VERSION "HNNBNNNYNNNNNNNNNNNNNNNNNNNNNNNNNNNNNNNNNN/4/%%%/4/'%**4NNN///"

NS_ :

BS_:

BU_: AWC BAP_Tester BMC_MLBevo BMS_MV BMS_NV DCDC_800V_PAG DCDC_HV DCDC_HV_02 DCDC_IHEV FCU_MLBevo_FCEV Gateway Gateway_PAG Ladegeraet_2 Ladegeraet_Konzern LE1 LE2 LE2_3_MLBevo_LB LE_MLBevo LE_MLBevo_LB Sub_Gateway TME

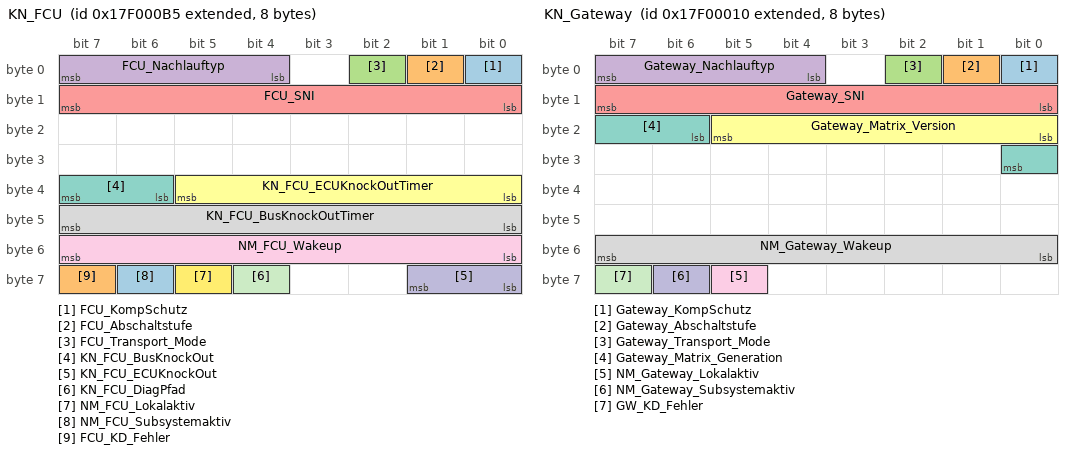
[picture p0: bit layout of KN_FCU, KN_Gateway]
BO_ 2549088437 KN_FCU: 8 FCU_MLBevo_FCEV
 SG_ FCU_KompSchutz : 0|1@1+ (1,0) [0|1] "" Vector__XXX
 SG_ FCU_Abschaltstufe : 1|1@1+ (1,0) [0|1] "" Vector__XXX
 SG_ FCU_Transport_Mode : 2|1@1+ (1,0) [0|1] "" Vector__XXX
 SG_ FCU_Nachlauftyp : 4|4@1+ (1,0) [0|15] ""  Gateway
 SG_ FCU_SNI : 8|8@1+ (1,0) [0|255] ""  Gateway
 SG_ KN_FCU_ECUKnockOutTimer : 32|6@1+ (1,0) [0|62] "Unit_Minut"  Gateway
 SG_ KN_FCU_BusKnockOut : 38|2@1+ (1,0) [0|3] ""  Gateway
 SG_ KN_FCU_BusKnockOutTimer : 40|8@1+ (1,0) [0|254] ""  Gateway
 SG_ NM_FCU_Wakeup : 48|8@1+ (1,0) [0|255] "" Vector__XXX
 SG_ KN_FCU_ECUKnockOut : 56|2@1+ (1,0) [0|3] ""  Gateway
 SG_ KN_FCU_DiagPfad : 60|1@1+ (1,0) [0|1] "" Vector__XXX
 SG_ NM_FCU_Lokalaktiv : 61|1@1+ (1,0) [0|1] ""  Gateway
 SG_ NM_FCU_Subsystemaktiv : 62|1@1+ (1,0) [0|1] ""  Gateway
 SG_ FCU_KD_Fehler : 63|1@1+ (1,0) [0|1] ""  Gateway

BO_ 2549088272 KN_Gateway: 8 Gateway
 SG_ Gateway_KompSchutz : 0|1@1+ (1,0) [0|1] "" Vector__XXX
 SG_ Gateway_Abschaltstufe : 1|1@1+ (1,0) [0|1] "" Vector__XXX
 SG_ Gateway_Transport_Mode : 2|1@1+ (1,0) [0|1] "" Vector__XXX
 SG_ Gateway_Nachlauftyp : 4|4@1+ (1,0) [0|15] "" Vector__XXX
 SG_ Gateway_SNI : 8|8@1+ (1,0) [0|255] "" Vector__XXX
 SG_ Gateway_Matrix_Version : 16|6@1+ (1,0) [0|63] "Unit_None" Vector__XXX
 SG_ Gateway_Matrix_Generation : 22|3@1+ (1,0) [0|7] "Unit_None" Vector__XXX
 SG_ NM_Gateway_Wakeup : 48|8@1+ (1,0) [0|255] "" Vector__XXX
 SG_ NM_Gateway_Lokalaktiv : 61|1@1+ (1,0) [0|1] "" Vector__XXX
 SG_ NM_Gateway_Subsystemaktiv : 62|1@1+ (1,0) [0|1] "" Vector__XXX
 SG_ GW_KD_Fehler : 63|1@1+ (1,0) [0|1] "" Vector__XXX

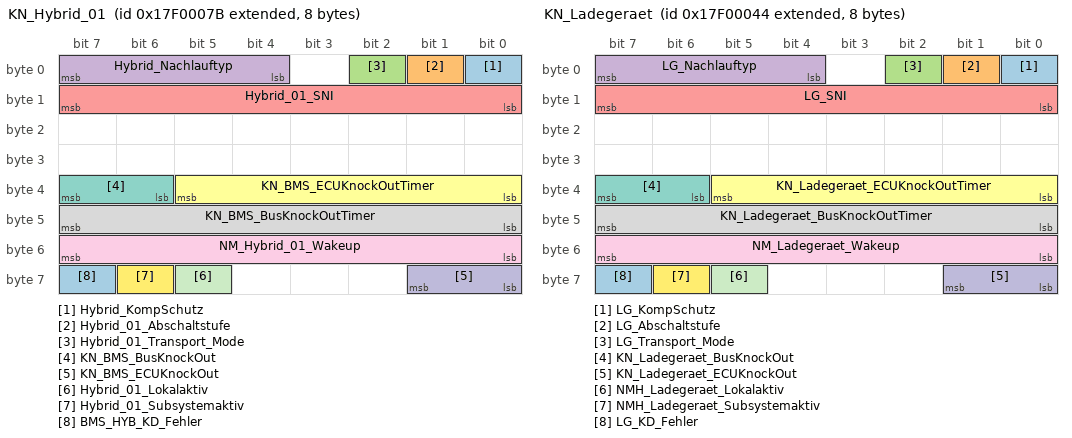
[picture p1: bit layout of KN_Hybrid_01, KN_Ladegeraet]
BO_ 2549088379 KN_Hybrid_01: 8 BMC_MLBevo
 SG_ Hybrid_KompSchutz : 0|1@1+ (1,0) [0|1] "" Vector__XXX
 SG_ Hybrid_01_Abschaltstufe : 1|1@1+ (1,0) [0|1] "" Vector__XXX
 SG_ Hybrid_01_Transport_Mode : 2|1@1+ (1,0) [0|1] "" Vector__XXX
 SG_ Hybrid_Nachlauftyp : 4|4@1+ (1,0) [0|15] ""  Gateway,Gateway_PAG
 SG_ Hybrid_01_SNI : 8|8@1+ (1,0) [0|255] ""  Gateway,Gateway_PAG
 SG_ KN_BMS_ECUKnockOutTimer : 32|6@1+ (1,0) [0|62] "Unit_Minut" Vector__XXX
 SG_ KN_BMS_BusKnockOut : 38|2@1+ (1,0) [0|3] "" Vector__XXX
 SG_ KN_BMS_BusKnockOutTimer : 40|8@1+ (1,0) [0|254] ""  Gateway,Gateway_PAG
 SG_ NM_Hybrid_01_Wakeup : 48|8@1+ (1,0) [0|255] "" Vector__XXX
 SG_ KN_BMS_ECUKnockOut : 56|2@1+ (1,0) [0|3] "" Vector__XXX
 SG_ Hybrid_01_Lokalaktiv : 61|1@1+ (1,0) [0|1] ""  Gateway,Gateway_PAG
 SG_ Hybrid_01_Subsystemaktiv : 62|1@1+ (1,0) [0|1] ""  Gateway,Gateway_PAG
 SG_ BMS_HYB_KD_Fehler : 63|1@1+ (1,0) [0|1] ""  Gateway,Gateway_PAG

BO_ 2549088324 KN_Ladegeraet: 8 Ladegeraet_Konzern
 SG_ LG_KompSchutz : 0|1@1+ (1,0) [0|1] "" Vector__XXX
 SG_ LG_Abschaltstufe : 1|1@1+ (1,0) [0|1] "" Vector__XXX
 SG_ LG_Transport_Mode : 2|1@1+ (1,0) [0|1] "" Vector__XXX
 SG_ LG_Nachlauftyp : 4|4@1+ (1,0) [0|15] ""  Gateway,Gateway_PAG
 SG_ LG_SNI : 8|8@1+ (1,0) [0|255] ""  Gateway,Gateway_PAG
 SG_ KN_Ladegeraet_ECUKnockOutTimer : 32|6@1+ (1,0) [0|62] "Unit_Minut"  Gateway
 SG_ KN_Ladegeraet_BusKnockOut : 38|2@1+ (1,0) [0|3] ""  Gateway
 SG_ KN_Ladegeraet_BusKnockOutTimer : 40|8@1+ (1,0) [0|254] ""  Gateway,Gateway_PAG
 SG_ NM_Ladegeraet_Wakeup : 48|8@1+ (1,0) [0|255] "" Vector__XXX
 SG_ KN_Ladegeraet_ECUKnockOut : 56|2@1+ (1,0) [0|3] ""  Gateway
 SG_ NMH_Ladegeraet_Lokalaktiv : 61|1@1+ (1,0) [0|1] ""  Gateway,Gateway_PAG
 SG_ NMH_Ladegeraet_Subsystemaktiv : 62|1@1+ (1,0) [0|1] "" Vector__XXX
 SG_ LG_KD_Fehler : 63|1@1+ (1,0) [0|1] ""  Gateway,Gateway_PAG

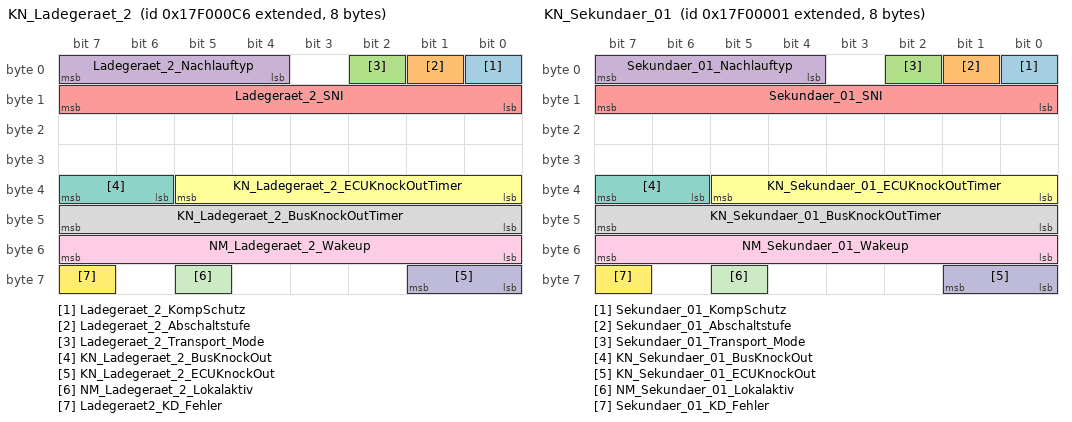
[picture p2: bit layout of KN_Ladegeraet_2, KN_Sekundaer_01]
BO_ 2549088454 KN_Ladegeraet_2: 8 Ladegeraet_2
 SG_ Ladegeraet_2_KompSchutz : 0|1@1+ (1,0) [0|1] "" Vector__XXX
 SG_ Ladegeraet_2_Abschaltstufe : 1|1@1+ (1,0) [0|1] "" Vector__XXX
 SG_ Ladegeraet_2_Transport_Mode : 2|1@1+ (1,0) [0|1] "" Vector__XXX
 SG_ Ladegeraet_2_Nachlauftyp : 4|4@1+ (1,0) [0|15] ""  Gateway,Gateway_PAG
 SG_ Ladegeraet_2_SNI : 8|8@1+ (1,0) [0|255] ""  Gateway,Gateway_PAG
 SG_ KN_Ladegeraet_2_ECUKnockOutTimer : 32|6@1+ (1,0) [0|62] "Unit_Minut" Vector__XXX
 SG_ KN_Ladegeraet_2_BusKnockOut : 38|2@1+ (1,0) [0|3] "" Vector__XXX
 SG_ KN_Ladegeraet_2_BusKnockOutTimer : 40|8@1+ (1,0) [0|254] ""  Gateway
 SG_ NM_Ladegeraet_2_Wakeup : 48|8@1+ (1,0) [0|255] "" Vector__XXX
 SG_ KN_Ladegeraet_2_ECUKnockOut : 56|2@1+ (1,0) [0|3] "" Vector__XXX
 SG_ NM_Ladegeraet_2_Lokalaktiv : 61|1@1+ (1,0) [0|1] ""  Gateway,Gateway_PAG
 SG_ Ladegeraet2_KD_Fehler : 63|1@1+ (1,0) [0|1] ""  Gateway,Gateway_PAG

BO_ 2549088257 KN_Sekundaer_01: 8 LE2
 SG_ Sekundaer_01_KompSchutz : 0|1@1+ (1,0) [0|1] "" Vector__XXX
 SG_ Sekundaer_01_Abschaltstufe : 1|1@1+ (1,0) [0|1] "" Vector__XXX
 SG_ Sekundaer_01_Transport_Mode : 2|1@1+ (1,0) [0|1] "" Vector__XXX
 SG_ Sekundaer_01_Nachlauftyp : 4|4@1+ (1,0) [0|15] ""  Gateway,Gateway_PAG
 SG_ Sekundaer_01_SNI : 8|8@1+ (1,0) [0|255] ""  Gateway,Gateway_PAG
 SG_ KN_Sekundaer_01_ECUKnockOutTimer : 32|6@1+ (1,0) [0|62] "Unit_Minut"  Gateway,Gateway_PAG
 SG_ KN_Sekundaer_01_BusKnockOut : 38|2@1+ (1,0) [0|3] ""  Gateway,Gateway_PAG
 SG_ KN_Sekundaer_01_BusKnockOutTimer : 40|8@1+ (1,0) [0|254] ""  Gateway,Gateway_PAG
 SG_ NM_Sekundaer_01_Wakeup : 48|8@1+ (1,0) [0|255] "" Vector__XXX
 SG_ KN_Sekundaer_01_ECUKnockOut : 56|2@1+ (1,0) [0|3] ""  Gateway,Gateway_PAG
 SG_ NM_Sekundaer_01_Lokalaktiv : 61|1@1+ (1,0) [0|1] ""  Gateway
 SG_ Sekundaer_01_KD_Fehler : 63|1@1+ (1,0) [0|1] ""  Gateway,Gateway_PAG

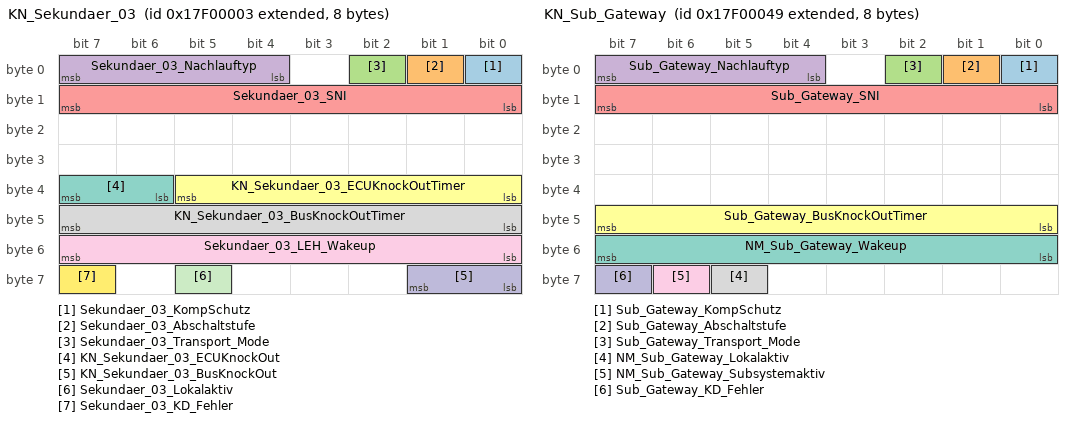
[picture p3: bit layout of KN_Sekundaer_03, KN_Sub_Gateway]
BO_ 2549088259 KN_Sekundaer_03: 8 LE1
 SG_ Sekundaer_03_KompSchutz : 0|1@1+ (1,0) [0|1] "" Vector__XXX
 SG_ Sekundaer_03_Abschaltstufe : 1|1@1+ (1,0) [0|1] "" Vector__XXX
 SG_ Sekundaer_03_Transport_Mode : 2|1@1+ (1,0) [0|1] "" Vector__XXX
 SG_ Sekundaer_03_Nachlauftyp : 4|4@1+ (1,0) [0|15] ""  Gateway,Gateway_PAG
 SG_ Sekundaer_03_SNI : 8|8@1+ (1,0) [0|255] ""  Gateway,Gateway_PAG
 SG_ KN_Sekundaer_03_ECUKnockOutTimer : 32|6@1+ (1,0) [0|62] "Unit_Minut"  Gateway,Gateway_PAG
 SG_ KN_Sekundaer_03_ECUKnockOut : 38|2@1+ (1,0) [0|3] ""  Gateway,Gateway_PAG
 SG_ KN_Sekundaer_03_BusKnockOutTimer : 40|8@1+ (1,0) [0|254] ""  Gateway,Gateway_PAG
 SG_ Sekundaer_03_LEH_Wakeup : 48|8@1+ (1,0) [0|255] "" Vector__XXX
 SG_ KN_Sekundaer_03_BusKnockOut : 56|2@1+ (1,0) [0|3] ""  Gateway,Gateway_PAG
 SG_ Sekundaer_03_Lokalaktiv : 61|1@1+ (1,0) [0|1] ""  Gateway
 SG_ Sekundaer_03_KD_Fehler : 63|1@1+ (1,0) [0|1] ""  Gateway,Gateway_PAG

BO_ 2549088329 KN_Sub_Gateway: 8 Sub_Gateway
 SG_ Sub_Gateway_KompSchutz : 0|1@1+ (1,0) [0|1] "" Vector__XXX
 SG_ Sub_Gateway_Abschaltstufe : 1|1@1+ (1,0) [0|1] "" Vector__XXX
 SG_ Sub_Gateway_Transport_Mode : 2|1@1+ (1,0) [0|1] "" Vector__XXX
 SG_ Sub_Gateway_Nachlauftyp : 4|4@1+ (1,0) [0|15] ""  Gateway,Gateway_PAG
 SG_ Sub_Gateway_SNI : 8|8@1+ (1,0) [0|255] ""  Gateway,Gateway_PAG
 SG_ Sub_Gateway_BusKnockOutTimer : 40|8@1+ (1,0) [0|254] "" Vector__XXX
 SG_ NM_Sub_Gateway_Wakeup : 48|8@1+ (1,0) [0|255] "" Vector__XXX
 SG_ NM_Sub_Gateway_Lokalaktiv : 61|1@1+ (1,0) [0|1] ""  Gateway
 SG_ NM_Sub_Gateway_Subsystemaktiv : 62|1@1+ (1,0) [0|1] ""  Gateway
 SG_ Sub_Gateway_KD_Fehler : 63|1@1+ (1,0) [0|1] ""  Gateway,Gateway_PAG

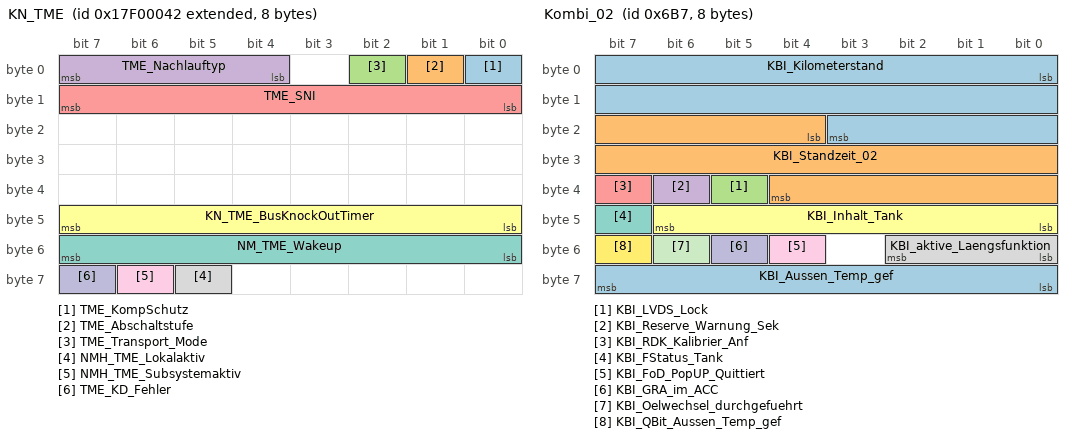
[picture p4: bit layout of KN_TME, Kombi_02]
BO_ 2549088322 KN_TME: 8 TME
 SG_ TME_KompSchutz : 0|1@1+ (1,0) [0|1] "" Vector__XXX
 SG_ TME_Abschaltstufe : 1|1@1+ (1,0) [0|1] "" Vector__XXX
 SG_ TME_Transport_Mode : 2|1@1+ (1,0) [0|1] "" Vector__XXX
 SG_ TME_Nachlauftyp : 4|4@1+ (1,0) [0|15] ""  Gateway,Gateway_PAG
 SG_ TME_SNI : 8|8@1+ (1,0) [0|255] ""  Gateway,Gateway_PAG
 SG_ KN_TME_BusKnockOutTimer : 40|8@1+ (1,0) [0|254] ""  Gateway,Gateway_PAG
 SG_ NM_TME_Wakeup : 48|8@1+ (1,0) [0|255] "" Vector__XXX
 SG_ NMH_TME_Lokalaktiv : 61|1@1+ (1,0) [0|1] ""  Gateway,Gateway_PAG
 SG_ NMH_TME_Subsystemaktiv : 62|1@1+ (1,0) [0|1] ""  Gateway,Gateway_PAG
 SG_ TME_KD_Fehler : 63|1@1+ (1,0) [0|1] ""  Gateway,Gateway_PAG

BO_ 779 Kombi_01: 8 Gateway
 SG_ KBI_ABS_Lampe : 0|1@1+ (1,0) [0|1] "" Vector__XXX
 SG_ KBI_ESP_Lampe : 1|1@1+ (1,0) [0|1] "" Vector__XXX
 SG_ KBI_BKL_Lampe : 2|1@1+ (1,0) [0|1] "" Vector__XXX
 SG_ KBI_Airbag_Lampe : 3|1@1+ (1,0) [0|1] "" Vector__XXX
 SG_ KBI_SILA_gueltig : 4|1@1+ (1,0) [0|1] "" Vector__XXX
 SG_ KBI_Lenkung_Lampe : 5|1@1+ (1,0) [0|1] "" Vector__XXX
 SG_ KBI_Vorglueh_System_Lampe : 6|1@1+ (1,0) [0|1] "" Vector__XXX
 SG_ KBI_NV_in_Anzeige : 7|1@1+ (1,0) [0|1] "" Vector__XXX
 SG_ Kombi_01_BZ : 8|4@1+ (1,0) [0|15] "" Vector__XXX
 SG_ KBI_Anzeigestatus_ACC : 12|1@1+ (1,0) [0|1] "" Vector__XXX
 SG_ KBI_Anzeigestatus_GRA : 13|2@1+ (1,0) [0|3] "" Vector__XXX
 SG_ KBI_Tankwarnung : 16|1@1+ (1,0) [0|1] ""  TME
 SG_ KBI_MFA_v_Einheit_01 : 17|1@1+ (1,0) [0|1] "" Vector__XXX
 SG_ KBI_im_Stellgliedtest : 18|1@1+ (1,0) [0|1] "" Vector__XXX
 SG_ KBI_Anzeigefehler_LDW : 19|2@1+ (1,0) [0|3] "" Vector__XXX
 SG_ KBI_Tankwarnung_ungueltig : 21|1@1+ (1,0) [0|1] "" Vector__XXX
 SG_ KBI_Handbremse : 23|1@1+ (1,0) [0|1] "" Vector__XXX
 SG_ KBI_V_Digital : 24|9@1+ (1,0) [0|511] "" Vector__XXX
 SG_ KBI_PLA_in_Anzeige : 33|1@1+ (1,0) [0|1] "" Vector__XXX
 SG_ KBI_Anzeigefehler_NV : 34|1@1+ (1,0) [0|1] "" Vector__XXX
 SG_ KBI_Anzeigestatus_LIM : 35|2@1+ (1,0) [0|3] "" Vector__XXX
 SG_ KBI_ARA_in_Anzeige : 37|1@1+ (1,0) [0|1] "" Vector__XXX
 SG_ KBI_Taster_Lift : 38|1@1+ (1,0) [0|1] "" Vector__XXX
 SG_ KBI_Taster_Fahrwerk : 39|1@1+ (1,0) [0|1] "" Vector__XXX
 SG_ KBI_angez_Geschw : 48|10@1+ (0.32,0) [0|325.12] "Unit_KiloMeterPerHour" Vector__XXX
 SG_ KBI_Einheit_Tacho : 58|1@1+ (1,0) [0|1] "" Vector__XXX
 SG_ KBI_Konsistenz_ACC : 59|1@1+ (1,0) [0|1] "" Vector__XXX
 SG_ KBI_Fehler_Anzeige_ACC : 60|1@1+ (1,0) [0|1] "" Vector__XXX
 SG_ KBI_Anzeigefehler_SWA : 61|2@1+ (1,0) [0|3] "" Vector__XXX
 SG_ KBI_Systemstatus : 63|1@1+ (1,0) [0|1] "" Vector__XXX

BO_ 1719 Kombi_02: 8 Gateway
 SG_ KBI_Kilometerstand : 0|20@1+ (1,0) [0|1048573] "Unit_KiloMeter"  Sub_Gateway
 SG_ KBI_Standzeit_02 : 20|17@1+ (1,0) [0|131068] "Unit_Secon"  Sub_Gateway,TME
 SG_ KBI_LVDS_Lock : 37|1@1+ (1,0) [0|1] ""  Sub_Gateway
 SG_ KBI_Reserve_Warnung_Sek : 38|1@1+ (1,0) [0|1] ""  Sub_Gateway
 SG_ KBI_RDK_Kalibrier_Anf : 39|1@1+ (1,0) [0|1] ""  Sub_Gateway
 SG_ KBI_Inhalt_Tank : 40|7@1+ (1,0) [0|125] "Unit_Liter"  Sub_Gateway
 SG_ KBI_FStatus_Tank : 47|1@1+ (1,0) [0|1] ""  Sub_Gateway
 SG_ KBI_aktive_Laengsfunktion : 48|3@1+ (1,0) [0|7] ""  Sub_Gateway
 SG_ KBI_FoD_PopUP_Quittiert : 52|1@1+ (1,0) [0|1] ""  Sub_Gateway
 SG_ KBI_GRA_im_ACC : 53|1@1+ (1,0) [0|1] ""  Sub_Gateway
 SG_ KBI_Oelwechsel_durchgefuehrt : 54|1@1+ (1,0) [0|1] ""  Sub_Gateway
 SG_ KBI_QBit_Aussen_Temp_gef : 55|1@1+ (1,0) [0|1] ""  AWC,Sub_Gateway
 SG_ KBI_Aussen_Temp_gef : 56|8@1+ (0.5,-50) [-50|75] "Unit_DegreCelsi"  AWC,Ladegeraet_Konzern,Sub_Gateway

BO_ 2549875067 KS_Hybrid_01_Req: 8 Gateway
 SG_ KS_Hybrid_01_Req_Data : 0|64@1+ (1,0) [0|1.84467440737096E+019] ""  BMC_MLBevo

BO_ 2550006139 KS_Hybrid_01_Resp: 8 BMC_MLBevo
 SG_ KS_Hybrid_01_Resp_Data : 0|64@1+ (1,0) [0|1.84467440737096E+019] ""  Gateway,Gateway_PAG

BO_ 2549875142 KS_Ladegeraet_2_Req: 8 Gateway
 SG_ KS_Ladegeraet_2_Req_Data : 0|64@1+ (1,0) [0|1.84467440737096E+019] ""  Ladegeraet_2

BO_ 2550006214 KS_Ladegeraet_2_Resp: 8 Ladegeraet_2
 SG_ KS_Ladegeraet_2_Resp_Data : 0|64@1+ (1,0) [0|1.84467440737096E+019] ""  Gateway,Gateway_PAG

BO_ 2549875012 KS_Ladegeraet_Req: 8 Gateway
 SG_ KS_Ladegeraet_Req_Data : 0|64@1+ (1,0) [0|1.84467440737096E+019] ""  Ladegeraet_Konzern

BO_ 2550006084 KS_Ladegeraet_Resp: 8 Ladegeraet_Konzern
 SG_ KS_Ladegeraet_Resp_Data : 0|64@1+ (1,0) [0|1.84467440737096E+019] ""  Gateway,Gateway_PAG

BO_ 2549899473 KS_SSN_CMC_01_Req: 8 Gateway
 SG_ KS_SSN_CMC_01_Req_Data : 0|64@1+ (1,0) [0|1.84467440737096E+019] ""  BMC_MLBevo

BO_ 2550030545 KS_SSN_CMC_01_Resp: 8 BMC_MLBevo
 SG_ KS_SSN_CMC_01_Resp_Data : 0|64@1+ (1,0) [0|1.84467440737096E+019] ""  Gateway

BO_ 2549899474 KS_SSN_CMC_02_Req: 8 Gateway
 SG_ KS_SSN_CMC_02_Req_Data : 0|64@1+ (1,0) [0|1.84467440737096E+019] ""  BMC_MLBevo

BO_ 2550030546 KS_SSN_CMC_02_Resp: 8 BMC_MLBevo
 SG_ KS_SSN_CMC_02_Resp_Data : 0|64@1+ (1,0) [0|1.84467440737096E+019] ""  Gateway

BO_ 2549899475 KS_SSN_CMC_03_Req: 8 Gateway
 SG_ KS_SSN_CMC_03_Req_Data : 0|64@1+ (1,0) [0|1.84467440737096E+019] ""  BMC_MLBevo

BO_ 2550030547 KS_SSN_CMC_03_Resp: 8 BMC_MLBevo
 SG_ KS_SSN_CMC_03_Resp_Data : 0|64@1+ (1,0) [0|1.84467440737096E+019] ""  Gateway

BO_ 2549899476 KS_SSN_CMC_04_Req: 8 Gateway
 SG_ KS_SSN_CMC_04_Req_Data : 0|64@1+ (1,0) [0|1.84467440737096E+019] ""  BMC_MLBevo

BO_ 2550030548 KS_SSN_CMC_04_Resp: 8 BMC_MLBevo
 SG_ KS_SSN_CMC_04_Resp_Data : 0|64@1+ (1,0) [0|1.84467440737096E+019] ""  Gateway

BO_ 2549899477 KS_SSN_CMC_05_Req: 8 Gateway
 SG_ KS_SSN_CMC_05_Req_Data : 0|64@1+ (1,0) [0|1.84467440737096E+019] ""  BMC_MLBevo

BO_ 2550030549 KS_SSN_CMC_05_Resp: 8 BMC_MLBevo
 SG_ KS_SSN_CMC_05_Resp_Data : 0|64@1+ (1,0) [0|1.84467440737096E+019] ""  Gateway

BO_ 2549899478 KS_SSN_CMC_06_Req: 8 Gateway
 SG_ KS_SSN_CMC_06_Req_Data : 0|64@1+ (1,0) [0|1.84467440737096E+019] ""  BMC_MLBevo

BO_ 2550030550 KS_SSN_CMC_06_Resp: 8 BMC_MLBevo
 SG_ KS_SSN_CMC_06_Resp_Data : 0|64@1+ (1,0) [0|1.84467440737096E+019] ""  Gateway

BO_ 2549899479 KS_SSN_CMC_07_Req: 8 Gateway
 SG_ KS_SSN_CMC_07_Req_Data : 0|64@1+ (1,0) [0|1.84467440737096E+019] ""  BMC_MLBevo

BO_ 2550030551 KS_SSN_CMC_07_Resp: 8 BMC_MLBevo
 SG_ KS_SSN_CMC_07_Resp_Data : 0|64@1+ (1,0) [0|1.84467440737096E+019] ""  Gateway

BO_ 2549899480 KS_SSN_CMC_08_Req: 8 Gateway
 SG_ KS_SSN_CMC_08_Req_Data : 0|64@1+ (1,0) [0|1.84467440737096E+019] ""  BMC_MLBevo

BO_ 2550030552 KS_SSN_CMC_08_Resp: 8 BMC_MLBevo
 SG_ KS_SSN_CMC_08_Resp_Data : 0|64@1+ (1,0) [0|1.84467440737096E+019] ""  Gateway

BO_ 2549899481 KS_SSN_CMC_09_Req: 8 Gateway
 SG_ KS_SSN_CMC_09_Req_Data : 0|64@1+ (1,0) [0|1.84467440737096E+019] ""  BMC_MLBevo

BO_ 2550030553 KS_SSN_CMC_09_Resp: 8 BMC_MLBevo
 SG_ KS_SSN_CMC_09_Resp_Data : 0|64@1+ (1,0) [0|1.84467440737096E+019] ""  Gateway

BO_ 2549899482 KS_SSN_CMC_10_Req: 8 Gateway
 SG_ KS_SSN_CMC_10_Req_Data : 0|64@1+ (1,0) [0|1.84467440737096E+019] ""  BMC_MLBevo

BO_ 2550030554 KS_SSN_CMC_10_Resp: 8 BMC_MLBevo
 SG_ KS_SSN_CMC_10_Resp_Data : 0|64@1+ (1,0) [0|1.84467440737096E+019] ""  Gateway

BO_ 2549899483 KS_SSN_CMC_11_Req: 8 Gateway
 SG_ KS_SSN_CMC_11_Req_Data : 0|64@1+ (1,0) [0|1.84467440737096E+019] ""  BMC_MLBevo

BO_ 2550030555 KS_SSN_CMC_11_Resp: 8 BMC_MLBevo
 SG_ KS_SSN_CMC_11_Resp_Data : 0|64@1+ (1,0) [0|1.84467440737096E+019] ""  Gateway

BO_ 2549899484 KS_SSN_CMC_12_Req: 8 Gateway
 SG_ KS_SSN_CMC_12_Req_Data : 0|64@1+ (1,0) [0|1.84467440737096E+019] ""  BMC_MLBevo

BO_ 2550030556 KS_SSN_CMC_12_Resp: 8 BMC_MLBevo
 SG_ KS_SSN_CMC_12_Resp_Data : 0|64@1+ (1,0) [0|1.84467440737096E+019] ""  Gateway

BO_ 2549899505 KS_SSN_CMC_13_Req: 8 Gateway
 SG_ KS_SSN_CMC_13_Req_Data : 0|64@1+ (1,0) [0|1.84467440737096E+019] ""  BMC_MLBevo

BO_ 2550030577 KS_SSN_CMC_13_Resp: 8 BMC_MLBevo
 SG_ KS_SSN_CMC_13_Resp_Data : 0|64@1+ (1,0) [0|1.84467440737096E+019] ""  Gateway

BO_ 2549899506 KS_SSN_CMC_14_Req: 8 Gateway
 SG_ KS_SSN_CMC_14_Req_Data : 0|64@1+ (1,0) [0|1.84467440737096E+019] ""  BMC_MLBevo

BO_ 2550030578 KS_SSN_CMC_14_Resp: 8 BMC_MLBevo
 SG_ KS_SSN_CMC_14_Resp_Data : 0|64@1+ (1,0) [0|1.84467440737096E+019] ""  Gateway

BO_ 2549899507 KS_SSN_CMC_15_Req: 8 Gateway
 SG_ KS_SSN_CMC_15_Req_Data : 0|64@1+ (1,0) [0|1.84467440737096E+019] ""  BMC_MLBevo

BO_ 2550030579 KS_SSN_CMC_15_Resp: 8 BMC_MLBevo
 SG_ KS_SSN_CMC_15_Resp_Data : 0|64@1+ (1,0) [0|1.84467440737096E+019] ""  Gateway

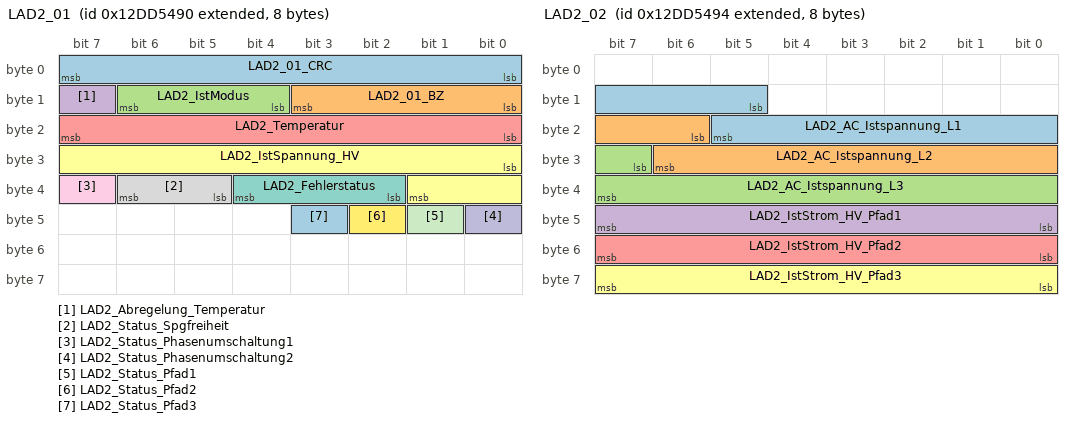
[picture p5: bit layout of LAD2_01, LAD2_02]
BO_ 2463978640 LAD2_01: 8 Ladegeraet_2
 SG_ LAD2_01_CRC : 0|8@1+ (1,0) [0|255] ""  Gateway,Gateway_PAG,Ladegeraet_Konzern
 SG_ LAD2_01_BZ : 8|4@1+ (1,0) [0|15] ""  Gateway,Gateway_PAG,Ladegeraet_Konzern
 SG_ LAD2_IstModus : 12|3@1+ (1,0) [0|7] ""  Ladegeraet_Konzern
 SG_ LAD2_Abregelung_Temperatur : 15|1@1+ (1,0) [0|1] ""  Ladegeraet_Konzern
 SG_ LAD2_Temperatur : 16|8@1+ (1,-40) [-40|213] "Unit_DegreCelsi"  Ladegeraet_Konzern
 SG_ LAD2_IstSpannung_HV : 24|10@1+ (1,0) [0|1021] "Unit_Volt"  Gateway,Gateway_PAG,Ladegeraet_Konzern
 SG_ LAD2_Fehlerstatus : 34|3@1+ (1,0) [0|7] ""  Gateway,Gateway_PAG,Ladegeraet_Konzern
 SG_ LAD2_Status_Spgfreiheit : 37|2@1+ (1,0) [0|3] ""  Gateway,Gateway_PAG,Ladegeraet_Konzern
 SG_ LAD2_Status_Phasenumschaltung1 : 39|1@1+ (1,0) [0|1] ""  Ladegeraet_Konzern
 SG_ LAD2_Status_Phasenumschaltung2 : 40|1@1+ (1,0) [0|1] ""  Ladegeraet_Konzern
 SG_ LAD2_Status_Pfad1 : 41|1@1+ (1,0) [0|1] ""  Ladegeraet_Konzern
 SG_ LAD2_Status_Pfad2 : 42|1@1+ (1,0) [0|1] ""  Ladegeraet_Konzern
 SG_ LAD2_Status_Pfad3 : 43|1@1+ (1,0) [0|1] ""  Ladegeraet_Konzern

BO_ 2463978644 LAD2_02: 8 Ladegeraet_2
 SG_ LAD2_AC_Istspannung_L1 : 13|9@1+ (1,0) [0|509] "Unit_Volt"  Ladegeraet_Konzern
 SG_ LAD2_AC_Istspannung_L2 : 22|9@1+ (1,0) [0|509] "Unit_Volt"  Ladegeraet_Konzern
 SG_ LAD2_AC_Istspannung_L3 : 31|9@1+ (1,0) [0|509] "Unit_Volt"  Ladegeraet_Konzern
 SG_ LAD2_IstStrom_HV_Pfad1 : 40|8@1+ (0.1,0) [0|25.3] "Unit_Amper"  Ladegeraet_Konzern
 SG_ LAD2_IstStrom_HV_Pfad2 : 48|8@1+ (0.1,0) [0|25.3] "Unit_Amper"  Ladegeraet_Konzern
 SG_ LAD2_IstStrom_HV_Pfad3 : 56|8@1+ (0.1,0) [0|25.3] "Unit_Amper"  Ladegeraet_Konzern

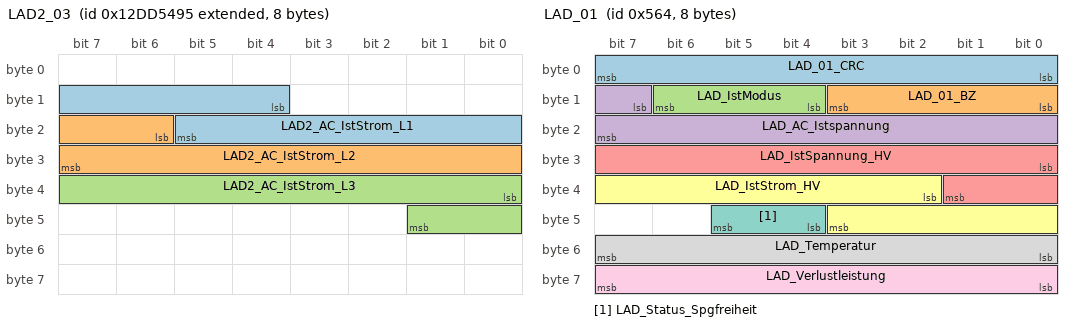
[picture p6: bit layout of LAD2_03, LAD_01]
BO_ 2463978645 LAD2_03: 8 Ladegeraet_2
 SG_ LAD2_AC_IstStrom_L1 : 12|10@1+ (0.1,0) [0|102.1] "Unit_Amper"  Ladegeraet_Konzern
 SG_ LAD2_AC_IstStrom_L2 : 22|10@1+ (0.1,0) [0|102.1] "Unit_Amper"  Ladegeraet_Konzern
 SG_ LAD2_AC_IstStrom_L3 : 32|10@1+ (0.1,0) [0|102.1] "Unit_Amper"  Ladegeraet_Konzern

BO_ 2589283493 LAD2_CALID_CVN: 8 Ladegeraet_2
 SG_ LAD2_CALID_CVN_MUX M : 0|2@1+ (1,0) [0|3] "Unit_None"  BMC_MLBevo
 SG_ LAD2_CVN_VLD : 7|1@1+ (1,0) [0|1] ""  BMC_MLBevo
 SG_ LAD2_CALID_Index_01 m0 : 8|8@1+ (1,0) [0|255] ""  BMC_MLBevo
 SG_ LAD2_CALID_Index_05 m1 : 8|8@1+ (1,0) [0|255] ""  BMC_MLBevo
 SG_ LAD2_CALID_Index_09 m2 : 8|8@1+ (1,0) [0|255] ""  BMC_MLBevo
 SG_ LAD2_CALID_Index_13 m3 : 8|8@1+ (1,0) [0|255] ""  BMC_MLBevo
 SG_ LAD2_CALID_Index_02 m0 : 16|8@1+ (1,0) [0|255] ""  BMC_MLBevo
 SG_ LAD2_CALID_Index_06 m1 : 16|8@1+ (1,0) [0|255] ""  BMC_MLBevo
 SG_ LAD2_CALID_Index_10 m2 : 16|8@1+ (1,0) [0|255] ""  BMC_MLBevo
 SG_ LAD2_CALID_Index_14 m3 : 16|8@1+ (1,0) [0|255] ""  BMC_MLBevo
 SG_ LAD2_CALID_Index_03 m0 : 24|8@1+ (1,0) [0|255] ""  BMC_MLBevo
 SG_ LAD2_CALID_Index_07 m1 : 24|8@1+ (1,0) [0|255] ""  BMC_MLBevo
 SG_ LAD2_CALID_Index_11 m2 : 24|8@1+ (1,0) [0|255] ""  BMC_MLBevo
 SG_ LAD2_CALID_Index_15 m3 : 24|8@1+ (1,0) [0|255] ""  BMC_MLBevo
 SG_ LAD2_CALID_Index_04 m0 : 32|8@1+ (1,0) [0|255] ""  BMC_MLBevo
 SG_ LAD2_CALID_Index_08 m1 : 32|8@1+ (1,0) [0|255] ""  BMC_MLBevo
 SG_ LAD2_CALID_Index_12 m2 : 32|8@1+ (1,0) [0|255] ""  BMC_MLBevo
 SG_ LAD2_CALID_Index_16 m3 : 32|8@1+ (1,0) [0|255] ""  BMC_MLBevo
 SG_ LAD2_CVN_Byte_1 m0 : 40|8@1+ (1,0) [0|255] ""  BMC_MLBevo
 SG_ LAD2_CVN_Byte_2 m1 : 40|8@1+ (1,0) [0|255] ""  BMC_MLBevo
 SG_ LAD2_CVN_Byte_3 m2 : 40|8@1+ (1,0) [0|255] ""  BMC_MLBevo
 SG_ LAD2_CVN_Byte_4 m3 : 40|8@1+ (1,0) [0|255] ""  BMC_MLBevo

BO_ 2589283392 LAD2_KomponentenFehler_01: 8 Ladegeraet_2
 SG_ LAD2_KomponentenFehler_01 : 24|2@1+ (1,0) [0|3] ""  BMC_MLBevo
 SG_ LAD2_KomponentenFehler_02 : 26|2@1+ (1,0) [0|3] ""  BMC_MLBevo
 SG_ LAD2_KomponentenFehler_03 : 28|2@1+ (1,0) [0|3] ""  BMC_MLBevo
 SG_ LAD2_KomponentenFehler_04 : 30|2@1+ (1,0) [0|3] ""  BMC_MLBevo
 SG_ LAD2_KomponentenFehler_05 : 32|2@1+ (1,0) [0|3] ""  BMC_MLBevo
 SG_ LAD2_KomponentenFehler_06 : 34|2@1+ (1,0) [0|3] ""  BMC_MLBevo
 SG_ LAD2_KomponentenFehler_07 : 36|2@1+ (1,0) [0|3] ""  BMC_MLBevo
 SG_ LAD2_KomponentenFehler_08 : 38|2@1+ (1,0) [0|3] ""  BMC_MLBevo
 SG_ LAD2_KomponentenFehler_09 : 40|2@1+ (1,0) [0|3] ""  BMC_MLBevo
 SG_ LAD2_KomponentenFehler_10 : 42|2@1+ (1,0) [0|3] ""  BMC_MLBevo
 SG_ LAD2_KomponentenFehler_11 : 44|2@1+ (1,0) [0|3] ""  BMC_MLBevo
 SG_ LAD2_KomponentenFehler_12 : 46|2@1+ (1,0) [0|3] ""  BMC_MLBevo
 SG_ LAD2_KomponentenFehler_13 : 48|2@1+ (1,0) [0|3] ""  BMC_MLBevo
 SG_ LAD2_KomponentenFehler_14 : 50|2@1+ (1,0) [0|3] ""  BMC_MLBevo
 SG_ LAD2_KomponentenFehler_15 : 52|2@1+ (1,0) [0|3] ""  BMC_MLBevo
 SG_ LAD2_KomponentenFehler_16 : 54|2@1+ (1,0) [0|3] ""  BMC_MLBevo
 SG_ LAD2_KomponentenFehler_17 : 56|2@1+ (1,0) [0|3] ""  BMC_MLBevo
 SG_ LAD2_KomponentenFehler_18 : 58|2@1+ (1,0) [0|3] ""  BMC_MLBevo
 SG_ LAD2_KomponentenFehler_19 : 60|2@1+ (1,0) [0|3] ""  BMC_MLBevo
 SG_ LAD2_KomponentenFehler_20 : 62|2@1+ (1,0) [0|3] ""  BMC_MLBevo

BO_ 2589283688 LAD2_Version: 8 Ladegeraet_2
 SG_ LAD2_Version : 0|2@1+ (1,0) [0|3] ""  Ladegeraet_Konzern
 SG_ LAD2_Version_MUX M : 6|2@1+ (1,0) [0|3] "Unit_None"  Ladegeraet_Konzern
 SG_ LAD2_Version_Index_01 m0 : 8|5@1+ (1,0) [0|31] ""  Ladegeraet_Konzern
 SG_ LAD2_Version_Index_02 m1 : 8|5@1+ (1,0) [0|31] ""  Ladegeraet_Konzern
 SG_ LAD2_Version_Index_03 m2 : 8|5@1+ (1,0) [0|31] ""  Ladegeraet_Konzern
 SG_ LAD2_Version_Index_04 m3 : 8|5@1+ (1,0) [0|31] ""  Ladegeraet_Konzern

BO_ 1380 LAD_01: 8 Ladegeraet_Konzern
 SG_ LAD_01_CRC : 0|8@1+ (1,0) [0|255] ""  Gateway,Gateway_PAG
 SG_ LAD_01_BZ : 8|4@1+ (1,0) [0|15] ""  Gateway,Gateway_PAG
 SG_ LAD_IstModus : 12|3@1+ (1,0) [0|7] ""  Gateway,Gateway_PAG,Ladegeraet_2,TME
 SG_ LAD_AC_Istspannung : 15|9@1+ (1,0) [0|509] "Unit_Volt"  Gateway_PAG
 SG_ LAD_IstSpannung_HV : 24|10@1+ (1,0) [0|1021] "Unit_Volt"  Gateway_PAG
 SG_ LAD_IstStrom_HV : 34|10@1+ (0.2,-102) [-102|102.2] "Unit_Amper"  Gateway,Gateway_PAG
 SG_ LAD_Status_Spgfreiheit : 44|2@1+ (1,0) [0|3] ""  Gateway,Gateway_PAG
 SG_ LAD_Temperatur : 48|8@1+ (1,-40) [-40|213] "Unit_DegreCelsi"  Gateway_PAG,TME
 SG_ LAD_Verlustleistung : 56|8@1+ (20,0) [0|5060] "Unit_Watt"  Gateway_PAG,TME

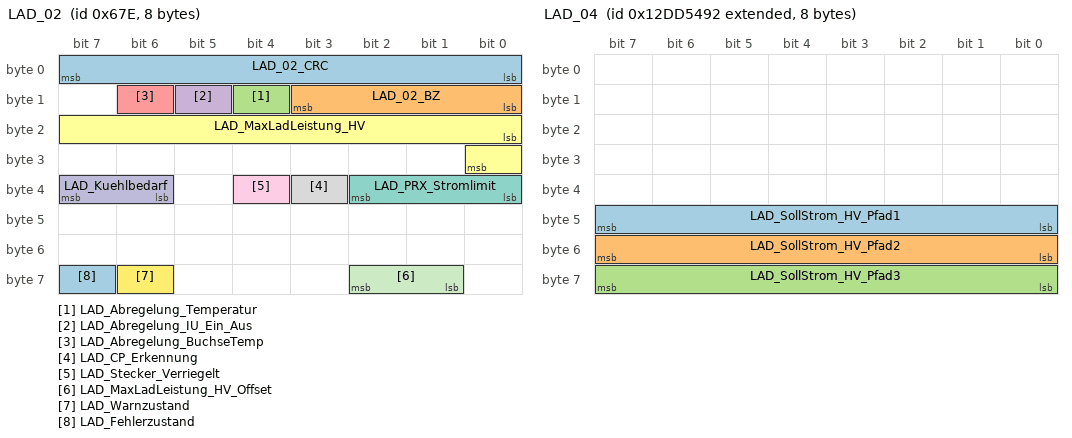
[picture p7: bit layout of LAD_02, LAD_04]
BO_ 1662 LAD_02: 8 Ladegeraet_Konzern
 SG_ LAD_02_CRC : 0|8@1+ (1,0) [0|255] ""  Gateway,Gateway_PAG
 SG_ LAD_02_BZ : 8|4@1+ (1,0) [0|15] ""  Gateway,Gateway_PAG
 SG_ LAD_Abregelung_Temperatur : 12|1@1+ (1,0) [0|1] ""  TME
 SG_ LAD_Abregelung_IU_Ein_Aus : 13|1@1+ (1,0) [0|1] "" Vector__XXX
 SG_ LAD_Abregelung_BuchseTemp : 14|1@1+ (1,0) [0|1] "" Vector__XXX
 SG_ LAD_MaxLadLeistung_HV : 16|9@1+ (100,0) [0|50900] "Unit_Watt"  TME
 SG_ LAD_PRX_Stromlimit : 32|3@1+ (1,0) [0|7] "" Vector__XXX
 SG_ LAD_CP_Erkennung : 35|1@1+ (1,0) [0|1] "" Vector__XXX
 SG_ LAD_Stecker_Verriegelt : 36|1@1+ (1,0) [0|1] "" Vector__XXX
 SG_ LAD_Kuehlbedarf : 38|2@1+ (1,0) [0|3] "" Vector__XXX
 SG_ LAD_MaxLadLeistung_HV_Offset : 57|2@1+ (1,0) [0|3] "" Vector__XXX
 SG_ LAD_Warnzustand : 62|1@1+ (1,0) [0|1] "" Vector__XXX
 SG_ LAD_Fehlerzustand : 63|1@1+ (1,0) [0|1] "" Vector__XXX

BO_ 2463978642 LAD_04: 8 Ladegeraet_Konzern
 SG_ LAD_SollStrom_HV_Pfad1 : 40|8@1+ (0.1,0) [0|25.3] "Unit_Amper"  Ladegeraet_2
 SG_ LAD_SollStrom_HV_Pfad2 : 48|8@1+ (0.1,0) [0|25.3] "Unit_Amper"  Ladegeraet_2
 SG_ LAD_SollStrom_HV_Pfad3 : 56|8@1+ (0.1,0) [0|25.3] "Unit_Amper"  Ladegeraet_2

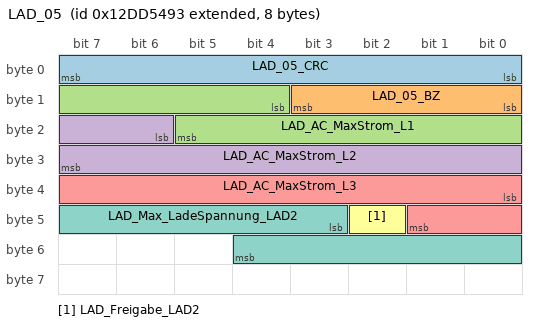
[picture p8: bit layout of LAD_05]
BO_ 2463978643 LAD_05: 8 Ladegeraet_Konzern
 SG_ LAD_05_CRC : 0|8@1+ (1,0) [0|255] ""  Ladegeraet_2
 SG_ LAD_05_BZ : 8|4@1+ (1,0) [0|15] ""  Ladegeraet_2
 SG_ LAD_AC_MaxStrom_L1 : 12|10@1+ (0.1,0) [0|102.1] "Unit_Amper"  Ladegeraet_2
 SG_ LAD_AC_MaxStrom_L2 : 22|10@1+ (0.1,0) [0|102.1] "Unit_Amper"  Ladegeraet_2
 SG_ LAD_AC_MaxStrom_L3 : 32|10@1+ (0.1,0) [0|102.1] "Unit_Amper"  Ladegeraet_2
 SG_ LAD_Freigabe_LAD2 : 42|1@1+ (1,0) [0|1] ""  Ladegeraet_2
 SG_ LAD_Max_LadeSpannung_LAD2 : 43|10@1+ (1,0) [0|1021] "Unit_Volt"  Ladegeraet_2

BO_ 2589283663 LAD_06: 8 Ladegeraet_Konzern
 SG_ LAD_PlanAntw_Verlustleistung : 48|12@1+ (50,0) [0|204650] "Unit_Watt"  TME
 SG_ LAD_PlanAntw_Zaehler : 60|4@1+ (1,0) [0|13] "Unit_None"  TME

BO_ 2589283415 LAD_CALID_CVN: 8 Ladegeraet_Konzern
 SG_ LAD_CALID_CVN_MUX M : 0|2@1+ (1,0) [0|3] "Unit_None"  BMC_MLBevo
 SG_ LAD_CVN_VLD : 7|1@1+ (1,0) [0|1] ""  BMC_MLBevo
 SG_ LAD_CALID_Index_01 m0 : 8|8@1+ (1,0) [0|255] ""  BMC_MLBevo
 SG_ LAD_CALID_Index_05 m1 : 8|8@1+ (1,0) [0|255] ""  BMC_MLBevo
 SG_ LAD_CALID_Index_09 m2 : 8|8@1+ (1,0) [0|255] ""  BMC_MLBevo
 SG_ LAD_CALID_Index_13 m3 : 8|8@1+ (1,0) [0|255] ""  BMC_MLBevo
 SG_ LAD_CALID_Index_02 m0 : 16|8@1+ (1,0) [0|255] ""  BMC_MLBevo
 SG_ LAD_CALID_Index_06 m1 : 16|8@1+ (1,0) [0|255] ""  BMC_MLBevo
 SG_ LAD_CALID_Index_10 m2 : 16|8@1+ (1,0) [0|255] ""  BMC_MLBevo
 SG_ LAD_CALID_Index_14 m3 : 16|8@1+ (1,0) [0|255] ""  BMC_MLBevo
 SG_ LAD_CALID_Index_03 m0 : 24|8@1+ (1,0) [0|255] ""  BMC_MLBevo
 SG_ LAD_CALID_Index_07 m1 : 24|8@1+ (1,0) [0|255] ""  BMC_MLBevo
 SG_ LAD_CALID_Index_11 m2 : 24|8@1+ (1,0) [0|255] ""  BMC_MLBevo
 SG_ LAD_CALID_Index_15 m3 : 24|8@1+ (1,0) [0|255] ""  BMC_MLBevo
 SG_ LAD_CALID_Index_04 m0 : 32|8@1+ (1,0) [0|255] ""  BMC_MLBevo
 SG_ LAD_CALID_Index_08 m1 : 32|8@1+ (1,0) [0|255] ""  BMC_MLBevo
 SG_ LAD_CALID_Index_12 m2 : 32|8@1+ (1,0) [0|255] ""  BMC_MLBevo
 SG_ LAD_CALID_Index_16 m3 : 32|8@1+ (1,0) [0|255] ""  BMC_MLBevo
 SG_ LAD_CVN_Byte_1 m0 : 40|8@1+ (1,0) [0|255] ""  BMC_MLBevo
 SG_ LAD_CVN_Byte_2 m1 : 40|8@1+ (1,0) [0|255] ""  BMC_MLBevo
 SG_ LAD_CVN_Byte_3 m2 : 40|8@1+ (1,0) [0|255] ""  BMC_MLBevo
 SG_ LAD_CVN_Byte_4 m3 : 40|8@1+ (1,0) [0|255] ""  BMC_MLBevo

BO_ 2589283472 LAD_Komponentenfehler: 8 Ladegeraet_Konzern
 SG_ LAD_KomponentenFehler_01 : 0|2@1+ (1,0) [0|3] ""  BMC_MLBevo
 SG_ LAD_KomponentenFehler_02 : 2|2@1+ (1,0) [0|3] ""  BMC_MLBevo
 SG_ LAD_KomponentenFehler_03 : 4|2@1+ (1,0) [0|3] ""  BMC_MLBevo
 SG_ LAD_KomponentenFehler_04 : 6|2@1+ (1,0) [0|3] ""  BMC_MLBevo
 SG_ LAD_KomponentenFehler_05 : 8|2@1+ (1,0) [0|3] ""  BMC_MLBevo
 SG_ LAD_KomponentenFehler_06 : 10|2@1+ (1,0) [0|3] ""  BMC_MLBevo
 SG_ LAD_KomponentenFehler_07 : 12|2@1+ (1,0) [0|3] ""  BMC_MLBevo
 SG_ LAD_KomponentenFehler_08 : 14|2@1+ (1,0) [0|3] ""  BMC_MLBevo
 SG_ LAD_KomponentenFehler_09 : 16|2@1+ (1,0) [0|3] ""  BMC_MLBevo
 SG_ LAD_KomponentenFehler_10 : 18|2@1+ (1,0) [0|3] ""  BMC_MLBevo
 SG_ LAD_KomponentenFehler_11 : 20|2@1+ (1,0) [0|3] ""  BMC_MLBevo
 SG_ LAD_KomponentenFehler_12 : 22|2@1+ (1,0) [0|3] ""  BMC_MLBevo
 SG_ LAD_KomponentenFehler_13 : 24|2@1+ (1,0) [0|3] ""  BMC_MLBevo
 SG_ LAD_KomponentenFehler_14 : 26|2@1+ (1,0) [0|3] ""  BMC_MLBevo
 SG_ LAD_KomponentenFehler_15 : 28|2@1+ (1,0) [0|3] ""  BMC_MLBevo
 SG_ LAD_KomponentenFehler_16 : 30|2@1+ (1,0) [0|3] ""  BMC_MLBevo
 SG_ LAD_KomponentenFehler_17 : 32|2@1+ (1,0) [0|3] ""  BMC_MLBevo
 SG_ LAD_KomponentenFehler_18 : 34|2@1+ (1,0) [0|3] ""  BMC_MLBevo
 SG_ LAD_KomponentenFehler_19 : 36|2@1+ (1,0) [0|3] ""  BMC_MLBevo
 SG_ LAD_KomponentenFehler_20 : 38|2@1+ (1,0) [0|3] ""  BMC_MLBevo
 SG_ LAD_KomponentenFehler_21 : 40|2@1+ (1,0) [0|3] ""  BMC_MLBevo
 SG_ LAD_KomponentenFehler_22 : 42|2@1+ (1,0) [0|3] ""  BMC_MLBevo
 SG_ LAD_KomponentenFehler_23 : 44|2@1+ (1,0) [0|3] ""  BMC_MLBevo
 SG_ LAD_KomponentenFehler_24 : 46|2@1+ (1,0) [0|3] ""  BMC_MLBevo
 SG_ LAD_KomponentenFehler_25 : 48|2@1+ (1,0) [0|3] ""  BMC_MLBevo
 SG_ LAD_KomponentenFehler_26 : 50|2@1+ (1,0) [0|3] ""  BMC_MLBevo
 SG_ LAD_KomponentenFehler_27 : 52|2@1+ (1,0) [0|3] ""  BMC_MLBevo
 SG_ LAD_KomponentenFehler_28 : 54|2@1+ (1,0) [0|3] ""  BMC_MLBevo
 SG_ LAD_KomponentenFehler_29 : 56|2@1+ (1,0) [0|3] ""  BMC_MLBevo
 SG_ LAD_KomponentenFehler_30 : 58|2@1+ (1,0) [0|3] ""  BMC_MLBevo
 SG_ LAD_KomponentenFehler_31 : 60|2@1+ (1,0) [0|3] ""  BMC_MLBevo
 SG_ LAD_KomponentenFehler_32 : 62|2@1+ (1,0) [0|3] ""  BMC_MLBevo

BO_TX_BU_ 2549088272 : Gateway,Gateway_PAG;
BO_TX_BU_ 2549088257 : LE2,LE2_3_MLBevo_LB;
BO_TX_BU_ 2549088259 : LE1,LE_MLBevo;
BO_TX_BU_ 779 : Gateway,Gateway_PAG;
BO_TX_BU_ 1719 : Gateway,Gateway_PAG;
BO_TX_BU_ 2549875067 : Gateway,Gateway_PAG;
BO_TX_BU_ 2549875142 : Gateway,Gateway_PAG;
BO_TX_BU_ 2549875012 : Gateway,Gateway_PAG;
CM_ SG_ 2549088437 FCU_KompSchutz "Funktionseinschränkung aufgrund Komponentenschutz aktiv";
CM_ SG_ 2549088437 FCU_Abschaltstufe "Funktionseinschränkung aufgrund aktiver Abschaltstufe";
CM_ SG_ 2549088437 FCU_Transport_Mode "Funktionseinschränkung aufgrund aktivem Transport Mode und/oder Transport Schutz";
CM_ SG_ 2549088437 FCU_Nachlauftyp "Abgebildet wird die von der Hardware vorgegebene Möglichkeit, die Kommunikation nach Klemme 15 = AUS aufrecht zu erhalten. Es wird ein Init-Wert gesendet.
0 = Kommunikation nur bei KL15=EIN (kein Nachlauf, nicht weckfähig)
1 = Kommunikation nach KL15=AU";
CM_ SG_ 2549088437 FCU_SNI "Source Node-Identifier (SNI) identifiziert den Sender der NM-Botschaft (Knotenadresse) eindeutig im Fahrzeug";
CM_ SG_ 2549088437 KN_FCU_ECUKnockOutTimer "Ausgabe des ECUKnockOut-Timer in der Knotenbotschaft";
CM_ SG_ 2549088437 KN_FCU_BusKnockOut "Ausgabe des BusKnockout-Status in der Knotenbotschaft";
CM_ SG_ 2549088437 KN_FCU_BusKnockOutTimer "Ausgabe des BusKnockOut-Timer in der Knotenbotschaft";
CM_ SG_ 2549088437 NM_FCU_Wakeup "enthält die Weckursache; stehen mehrere Weckursachen parallel an, dann muss der kleinste Wert übertragen werden";
CM_ SG_ 2549088437 KN_FCU_ECUKnockOut "Ausgabe des ECUKnockout-Status in der Knotenbotschaft";
CM_ SG_ 2549088437 KN_FCU_DiagPfad "Kennzeichnung der Diagnosefähigkeit des BusInterfaces eines Steuergerätes (Knoten)
Umfang LAH 80127

Bei Nutzung des Signal explizit pro angebundenem BusInterface zu setzen:
MQB auf A-CAN = 0 (aktiv)";
CM_ SG_ 2549088437 NM_FCU_Lokalaktiv "Zeigt an ob Steuergerät bei Kl15 aus dauerhaft lokal aktiv war, siehe QLAH Abschaltungen Ruhestrommanagement";
CM_ SG_ 2549088437 NM_FCU_Subsystemaktiv "Zeigt an ob Steuergerät bei Kl15 aus dauerhaft lokal aktiv war, siehe QLAH Abschaltungen Ruhestrommanagement";
CM_ SG_ 2549088437 FCU_KD_Fehler "Bei gesetztem Bit ist mindestens ein Kundendienstfehler eingetragen";
CM_ SG_ 2549088272 Gateway_KompSchutz "Funktionseinschränkung aufgrund Komponentenschutz aktiv";
CM_ SG_ 2549088272 Gateway_Abschaltstufe "Funktionseinschränkung aufgrund aktiver Abschaltstufe";
CM_ SG_ 2549088272 Gateway_Transport_Mode "Funktionseinschränkung aufgrund aktivem Transport Mode und/oder Transport Schutz";
CM_ SG_ 2549088272 Gateway_Nachlauftyp "Abgebildet wird die von der Hardware vorgegebene Möglichkeit, die Kommunikation nach Klemme 15 = AUS aufrecht zu erhalten. Es wird ein Init-Wert gesendet.
0 = Kommunikation nur bei KL15=EIN (kein Nachlauf, nicht weckfähig)
1 = Kommunikation nach KL15=AU";
CM_ SG_ 2549088272 Gateway_SNI "Das Signal beinhaltet den Source Node Identifier (Knotenadresse, die auch in der Abbildungsvorschrift zur CAN-ID für die NM-High Botschaft verwendet wird).";
CM_ SG_ 2549088272 Gateway_Matrix_Version "Signal gibt an welche Matrix-Version des Baukasten umgesetzt ist.
z.B. V.08.xx, das Signal gibt den Wert für xx an";
CM_ SG_ 2549088272 Gateway_Matrix_Generation "Signal gibt an welche Matrix-Generation umgesetzt ist";
CM_ SG_ 2549088272 NM_Gateway_Wakeup "enthält die Weckursache; stehen mehrere Weckursachen parallel an, dann muss der kleinste Wert übertragen werden";
CM_ SG_ 2549088272 NM_Gateway_Lokalaktiv "Zeigt an ob das SG nach Klemme15 AUS und nach entsprechender MAX Aktivzeit noch aktiv war";
CM_ SG_ 2549088272 NM_Gateway_Subsystemaktiv "Zeigt an ob ein Subsystem des SGs nach Klemme15 AUS und nach entsprechender MAX Aktivzeit noch aktiv war";
CM_ SG_ 2549088272 GW_KD_Fehler "Kundendienstfehlerbit Gateway zur Anzeige eines im Gateway abgelegten Fehlerspeichereintrages.";
CM_ SG_ 2549088379 Hybrid_KompSchutz "Funktionseinschränkung aufgrund Komponentenschutz aktiv";
CM_ SG_ 2549088379 Hybrid_01_Abschaltstufe "Funktionseinschränkung aufgrund aktiver Abschaltstufe";
CM_ SG_ 2549088379 Hybrid_01_Transport_Mode "Funktionseinschränkung aufgrund aktivem Transport Mode und/oder Transport Schutz";
CM_ SG_ 2549088379 Hybrid_Nachlauftyp "Abgebildet wird die von der Hardware vorgegebene Möglichkeit, die Kommunikation nach Klemme 15 = AUS aufrecht zu erhalten. Es wird ein Init-Wert gesendet.
0 = Kommunikation nur bei KL15=EIN (kein Nachlauf, nicht weckfähig)
1 = Kommunikation nach KL15=AU";
CM_ SG_ 2549088379 Hybrid_01_SNI "Das Signal beinhaltet den Source Node Identifier (Knotenadresse, die auch in der Abbildungsvorschrift zur CAN-ID für die NM-High Botschaft verwendet wird).";
CM_ SG_ 2549088379 KN_BMS_ECUKnockOutTimer "Ausgabe des ECUKnockOut-Timer in der Knotenbotschaft";
CM_ SG_ 2549088379 KN_BMS_BusKnockOut "Ausgabe des BusKnockOut-Status in der Knotenbotschaft";
CM_ SG_ 2549088379 KN_BMS_BusKnockOutTimer "Ausgabe des BusKnockOut-Timer in der Knotenbotschaft";
CM_ SG_ 2549088379 NM_Hybrid_01_Wakeup "enthält die Weckursache; stehen mehrere Weckursachen parallel an, dann muss der kleinste Wert übertragen werden";
CM_ SG_ 2549088379 KN_BMS_ECUKnockOut "Ausgabe des ECUKnockOut-Status in der Knotenbotschaft";
CM_ SG_ 2549088379 Hybrid_01_Lokalaktiv "Zeigt an ob das SG nach Klemme15 AUS und nach entsprechender MAX Aktivzeit noch aktiv war";
CM_ SG_ 2549088379 Hybrid_01_Subsystemaktiv "Zeigt an ob ein Subsystem des SGs nach Klemme15 AUS und nach entsprechender MAX Aktivzeit noch aktiv war";
CM_ SG_ 2549088379 BMS_HYB_KD_Fehler "Bei gesetztem Bit ist mindestens ein Kundendienstfehler eingetragen";
CM_ SG_ 2549088324 LG_KompSchutz "Funktionseinschränkung aufgrund Komponentenschutz aktiv";
CM_ SG_ 2549088324 LG_Abschaltstufe "Funktionseinschränkung aufgrund aktiver Abschaltstufe";
CM_ SG_ 2549088324 LG_Transport_Mode "Funktionseinschränkung aufgrund aktivem Transport Mode und/oder Transport Schutz";
CM_ SG_ 2549088324 LG_Nachlauftyp "Abgebildet wird die von der Hardware vorgegebene Möglichkeit, die Kommunikation nach Klemme 15 = AUS aufrecht zu erhalten. Es wird ein Init-Wert gesendet.
0 = Kommunikation nur bei KL15=EIN (kein Nachlauf, nicht weckfähig)
1 = Kommunikation nach KL15=AU";
CM_ SG_ 2549088324 LG_SNI "Das Signal beinhaltet den Source Node Identifier (Knotenadresse, die auch in der Abbildungsvorschrift zur CAN-ID für die NM-High Botschaft verwendet wird).";
CM_ SG_ 2549088324 KN_Ladegeraet_ECUKnockOutTimer "Ausgabe des ECUKnockOut-Timer in der Knotenbotschaft";
CM_ SG_ 2549088324 KN_Ladegeraet_BusKnockOut "Ausgabe des BusKnockout-Status in der Knotenbotschaft";
CM_ SG_ 2549088324 KN_Ladegeraet_BusKnockOutTimer "Ausgabe des BusKnockOut-Timer in der Knotenbotschaft";
CM_ SG_ 2549088324 NM_Ladegeraet_Wakeup "enthält die Weckursache; stehen mehrere Weckursachen parallel an, dann muss der kleinste Wert übertragen werden";
CM_ SG_ 2549088324 KN_Ladegeraet_ECUKnockOut "Ausgabe des ECUKnockout-Status in der Knotenbotschaft";
CM_ SG_ 2549088324 NMH_Ladegeraet_Lokalaktiv "Zeigt an ob Steuergerät lokal aktiv war";
CM_ SG_ 2549088324 NMH_Ladegeraet_Subsystemaktiv "Zeigt an ob ein Subsystem des SGs nach Klemme15 AUS und nach entsprechender MAX Aktivzeit noch aktiv war";
CM_ SG_ 2549088324 LG_KD_Fehler "Bei gesetztem Bit ist mindestens ein Kundendienstfehler eingetragen";
CM_ SG_ 2549088454 Ladegeraet_2_KompSchutz "Funktionseinschränkung aufgrund Komponentenschutz aktiv";
CM_ SG_ 2549088454 Ladegeraet_2_Abschaltstufe "Funktionseinschränkung aufgrund aktiver Abschaltstufe";
CM_ SG_ 2549088454 Ladegeraet_2_Transport_Mode "Funktionseinschränkung aufgrund aktivem Transport Mode und/oder Transport Schutz";
CM_ SG_ 2549088454 Ladegeraet_2_Nachlauftyp "Abgebildet wird die von der Hardware vorgegebene Möglichkeit, die Kommunikation nach Klemme 15 = AUS aufrecht zu erhalten. Es wird ein Init-Wert gesendet.
0 = Kommunikation nur bei KL15=EIN (kein Nachlauf, nicht weckfähig)
1 = Kommunikation nach KL15=AU";
CM_ SG_ 2549088454 Ladegeraet_2_SNI "Source Node-Identifier (SNI) identifiziert den Sender der NM-Botschaft (Knotenadresse) eindeutig im Fahrzeug";
CM_ SG_ 2549088454 KN_Ladegeraet_2_ECUKnockOutTimer "Ausgabe des ECUKnockOut-Timer in der Knotenbotschaft";
CM_ SG_ 2549088454 KN_Ladegeraet_2_BusKnockOut "Ausgabe des BusKnockout-Status in der Knotenbotschaft";
CM_ SG_ 2549088454 KN_Ladegeraet_2_BusKnockOutTimer "Ausgabe des BusKnockOut-Timer in der Knotenbotschaft";
CM_ SG_ 2549088454 NM_Ladegeraet_2_Wakeup "enthält die Weckursache; stehen mehrere Weckursachen parallel an, dann muss der kleinste Wert übertragen werden";
CM_ SG_ 2549088454 KN_Ladegeraet_2_ECUKnockOut "Ausgabe des ECUKnockout-Status in der Knotenbotschaft";
CM_ SG_ 2549088454 NM_Ladegeraet_2_Lokalaktiv "Zeigt an ob das SG nach Klemme15 AUS und nach entsprechender MAX Aktivzeit noch aktiv war.";
CM_ SG_ 2549088454 Ladegeraet2_KD_Fehler "Bei gesetztem Bit ist mindestens ein Kundendienstfehler eingetragen";
CM_ SG_ 2549088257 Sekundaer_01_KompSchutz "Funktionseinschränkung aufgrund Komponentenschutz aktiv";
CM_ SG_ 2549088257 Sekundaer_01_Abschaltstufe "Funktionseinschränkung aufgrund aktiver Abschaltstufe";
CM_ SG_ 2549088257 Sekundaer_01_Transport_Mode "Funktionseinschränkung aufgrund aktivem Transport Mode und/oder Transport Schutz";
CM_ SG_ 2549088257 Sekundaer_01_Nachlauftyp "Abgebildet wird die von der Hardware vorgegebene Möglichkeit, die Kommunikation nach Klemme 15 = AUS aufrecht zu erhalten. Es wird ein Init-Wert gesendet.
0 = Kommunikation nur bei KL15=EIN (kein Nachlauf, nicht weckfähig)
1 = Kommunikation nach KL15=AU";
CM_ SG_ 2549088257 Sekundaer_01_SNI "Das Signal beinhaltet den Source Node Identifier (Knotenadresse, die auch in der Abbildungsvorschrift zur CAN-ID für die NM-High Botschaft verwendet wird).";
CM_ SG_ 2549088257 KN_Sekundaer_01_ECUKnockOutTimer "Ausgabe des ECUKnockOut-Timer in der Knotenbotschaft";
CM_ SG_ 2549088257 KN_Sekundaer_01_BusKnockOut "Ausgabe des BusKnockout-Status in der Knotenbotschaft";
CM_ SG_ 2549088257 KN_Sekundaer_01_BusKnockOutTimer "Ausgabe des BusKnockOut-Timer in der Knotenbotschaft";
CM_ SG_ 2549088257 NM_Sekundaer_01_Wakeup "enthält die Weckursache; stehen mehrere Weckursachen parallel an, dann muss der kleinste Wert übertragen werden";
CM_ SG_ 2549088257 KN_Sekundaer_01_ECUKnockOut "Ausgabe des ECUKnockout-Status in der Knotenbotschaft";
CM_ SG_ 2549088257 NM_Sekundaer_01_Lokalaktiv "Zeigt an ob das SG nach Klemme15 AUS und nach entsprechender MAX Aktivzeit noch aktiv war";
CM_ SG_ 2549088257 Sekundaer_01_KD_Fehler "Status Kundendienst-Fehlerspeicher";
CM_ SG_ 2549088259 Sekundaer_03_KompSchutz "Funktionseinschränkung aufgrund Komponentenschutz aktiv";
CM_ SG_ 2549088259 Sekundaer_03_Abschaltstufe "Funktionseinschränkung aufgrund aktiver Abschaltstufe";
CM_ SG_ 2549088259 Sekundaer_03_Transport_Mode "Funktionseinschränkung aufgrund aktivem Transport Mode und/oder Transport Schutz";
CM_ SG_ 2549088259 Sekundaer_03_Nachlauftyp "Abgebildet wird die von der Hardware vorgegebene Möglichkeit, die Kommunikation nach Klemme 15 = AUS aufrecht zu erhalten. Es wird ein Init-Wert gesendet.
0 = Kommunikation nur bei KL15=EIN (kein Nachlauf, nicht weckfähig)
1 = Kommunikation nach KL15=AU";
CM_ SG_ 2549088259 Sekundaer_03_SNI "Das Signal beinhaltet den Source Node Identifier (Knotenadresse, die auch in der Abbildungsvorschrift zur CAN-ID für die NM-High Botschaft verwendet wird).";
CM_ SG_ 2549088259 KN_Sekundaer_03_ECUKnockOutTimer "Ausgabe des ECUKnockOut-Timer in der Knotenbotschaft";
CM_ SG_ 2549088259 KN_Sekundaer_03_ECUKnockOut "Ausgabe des ECUKnockout-Status in der Knotenbotschaft";
CM_ SG_ 2549088259 KN_Sekundaer_03_BusKnockOutTimer "Ausgabe des BusKnockOut-Timer in der Knotenbotschaft";
CM_ SG_ 2549088259 Sekundaer_03_LEH_Wakeup "enthält die Weckursache; stehen mehrere Weckursachen parallel an, dann muss der kleinste Wert übertragen werden";
CM_ SG_ 2549088259 KN_Sekundaer_03_BusKnockOut "Ausgabe des BusKnockout-Status in der Knotenbotschaft";
CM_ SG_ 2549088259 Sekundaer_03_Lokalaktiv "Zeigt an ob das SG nach Klemme15 AUS und nach entsprechender MAX Aktivzeit noch aktiv war";
CM_ SG_ 2549088259 Sekundaer_03_KD_Fehler "Status Kundendienst-Fehlerspeicher";
CM_ SG_ 2549088329 Sub_Gateway_KompSchutz "Funktionseinschraenkung aufgrund Komponentenschutz aktiv";
CM_ SG_ 2549088329 Sub_Gateway_Abschaltstufe "Funktionseinschraenkung aufgrund aktiver Abschaltstufe";
CM_ SG_ 2549088329 Sub_Gateway_Transport_Mode "Funktionseinschränkung aufgrund aktivem Transport Mode und/ oder Transport Schutz";
CM_ SG_ 2549088329 Sub_Gateway_Nachlauftyp "Abgebildet wird die von der Hardware vorgegebene Möglichkeit, die Kommunikation nach Klemme 15 = AUS aufrecht zu erhalten. Es wird ein Init-Wert gesendet.
0 = Kommunikation nur bei KL15=EIN (kein Nachlauf, nicht weckfähig)
1 = Kommunikation nach KL15=AU";
CM_ SG_ 2549088329 Sub_Gateway_SNI "Das Signal beinhaltet den Source Node Identifier (Knotenadresse, die auch in der Abbildungsvorschrift zur CAN-ID für die NM-High Botschaft verwendet wird).";
CM_ SG_ 2549088329 Sub_Gateway_BusKnockOutTimer "Ausgabe des BusKnockOut-Timer in der Knotenbotschaft
";
CM_ SG_ 2549088329 NM_Sub_Gateway_Wakeup "enthält die Weckursache; stehen mehrere Weckursachen parallel an, dann muss der kleinste Wert übertragen werden";
CM_ SG_ 2549088329 NM_Sub_Gateway_Lokalaktiv "Zeigt an ob das SG nach Klemme15 AUS und nach entsprechender MAX Aktivzeit noch aktiv war";
CM_ SG_ 2549088329 NM_Sub_Gateway_Subsystemaktiv "Zeigt an ob ein Subsystem des SGs nach Klemme15 AUS und nach entsprechender MAX Aktivzeit noch aktiv war";
CM_ SG_ 2549088329 Sub_Gateway_KD_Fehler "Bei gesetztem Bit ist mindestens ein Kundendienstfehler eingetragen";
CM_ SG_ 2549088322 TME_KompSchutz "Funktionseinschränkung aufgrund Komponentenschutz aktiv";
CM_ SG_ 2549088322 TME_Abschaltstufe "Funktionseinschränkung aufgrund aktiver Abschaltstufe";
CM_ SG_ 2549088322 TME_Transport_Mode "Funktionseinschränkung aufgrund aktivem Transport Mode und/oder Transport Schutz";
CM_ SG_ 2549088322 TME_Nachlauftyp "Abgebildet wird die von der Hardware vorgegebene Möglichkeit, die Kommunikation nach Klemme 15 = AUS aufrecht zu erhalten. Es wird ein Init-Wert gesendet.
0 = Kommunikation nur bei KL15=EIN (kein Nachlauf, nicht weckfähig)
1 = Kommunikation nach KL15=AU";
CM_ SG_ 2549088322 TME_SNI "Das Signal beinhaltet den Source Node Identifier (Knotenadresse, die auch in der Abbildungsvorschrift zur CAN-ID für die NM-High Botschaft verwendet wird).";
CM_ SG_ 2549088322 KN_TME_BusKnockOutTimer "Ausgabe des BusKnockOut-Timer in der Knotenbotschaft";
CM_ SG_ 2549088322 NM_TME_Wakeup "enthält die Weckursache; stehen mehrere Weckursachen parallel an, dann muss der kleinste Wert übertragen werden";
CM_ SG_ 2549088322 NMH_TME_Lokalaktiv "Zeigt an ob Steuergerät lokal aktiv war";
CM_ SG_ 2549088322 NMH_TME_Subsystemaktiv "Zeigt an ob ein Subsystem des SGs nach Klemme15 AUS und nach entsprechender MAX Aktivzeit noch aktiv war";
CM_ SG_ 2549088322 TME_KD_Fehler "Bei gesetztem Bit ist mindestens ein Kundendienstfehler eingetragen";
CM_ BO_ 779 "MQB";
CM_ SG_ 779 KBI_ABS_Lampe "ABS-Sicherheits-Lampe wurde eingeschaltet.";
CM_ SG_ 779 KBI_ESP_Lampe "ESP-Sicherheits-Lampe wurde eingeschaltet ";
CM_ SG_ 779 KBI_BKL_Lampe "Sicherheits-Lampe Bremskontrolle wurde eingeschaltet;
";
CM_ SG_ 779 KBI_Airbag_Lampe "Airbag Sicherheits-Lampe wurde eingeschaltet ";
CM_ SG_ 779 KBI_SILA_gueltig "Rückmeldeinformation (Bit 1-6) ist gültig";
CM_ SG_ 779 KBI_Lenkung_Lampe "Sicherheits-Lampe der Lenkung (Lenkhilfe EPS, Audi-Dynamic-Steering ...) wurde eingeschaltet.

0x0 = Lenkungs-Lampe aus
0x1 = Lenkungs-Lampe ein";
CM_ SG_ 779 KBI_Vorglueh_System_Lampe "Rückmeldung der Vorglühlampe bzw. Motor Systemlampe (MO_Systemlampe) an den Motor (bei Diesel und Otto!). Hardwaremässig gleiche LED im Kombi (EPC- oder Glühwendel), Unterscheidung nur über Ziffernblatt.";
CM_ SG_ 779 KBI_NV_in_Anzeige "Das Bit gibt dem NV die Information, ob NV-Bild im Kombi in der Anzeige ist. (Information ist notwendig um Kontrasverstellungen nur dann zuzulassen, wenn der Fahrer das Feedback über das  Kombidisplay bekommt.)";
CM_ SG_ 779 KBI_Anzeigestatus_ACC "Status der ACC-Anzeige im nicht permanenten Displaybereich";
CM_ SG_ 779 KBI_Anzeigestatus_GRA "Anzeigestatus der GRA High Wunschgeschwindigkeitsanzeige im Kombiinstrument.
Bei VW bedeutet 'nicht vorhanden' GRA-low fähig (LED immer verbaut).
0 = nicht vorhanden
1 = Wunschgeschwindigkeits-Anzeigemöglichkeit vorhanden
2 = reserviert
3 = Fehler (B";
CM_ SG_ 779 KBI_Tankwarnung "Fahrer wird gewarnt, dass er den Reservebereich erreicht hat. Fzg.spezifische Warnschwelle";
CM_ SG_ 779 KBI_MFA_v_Einheit_01 "Einheit der Geschwindigkeit, die vom Fahrer im Car-Menü gewählt wurde. Veränderliche Grösse, im Gegensatz zur Einheit des Tachokranzes.";
CM_ SG_ 779 KBI_im_Stellgliedtest "Kombi im Stellgliedtest, Signal muss eingelesen werden, um Fehlfunktion aufgrund der Bewegung der Stellglieder (Drehzahlmesser, Tacho) des Kombis zu verhindern";
CM_ SG_ 779 KBI_Tankwarnung_ungueltig "Validiert den Inhalt des Signales KBI_Tankwarnung";
CM_ SG_ 779 KBI_Handbremse "Handbremsen-Information vom Kombi.
Das Signal bezieht sich ausschließlich auf den Zustand der konventionellen Handbremse.";
CM_ SG_ 779 KBI_V_Digital "Ausgabe der im Kombi angezeigten digitalen Geschwindigkeit.

Einheit ist im KBI_MFA_v_Einheit_01 definiert";
CM_ SG_ 779 KBI_PLA_in_Anzeige "Das Signal wird als aktive Rückmeldung genutzt, ob die Info des PLA im Kombi angezeigt wird. Wenn nach Anforderung des Displays das Signal zweimal auf 0 ist, wird der Parkvorgang abgebrochen.
Ein Kombi, dass PLA Anzeige nicht unterstützt, schickt dauerha";
CM_ SG_ 779 KBI_Anzeigefehler_NV "Über dieses Signal teilt das Kombiinstrument dem Nightvision-Steuergerät mit, dass ein Fehler vom Kombiinstrument diagnostiziert wurde, der zur Abschaltung der Nightvision-Funktion führen muss.";
CM_ SG_ 779 KBI_Anzeigestatus_LIM "Anzeigestatus der Speedlimiter Wunschgeschwindigkeitsanzeige im Kombiinstrument (permanenter Anzeigebereich)
0 = nicht vorhanden
1 = Wunschgeschwindigkeits-Anzeigemöglichkeit vorhanden
2 = reserviert
3 = Fehler (Botschaftsüberwachung, Timeout, Akustik";
CM_ SG_ 779 KBI_ARA_in_Anzeige "Anzeige von ARA im Kombi aktiv";
CM_ SG_ 779 KBI_Taster_Lift "Betätigung Taster 'Lift' im Kombi J1 zur Verarbeitung im Porsche EFP Steuergerät";
CM_ SG_ 779 KBI_Taster_Fahrwerk "Betätigung Taster 'Fahrwerk' im Kombi";
CM_ SG_ 779 KBI_angez_Geschw "Im Tacho angezeigte Geschwindigkeit inklusive der Voreilung

";
CM_ SG_ 779 KBI_Einheit_Tacho "Information, ob es sich um Meilen- oder Kmh-Kombi handelt, Einheit des Tachos entspricht dem Zifferblatt, Grösse ist nicht veränderlich";
CM_ SG_ 779 KBI_Konsistenz_ACC "Rückmeldung an ACC, dass die Botschaften zur Ansteuerung von Anzeigen nicht bzw. nicht konsistent empfangen wurden (Timeout-, BZ-, CHK- und DLC-Fehler)                                                                                                        ";
CM_ SG_ 779 KBI_Fehler_Anzeige_ACC "Rückmeldung an ACC, dass mindestens eine der ACC-relevanten Anzeigen -rote Fahrerübernahme, Mitteldisplay, Gong - fehlerhaft sind.";
CM_ SG_ 779 KBI_Anzeigefehler_SWA "Signal bezieht sich nur auf die SWA-Lampe, Vorhalt für Kombis mit SWA-Lampe. ";
CM_ SG_ 779 KBI_Systemstatus "Signalisiert erkannte FuSi-relevante Fehler im Kombi
(keinen Ausfall der Akustik oder des Displays)";
CM_ SG_ 1719 KBI_Kilometerstand "Fehler wird ausgegeben, falls Kilometerstand nicht restaurierbar
";
CM_ SG_ 1719 KBI_Standzeit_02 "Zähler welcher die Standzeit des Motors wiedergibt.
Das Signal beschreibt den Anteil der Motor-Standzeit zwischen Zündung aus und nächstem Motorstart.";
CM_ SG_ 1719 KBI_LVDS_Lock "Dient zur Synchronisation der Anzeige zwischen Kombi und ZR";
CM_ SG_ 1719 KBI_Reserve_Warnung_Sek "Signalisiert die Reservewarnung für die Energiespeicher CNG, LPG, HV-Batterie.
Fahrer wird gewarnt, dass er den Reservebereich erreicht hat. Fzg.spezifische Warnschwelle.";
CM_ SG_ 1719 KBI_RDK_Kalibrier_Anf "Bei gesetztem Bit soll die RDK die aktuellen Istdrücke zu Solldrücken übernehmen (nur bei Nichtverbau einer Headunit erforderlich).";
CM_ SG_ 1719 KBI_Inhalt_Tank "Restmenge 2 bzw. 2,5l nicht auflösbar

";
CM_ SG_ 1719 KBI_FStatus_Tank "Signal wird gesetzt:

a) Während der Fehlerentprellzeit (20 s Entprellung)

b) Bei erkanntem Fehler wird der Tankinhalt während der laufenden KL15-Phase über den 
    Verbrauch zurückgerechnet. In dieser Zeit ist das Bit ebenfalls gesetzt. Nach einem";
CM_ SG_ 1719 KBI_aktive_Laengsfunktion "Auswahl, der vom Fahrer gewünschten Laengsregelfunktion";
CM_ SG_ 1719 KBI_FoD_PopUP_Quittiert "Angezeigte FoD-Warnung im Kombi wurde vom Fahrer quittiert; 
Signal wird für die Dauer von 2 Sekunden gesendet";
CM_ SG_ 1719 KBI_GRA_im_ACC "Gibt den vom Fahrer ausgewählten Modus (ACC oder GRA_im_ACC) an.";
CM_ SG_ 1719 KBI_Oelwechsel_durchgefuehrt "Nach einen Ölwechsel (Service) ist die Ethanol Warmfahrwarnung zu unterdrücken.";
CM_ SG_ 1719 KBI_QBit_Aussen_Temp_gef "0x0 = gültiger Wert
0x1 = Ersatz-, Init- oder Fehlerwert";
CM_ SG_ 2549875067 KS_Hybrid_01_Req_Data "ISO-TP Datenkanal - FID2NA
Request Funktion 0x01 Komponentenschutz an Knoten 0x7B";
CM_ SG_ 2550006139 KS_Hybrid_01_Resp_Data "ISO-TP Datenkanal - FID2NA
Response Knoten 0x7B an Funktion 0x01 Komponentenschutz";
CM_ SG_ 2549875142 KS_Ladegeraet_2_Req_Data "ISO-TP Datenkanal - FID2NA
Request Funktion 0x01 Komponentenschutz an Knoten 0xC6";
CM_ SG_ 2550006214 KS_Ladegeraet_2_Resp_Data "ISO-TP Datenkanal - FID2NA
Response Knoten 0xC6 an Funktion 0x01 Komponentenschutz";
CM_ SG_ 2549875012 KS_Ladegeraet_Req_Data "Komponentenschutz (Funktion 01h). Request mit NA des Slaves.";
CM_ SG_ 2550006084 KS_Ladegeraet_Resp_Data "Komponentenschutz (Funktion 01h). Response mit eigener NA.";
CM_ SG_ 2549899473 KS_SSN_CMC_01_Req_Data "Komponentenschutz (Funktion 01h). Request mit NA des Slaves.";
CM_ SG_ 2550030545 KS_SSN_CMC_01_Resp_Data "Komponentenschutz (Funktion 01h). Request mit NA des Slaves.";
CM_ SG_ 2549899474 KS_SSN_CMC_02_Req_Data "Komponentenschutz (Funktion 01h). Request mit NA des Slaves.";
CM_ SG_ 2550030546 KS_SSN_CMC_02_Resp_Data "Komponentenschutz (Funktion 01h). Request mit NA des Slaves.";
CM_ SG_ 2549899475 KS_SSN_CMC_03_Req_Data "Komponentenschutz (Funktion 01h). Request mit NA des Slaves.";
CM_ SG_ 2550030547 KS_SSN_CMC_03_Resp_Data "Komponentenschutz (Funktion 01h). Request mit NA des Slaves.";
CM_ SG_ 2549899476 KS_SSN_CMC_04_Req_Data "Komponentenschutz (Funktion 01h). Request mit NA des Slaves.";
CM_ SG_ 2550030548 KS_SSN_CMC_04_Resp_Data "Komponentenschutz (Funktion 01h). Request mit NA des Slaves.";
CM_ SG_ 2549899477 KS_SSN_CMC_05_Req_Data "Komponentenschutz (Funktion 01h). Request mit NA des Slaves.";
CM_ SG_ 2550030549 KS_SSN_CMC_05_Resp_Data "Komponentenschutz (Funktion 01h). Request mit NA des Slaves.";
CM_ SG_ 2549899478 KS_SSN_CMC_06_Req_Data "Komponentenschutz (Funktion 01h). Request mit NA des Slaves.";
CM_ SG_ 2550030550 KS_SSN_CMC_06_Resp_Data "Komponentenschutz (Funktion 01h). Request mit NA des Slaves.";
CM_ SG_ 2549899479 KS_SSN_CMC_07_Req_Data "Komponentenschutz (Funktion 01h). Request mit NA des Slaves.";
CM_ SG_ 2550030551 KS_SSN_CMC_07_Resp_Data "Komponentenschutz (Funktion 01h). Request mit NA des Slaves.";
CM_ SG_ 2549899480 KS_SSN_CMC_08_Req_Data "Komponentenschutz (Funktion 01h). Request mit NA des Slaves.";
CM_ SG_ 2550030552 KS_SSN_CMC_08_Resp_Data "Komponentenschutz (Funktion 01h). Request mit NA des Slaves.";
CM_ SG_ 2549899481 KS_SSN_CMC_09_Req_Data "Komponentenschutz (Funktion 01h). Request mit NA des Slaves.";
CM_ SG_ 2550030553 KS_SSN_CMC_09_Resp_Data "Komponentenschutz (Funktion 01h). Request mit NA des Slaves.";
CM_ SG_ 2549899482 KS_SSN_CMC_10_Req_Data "Komponentenschutz (Funktion 01h). Request mit NA des Slaves.";
CM_ SG_ 2550030554 KS_SSN_CMC_10_Resp_Data "Komponentenschutz (Funktion 01h). Request mit NA des Slaves.";
CM_ SG_ 2549899483 KS_SSN_CMC_11_Req_Data "Komponentenschutz (Funktion 01h). Request mit NA des Slaves.";
CM_ SG_ 2550030555 KS_SSN_CMC_11_Resp_Data "Komponentenschutz (Funktion 01h). Request mit NA des Slaves.";
CM_ SG_ 2549899484 KS_SSN_CMC_12_Req_Data "Komponentenschutz (Funktion 01h). Request mit NA des Slaves.";
CM_ SG_ 2550030556 KS_SSN_CMC_12_Resp_Data "Komponentenschutz (Funktion 01h). Request mit NA des Slaves.";
CM_ SG_ 2549899505 KS_SSN_CMC_13_Req_Data "Komponentenschutz (Funktion 01h). Request mit NA des Slaves.";
CM_ SG_ 2550030577 KS_SSN_CMC_13_Resp_Data "Komponentenschutz (Funktion 01h). Request mit NA des Slaves.";
CM_ SG_ 2549899506 KS_SSN_CMC_14_Req_Data "Komponentenschutz (Funktion 01h). Request mit NA des Slaves.";
CM_ SG_ 2550030578 KS_SSN_CMC_14_Resp_Data "Komponentenschutz (Funktion 01h). Request mit NA des Slaves.";
CM_ SG_ 2549899507 KS_SSN_CMC_15_Req_Data "Komponentenschutz (Funktion 01h). Request mit NA des Slaves.";
CM_ SG_ 2550030579 KS_SSN_CMC_15_Resp_Data "Komponentenschutz (Funktion 01h). Request mit NA des Slaves.";
CM_ SG_ 2463978640 LAD2_01_CRC "Für MLB:
Berechnung siehe Lastenheft 'Kommunikationsabsicherung für FlexRay und CAN'
Ab MQB und MLBevo:
Berechnung siehe Lastenheft 'End-to-End Kommunikationsabsicherung'

Endwerte siehe Begleitdokument 'S-PDU Kennungsfolgen'";
CM_ SG_ 2463978640 LAD2_01_BZ "4bit Botschaftszähler, wird mit jeder Sendebotschaft inkrementiert";
CM_ SG_ 2463978640 LAD2_IstModus "Uebergabe aktueller interner Status von OBC2 an OBC1";
CM_ SG_ 2463978640 LAD2_Abregelung_Temperatur "Abregelung auf Grund interner Übertemperatur im OBC2";
CM_ SG_ 2463978640 LAD2_Temperatur "Momentanwert Temperatur OBC2";
CM_ SG_ 2463978640 LAD2_IstSpannung_HV "HV-Ausgangsspannung OBC2";
CM_ SG_ 2463978640 LAD2_Fehlerstatus "Aktueller Fehlerstatus von OBC2";
CM_ SG_ 2463978640 LAD2_Status_Spgfreiheit "Status Spannungsfreiheit OBC2";
CM_ SG_ 2463978640 LAD2_Status_Phasenumschaltung1 "Phasenumschaltung1 von OBC2 im Fehler. Loadbalancing wird durch OBC1 durchgeführt.";
CM_ SG_ 2463978640 LAD2_Status_Phasenumschaltung2 "Phasenumschaltung2 von OBC2 im Fehler. Loadbalancing wird durch OBC1 durchgeführt.";
CM_ SG_ 2463978640 LAD2_Status_Pfad1 "Rail1 von OBC2 im Fehler und nicht nutzbar für Ladevorgang. Loadbalancing wird durch OBC1 durchgeführt.";
CM_ SG_ 2463978640 LAD2_Status_Pfad2 "Rail2 von OBC2 im Fehler und nicht nutzbar für Ladevorgang. Loadbalancing wird durch OBC1 durchgeführt.";
CM_ SG_ 2463978640 LAD2_Status_Pfad3 "Rail3 von OBC2 im Fehler und nicht nutzbar für Ladevorgang. Loadbalancing wird durch OBC1 durchgeführt.";
CM_ SG_ 2463978644 LAD2_AC_Istspannung_L1 "AC-IstSpannung Rail1 von OBC2";
CM_ SG_ 2463978644 LAD2_AC_Istspannung_L2 "AC-IstSpannung Rail2 von OBC2";
CM_ SG_ 2463978644 LAD2_AC_Istspannung_L3 "AC-IstSpannung Rail3 von OBC2";
CM_ SG_ 2463978644 LAD2_IstStrom_HV_Pfad1 "HV-IstStrom Rail1 von OBC2";
CM_ SG_ 2463978644 LAD2_IstStrom_HV_Pfad2 "HV-IstStrom Rail2 von OBC2";
CM_ SG_ 2463978644 LAD2_IstStrom_HV_Pfad3 "HV-IstStrom Rail3 von OBC2";
CM_ SG_ 2463978645 LAD2_AC_IstStrom_L1 "AC-IstStrom Rail1 von OBC2";
CM_ SG_ 2463978645 LAD2_AC_IstStrom_L2 "AC-IstStrom Rail2 von OBC2";
CM_ SG_ 2463978645 LAD2_AC_IstStrom_L3 "AC-IstStrom Rail3 von OBC2";
CM_ SG_ 2589283493 LAD2_CALID_CVN_MUX "Alle CALID-Indizes bilden zusammen die CALID (OBC2)";
CM_ SG_ 2589283493 LAD2_CVN_VLD "Valid-Bit der Calibration-Verification-Number (CVN bzw. Checksumme) für OBC2";
CM_ SG_ 2589283493 LAD2_CALID_Index_01 "Software-Calibration-Identification (CALID) im ASCII-Zeichenformat; 
für Ausgabe an das Generic Scan-Tool für OBD in NAR

0x30 entspricht ASCII '0'";
CM_ SG_ 2589283493 LAD2_CALID_Index_05 "Software-Calibration-Identification (CALID) im ASCII-Zeichenformat; 
für Ausgabe an das Generic Scan-Tool für OBD in NAR

0x30 entspricht ASCII '0'";
CM_ SG_ 2589283493 LAD2_CALID_Index_09 "Software-Calibration-Identification (CALID) im ASCII-Zeichenformat; 
für Ausgabe an das Generic Scan-Tool für OBD in NAR

0x30 entspricht ASCII '0'";
CM_ SG_ 2589283493 LAD2_CALID_Index_13 "Software-Calibration-Identification (CALID) im ASCII-Zeichenformat; 
für Ausgabe an das Generic Scan-Tool für OBD in NAR

0x30 entspricht ASCII '0'";
CM_ SG_ 2589283493 LAD2_CALID_Index_02 "Software-Calibration-Identification (CALID) im ASCII-Zeichenformat; 
für Ausgabe an das Generic Scan-Tool für OBD in NAR

0x30 entspricht ASCII '0'";
CM_ SG_ 2589283493 LAD2_CALID_Index_06 "Software-Calibration-Identification (CALID) im ASCII-Zeichenformat; 
für Ausgabe an das Generic Scan-Tool für OBD in NAR

0x30 entspricht ASCII '0'";
CM_ SG_ 2589283493 LAD2_CALID_Index_10 "Software-Calibration-Identification (CALID) im ASCII-Zeichenformat; 
für Ausgabe an das Generic Scan-Tool für OBD in NAR

0x30 entspricht ASCII '0'";
CM_ SG_ 2589283493 LAD2_CALID_Index_14 "Software-Calibration-Identification (CALID) im ASCII-Zeichenformat; 
für Ausgabe an das Generic Scan-Tool für OBD in NAR

0x30 entspricht ASCII '0'";
CM_ SG_ 2589283493 LAD2_CALID_Index_03 "Software-Calibration-Identification (CALID) im ASCII-Zeichenformat; 
für Ausgabe an das Generic Scan-Tool für OBD in NAR

0x30 entspricht ASCII '0'";
CM_ SG_ 2589283493 LAD2_CALID_Index_07 "Software-Calibration-Identification (CALID) im ASCII-Zeichenformat; 
für Ausgabe an das Generic Scan-Tool für OBD in NAR

0x30 entspricht ASCII '0'";
CM_ SG_ 2589283493 LAD2_CALID_Index_11 "Software-Calibration-Identification (CALID) im ASCII-Zeichenformat; 
für Ausgabe an das Generic Scan-Tool für OBD in NAR

0x30 entspricht ASCII '0'";
CM_ SG_ 2589283493 LAD2_CALID_Index_15 "Software-Calibration-Identification (CALID) im ASCII-Zeichenformat; 
für Ausgabe an das Generic Scan-Tool für OBD in NAR

0x30 entspricht ASCII '0'";
CM_ SG_ 2589283493 LAD2_CALID_Index_04 "Software-Calibration-Identification (CALID) im ASCII-Zeichenformat; 
für Ausgabe an das Generic Scan-Tool für OBD in NAR

0x30 entspricht ASCII '0'";
CM_ SG_ 2589283493 LAD2_CALID_Index_08 "Software-Calibration-Identification (CALID) im ASCII-Zeichenformat; 
für Ausgabe an das Generic Scan-Tool für OBD in NAR

0x30 entspricht ASCII '0'";
CM_ SG_ 2589283493 LAD2_CALID_Index_12 "Software-Calibration-Identification (CALID) im ASCII-Zeichenformat; 
für Ausgabe an das Generic Scan-Tool für OBD in NAR

0x30 entspricht ASCII '0'";
CM_ SG_ 2589283493 LAD2_CALID_Index_16 "Software-Calibration-Identification (CALID) im ASCII-Zeichenformat; 
für Ausgabe an das Generic Scan-Tool für OBD in NAR

0x30 entspricht ASCII '0'";
CM_ SG_ 2589283493 LAD2_CVN_Byte_1 "Calibration Verification Number (CVN bzw. Checksumme) des SW- und Datenstandes; 
für Ausgabe an das Generic Scan-Tool für OBD in NAR";
CM_ SG_ 2589283493 LAD2_CVN_Byte_2 "Calibration Verification Number (CVN bzw. Checksumme) des SW- und Datenstandes; 
für Ausgabe an das Generic Scan-Tool für OBD in NAR";
CM_ SG_ 2589283493 LAD2_CVN_Byte_3 "Calibration Verification Number (CVN bzw. Checksumme) des SW- und Datenstandes; 
für Ausgabe an das Generic Scan-Tool für OBD in NAR";
CM_ SG_ 2589283493 LAD2_CVN_Byte_4 "Calibration Verification Number (CVN bzw. Checksumme) des SW- und Datenstandes; 
für Ausgabe an das Generic Scan-Tool für OBD in NAR";
CM_ SG_ 2589283392 LAD2_KomponentenFehler_01 "Übertragung OBD relevanter Fehlerpfade vom Secondary zum Primary Steuergerät. 
Zuordnung der generischen Komponentenfehler muss zwischen Sender und Empfänger abgestimmt werden.";
CM_ SG_ 2589283392 LAD2_KomponentenFehler_02 "Übertragung OBD relevanter Fehlerpfade vom Secondary zum Primary Steuergerät. 
Zuordnung der generischen Komponentenfehler muss zwischen Sender und Empfänger abgestimmt werden.";
CM_ SG_ 2589283392 LAD2_KomponentenFehler_03 "Übertragung OBD relevanter Fehlerpfade vom Secondary zum Primary Steuergerät. 
Zuordnung der generischen Komponentenfehler muss zwischen Sender und Empfänger abgestimmt werden.";
CM_ SG_ 2589283392 LAD2_KomponentenFehler_04 "Übertragung OBD relevanter Fehlerpfade vom Secondary zum Primary Steuergerät. 
Zuordnung der generischen Komponentenfehler muss zwischen Sender und Empfänger abgestimmt werden.";
CM_ SG_ 2589283392 LAD2_KomponentenFehler_05 "Übertragung OBD relevanter Fehlerpfade vom Secondary zum Primary Steuergerät. 
Zuordnung der generischen Komponentenfehler muss zwischen Sender und Empfänger abgestimmt werden.";
CM_ SG_ 2589283392 LAD2_KomponentenFehler_06 "Übertragung OBD relevanter Fehlerpfade vom Secondary zum Primary Steuergerät. 
Zuordnung der generischen Komponentenfehler muss zwischen Sender und Empfänger abgestimmt werden.";
CM_ SG_ 2589283392 LAD2_KomponentenFehler_07 "Übertragung OBD relevanter Fehlerpfade vom Secondary zum Primary Steuergerät. 
Zuordnung der generischen Komponentenfehler muss zwischen Sender und Empfänger abgestimmt werden.";
CM_ SG_ 2589283392 LAD2_KomponentenFehler_08 "Übertragung OBD relevanter Fehlerpfade vom Secondary zum Primary Steuergerät. 
Zuordnung der generischen Komponentenfehler muss zwischen Sender und Empfänger abgestimmt werden.";
CM_ SG_ 2589283392 LAD2_KomponentenFehler_09 "Übertragung OBD relevanter Fehlerpfade vom Secondary zum Primary Steuergerät. 
Zuordnung der generischen Komponentenfehler muss zwischen Sender und Empfänger abgestimmt werden.";
CM_ SG_ 2589283392 LAD2_KomponentenFehler_10 "Übertragung OBD relevanter Fehlerpfade vom Secondary zum Primary Steuergerät. 
Zuordnung der generischen Komponentenfehler muss zwischen Sender und Empfänger abgestimmt werden.";
CM_ SG_ 2589283392 LAD2_KomponentenFehler_11 "Übertragung OBD relevanter Fehlerpfade vom Secondary zum Primary Steuergerät. 
Zuordnung der generischen Komponentenfehler muss zwischen Sender und Empfänger abgestimmt werden.";
CM_ SG_ 2589283392 LAD2_KomponentenFehler_12 "Übertragung OBD relevanter Fehlerpfade vom Secondary zum Primary Steuergerät. 
Zuordnung der generischen Komponentenfehler muss zwischen Sender und Empfänger abgestimmt werden.";
CM_ SG_ 2589283392 LAD2_KomponentenFehler_13 "Übertragung OBD relevanter Fehlerpfade vom Secondary zum Primary Steuergerät. 
Zuordnung der generischen Komponentenfehler muss zwischen Sender und Empfänger abgestimmt werden.";
CM_ SG_ 2589283392 LAD2_KomponentenFehler_14 "Übertragung OBD relevanter Fehlerpfade vom Secondary zum Primary Steuergerät. 
Zuordnung der generischen Komponentenfehler muss zwischen Sender und Empfänger abgestimmt werden.";
CM_ SG_ 2589283392 LAD2_KomponentenFehler_15 "Übertragung OBD relevanter Fehlerpfade vom Secondary zum Primary Steuergerät. 
Zuordnung der generischen Komponentenfehler muss zwischen Sender und Empfänger abgestimmt werden.";
CM_ SG_ 2589283392 LAD2_KomponentenFehler_16 "Übertragung OBD relevanter Fehlerpfade vom Secondary zum Primary Steuergerät. 
Zuordnung der generischen Komponentenfehler muss zwischen Sender und Empfänger abgestimmt werden.";
CM_ SG_ 2589283392 LAD2_KomponentenFehler_17 "Übertragung OBD relevanter Fehlerpfade vom Secondary zum Primary Steuergerät. 
Zuordnung der generischen Komponentenfehler muss zwischen Sender und Empfänger abgestimmt werden.";
CM_ SG_ 2589283392 LAD2_KomponentenFehler_18 "Übertragung OBD relevanter Fehlerpfade vom Secondary zum Primary Steuergerät. 
Zuordnung der generischen Komponentenfehler muss zwischen Sender und Empfänger abgestimmt werden.";
CM_ SG_ 2589283392 LAD2_KomponentenFehler_19 "Übertragung OBD relevanter Fehlerpfade vom Secondary zum Primary Steuergerät. 
Zuordnung der generischen Komponentenfehler muss zwischen Sender und Empfänger abgestimmt werden.";
CM_ SG_ 2589283392 LAD2_KomponentenFehler_20 "Übertragung OBD relevanter Fehlerpfade vom Secondary zum Primary Steuergerät. 
Zuordnung der generischen Komponentenfehler muss zwischen Sender und Empfänger abgestimmt werden.";
CM_ SG_ 2589283688 LAD2_Version "Abgleich der SW-Version zwischen OBC1 und  OBC2 zur Plausibilisierung in der 2x11 kW Topologie";
CM_ SG_ 2589283688 LAD2_Version_MUX "Alle Indizes ergeben die SW-Version";
CM_ SG_ 2589283688 LAD2_Version_Index_01 "Marke Architektur";
CM_ SG_ 2589283688 LAD2_Version_Index_02 "Leistungsklasse";
CM_ SG_ 2589283688 LAD2_Version_Index_03 "Versionszähler Zehner";
CM_ SG_ 2589283688 LAD2_Version_Index_04 "Versionszähler Einer";
CM_ BO_ 1380 "MLB, MXB, MLBevo";
CM_ SG_ 1380 LAD_01_CRC "Ab MQB und MLBevo:
'Berechnung siehe Lastenheft 'End-to-End Kommunikationsabsicherung''

Endwerte siehe Begleitdokument 'S-PDU Kennungsfolgen'";
CM_ SG_ 1380 LAD_01_BZ "freilaufender Botschaftszähler";
CM_ SG_ 1380 LAD_IstModus "Betriebsmodus des Ladegerätes";
CM_ SG_ 1380 LAD_AC_Istspannung "Istwert AC-Netzspannung (RMS) ";
CM_ SG_ 1380 LAD_IstSpannung_HV "Ausgangsspannung Lader";
CM_ SG_ 1380 LAD_IstStrom_HV "Ausgangsstrom Lader";
CM_ SG_ 1380 LAD_Status_Spgfreiheit "0 = Init (ohne Funktion)
1 = Ladegerät HV-Komponenten spannungsfrei (U_Zwkr < 20V)
2 = Ladegerät HV_Komponenten nicht spannungsfrei (U_Zwkr >= 20V)
3 = Fehler (z. B. Fehler in der Sensorik)";
CM_ SG_ 1380 LAD_Temperatur "Momentanwert: Temperatur Ladegerät";
CM_ SG_ 1380 LAD_Verlustleistung "Momentanwert: Verlustleistung Ladegerät";
CM_ BO_ 1662 "MLB, MXB, MLBevo";
CM_ SG_ 1662 LAD_02_CRC "Ab MQB und MLBevo:
'Berechnung siehe Lastenheft 'End-to-End Kommunikationsabsicherung''

Endwerte siehe Begleitdokument 'S-PDU Kennungsfolgen'";
CM_ SG_ 1662 LAD_02_BZ "freilaufender Botschaftszähler";
CM_ SG_ 1662 LAD_Abregelung_Temperatur "Abregelung aufgrund interner Übertemperatur im Ladegerät";
CM_ SG_ 1662 LAD_Abregelung_IU_Ein_Aus "Abregelung aufgrund Strom oder Spannung am Eingang oder Ausgang";
CM_ SG_ 1662 LAD_Abregelung_BuchseTemp "Reduzierung aufgrund zu hoher Temperatur der Ladebuchse";
CM_ SG_ 1662 LAD_MaxLadLeistung_HV "Maximale Leistung Ladegerät bezogen auf die maximale Leistung Infrastruktur (Kabel, Ladestation) und Berücksichtigung des Ladegerät-Wirkungsgrades";
CM_ SG_ 1662 LAD_PRX_Stromlimit "AC-Stromlimit aufgrund der PRX Kabelkodierung";
CM_ SG_ 1662 LAD_CP_Erkennung "Status Control Pilot Überwachung (Erkennung des Control Pilot Duty-Cycles)";
CM_ SG_ 1662 LAD_Stecker_Verriegelt "Status Steckerverriegelung (Rücklesekontakt des Verrieglungsaktors)";
CM_ SG_ 1662 LAD_Kuehlbedarf "Kühlbedarf des Ladegerätes";
CM_ SG_ 1662 LAD_MaxLadLeistung_HV_Offset "Signal kann in Ergänzung zu LAD_MaxLadLeistung_HV (100W Skalierung) genutzt werden, um die Auflösegenauigkeit auf 25W zu erweitern.";
CM_ SG_ 1662 LAD_Warnzustand "Sammelwarnung Ladegerät
0 keine Warnbedingung aktiv
1 Warnbedingung aktiv, evtl. eingeschränkte Leistungsfähigkeit";
CM_ SG_ 1662 LAD_Fehlerzustand "Sammelfehler Ladegerät - kein Laden möglich";
CM_ SG_ 2463978642 LAD_SollStrom_HV_Pfad1 "HV-SollStrom für Rail1 von OBC2";
CM_ SG_ 2463978642 LAD_SollStrom_HV_Pfad2 "HV-Sollstrom für Rail2 von OBC2";
CM_ SG_ 2463978642 LAD_SollStrom_HV_Pfad3 "HV-Sollstrom für Rail3 von OBC2";
CM_ SG_ 2463978643 LAD_05_CRC "Für MLB:
Berechnung siehe Lastenheft 'Kommunikationsabsicherung für FlexRay und CAN'
Ab MQB und MLBevo:
Berechnung siehe Lastenheft 'End-to-End Kommunikationsabsicherung'

Endwerte siehe Begleitdokument 'S-PDU Kennungsfolgen'";
CM_ SG_ 2463978643 LAD_05_BZ "4bit Botschaftszähler, wird mit jeder Sendebotschaft inkrementiert";
CM_ SG_ 2463978643 LAD_AC_MaxStrom_L1 "Maximaler AC-Eingangsstrom auf Rail 1 für OBC2";
CM_ SG_ 2463978643 LAD_AC_MaxStrom_L2 "Maximaler AC-Eingangsstrom auf Rail 2 für OBC2";
CM_ SG_ 2463978643 LAD_AC_MaxStrom_L3 "Maximaler AC-Eingangsstrom auf Rail 3 für OBC2";
CM_ SG_ 2463978643 LAD_Freigabe_LAD2 "Ladefreigabe für zweiten OBC bei Verbau von 2x11 kW OBC";
CM_ SG_ 2463978643 LAD_Max_LadeSpannung_LAD2 "max. voltage / maximal erlaubte Ladespannung";
CM_ SG_ 2589283663 LAD_PlanAntw_Verlustleistung "Antwort auf die Ladeplan-Anfrage für die Ladeplanung: Verlustleistung";
CM_ SG_ 2589283663 LAD_PlanAntw_Zaehler "Antwort auf die Ladeplan-Anfrage für die Ladeplanung: Zähler";
CM_ SG_ 2589283415 LAD_CALID_CVN_MUX "Alle CALID-Indizes bilden zusammen die CALID";
CM_ SG_ 2589283415 LAD_CVN_VLD "Valid-Bit der Calibration-Verification-Number (CVN bzw. Checksumme)";
CM_ SG_ 2589283415 LAD_CALID_Index_01 "Software-Calibration-Identification (CALID) im ASCII-Zeichenformat; 
für Ausgabe an das Generic Scan-Tool für OBD in NAR

0x30 entspricht ASCII '0'";
CM_ SG_ 2589283415 LAD_CALID_Index_05 "Software-Calibration-Identification (CALID) im ASCII-Zeichenformat; 
für Ausgabe an das Generic Scan-Tool für OBD in NAR

0x30 entspricht ASCII '0'";
CM_ SG_ 2589283415 LAD_CALID_Index_09 "Software-Calibration-Identification (CALID) im ASCII-Zeichenformat; 
für Ausgabe an das Generic Scan-Tool für OBD in NAR

0x30 entspricht ASCII '0'";
CM_ SG_ 2589283415 LAD_CALID_Index_13 "Software-Calibration-Identification (CALID) im ASCII-Zeichenformat; 
für Ausgabe an das Generic Scan-Tool für OBD in NAR

0x30 entspricht ASCII '0'";
CM_ SG_ 2589283415 LAD_CALID_Index_02 "Software-Calibration-Identification (CALID) im ASCII-Zeichenformat; 
für Ausgabe an das Generic Scan-Tool für OBD in NAR

0x30 entspricht ASCII '0'";
CM_ SG_ 2589283415 LAD_CALID_Index_06 "Software-Calibration-Identification (CALID) im ASCII-Zeichenformat; 
für Ausgabe an das Generic Scan-Tool für OBD in NAR

0x30 entspricht ASCII '0'";
CM_ SG_ 2589283415 LAD_CALID_Index_10 "Software-Calibration-Identification (CALID) im ASCII-Zeichenformat; 
für Ausgabe an das Generic Scan-Tool für OBD in NAR

0x30 entspricht ASCII '0'";
CM_ SG_ 2589283415 LAD_CALID_Index_14 "Software-Calibration-Identification (CALID) im ASCII-Zeichenformat; 
für Ausgabe an das Generic Scan-Tool für OBD in NAR

0x30 entspricht ASCII '0'";
CM_ SG_ 2589283415 LAD_CALID_Index_03 "Software-Calibration-Identification (CALID) im ASCII-Zeichenformat; 
für Ausgabe an das Generic Scan-Tool für OBD in NAR

0x30 entspricht ASCII '0'";
CM_ SG_ 2589283415 LAD_CALID_Index_07 "Software-Calibration-Identification (CALID) im ASCII-Zeichenformat; 
für Ausgabe an das Generic Scan-Tool für OBD in NAR

0x30 entspricht ASCII '0'";
CM_ SG_ 2589283415 LAD_CALID_Index_11 "Software-Calibration-Identification (CALID) im ASCII-Zeichenformat; 
für Ausgabe an das Generic Scan-Tool für OBD in NAR

0x30 entspricht ASCII '0'";
CM_ SG_ 2589283415 LAD_CALID_Index_15 "Software-Calibration-Identification (CALID) im ASCII-Zeichenformat; 
für Ausgabe an das Generic Scan-Tool für OBD in NAR

0x30 entspricht ASCII '0'";
CM_ SG_ 2589283415 LAD_CALID_Index_04 "Software-Calibration-Identification (CALID) im ASCII-Zeichenformat; 
für Ausgabe an das Generic Scan-Tool für OBD in NAR

0x30 entspricht ASCII '0'";
CM_ SG_ 2589283415 LAD_CALID_Index_08 "Software-Calibration-Identification (CALID) im ASCII-Zeichenformat; 
für Ausgabe an das Generic Scan-Tool für OBD in NAR

0x30 entspricht ASCII '0'";
CM_ SG_ 2589283415 LAD_CALID_Index_12 "Software-Calibration-Identification (CALID) im ASCII-Zeichenformat; 
für Ausgabe an das Generic Scan-Tool für OBD in NAR

0x30 entspricht ASCII '0'";
CM_ SG_ 2589283415 LAD_CALID_Index_16 "Software-Calibration-Identification (CALID) im ASCII-Zeichenformat; 
für Ausgabe an das Generic Scan-Tool für OBD in NAR

0x30 entspricht ASCII '0'";
CM_ SG_ 2589283415 LAD_CVN_Byte_1 "Calibration Verification Number (CVN bzw. Checksumme) des SW- und Datenstandes; 
für Ausgabe an das Generic Scan-Tool für OBD in NAR";
CM_ SG_ 2589283415 LAD_CVN_Byte_2 "Calibration Verification Number (CVN bzw. Checksumme) des SW- und Datenstandes; 
für Ausgabe an das Generic Scan-Tool für OBD in NAR";
CM_ SG_ 2589283415 LAD_CVN_Byte_3 "Calibration Verification Number (CVN bzw. Checksumme) des SW- und Datenstandes; 
für Ausgabe an das Generic Scan-Tool für OBD in NAR";
CM_ SG_ 2589283415 LAD_CVN_Byte_4 "Calibration Verification Number (CVN bzw. Checksumme) des SW- und Datenstandes; 
für Ausgabe an das Generic Scan-Tool für OBD in NAR";
CM_ SG_ 2589283472 LAD_KomponentenFehler_01 "Übertragung OBD relevanter Fehlerpfade vom Secondary zum Primary Steuergerät. 
Zuordnung der generischen Komponentenfehler muss zwischen Sender und Empfänger abgestimmt werden.";
CM_ SG_ 2589283472 LAD_KomponentenFehler_02 "Übertragung OBD relevanter Fehlerpfade vom Secondary zum Primary Steuergerät. 
Zuordnung der generischen Komponentenfehler muss zwischen Sender und Empfänger abgestimmt werden.";
CM_ SG_ 2589283472 LAD_KomponentenFehler_03 "Übertragung OBD relevanter Fehlerpfade vom Secondary zum Primary Steuergerät. 
Zuordnung der generischen Komponentenfehler muss zwischen Sender und Empfänger abgestimmt werden.";
CM_ SG_ 2589283472 LAD_KomponentenFehler_04 "Übertragung OBD relevanter Fehlerpfade vom Secondary zum Primary Steuergerät. 
Zuordnung der generischen Komponentenfehler muss zwischen Sender und Empfänger abgestimmt werden.";
CM_ SG_ 2589283472 LAD_KomponentenFehler_05 "Übertragung OBD relevanter Fehlerpfade vom Secondary zum Primary Steuergerät. 
Zuordnung der generischen Komponentenfehler muss zwischen Sender und Empfänger abgestimmt werden.";
CM_ SG_ 2589283472 LAD_KomponentenFehler_06 "Übertragung OBD relevanter Fehlerpfade vom Secondary zum Primary Steuergerät. 
Zuordnung der generischen Komponentenfehler muss zwischen Sender und Empfänger abgestimmt werden.";
CM_ SG_ 2589283472 LAD_KomponentenFehler_07 "Übertragung OBD relevanter Fehlerpfade vom Secondary zum Primary Steuergerät. 
Zuordnung der generischen Komponentenfehler muss zwischen Sender und Empfänger abgestimmt werden.";
CM_ SG_ 2589283472 LAD_KomponentenFehler_08 "Übertragung OBD relevanter Fehlerpfade vom Secondary zum Primary Steuergerät. 
Zuordnung der generischen Komponentenfehler muss zwischen Sender und Empfänger abgestimmt werden.";
CM_ SG_ 2589283472 LAD_KomponentenFehler_09 "Übertragung OBD relevanter Fehlerpfade vom Secondary zum Primary Steuergerät. 
Zuordnung der generischen Komponentenfehler muss zwischen Sender und Empfänger abgestimmt werden.";
CM_ SG_ 2589283472 LAD_KomponentenFehler_10 "Übertragung OBD relevanter Fehlerpfade vom Secondary zum Primary Steuergerät. 
Zuordnung der generischen Komponentenfehler muss zwischen Sender und Empfänger abgestimmt werden.";
CM_ SG_ 2589283472 LAD_KomponentenFehler_11 "Übertragung OBD relevanter Fehlerpfade vom Secondary zum Primary Steuergerät. 
Zuordnung der generischen Komponentenfehler muss zwischen Sender und Empfänger abgestimmt werden.";
CM_ SG_ 2589283472 LAD_KomponentenFehler_12 "Übertragung OBD relevanter Fehlerpfade vom Secondary zum Primary Steuergerät. 
Zuordnung der generischen Komponentenfehler muss zwischen Sender und Empfänger abgestimmt werden.";
CM_ SG_ 2589283472 LAD_KomponentenFehler_13 "Übertragung OBD relevanter Fehlerpfade vom Secondary zum Primary Steuergerät. 
Zuordnung der generischen Komponentenfehler muss zwischen Sender und Empfänger abgestimmt werden.";
CM_ SG_ 2589283472 LAD_KomponentenFehler_14 "Übertragung OBD relevanter Fehlerpfade vom Secondary zum Primary Steuergerät. 
Zuordnung der generischen Komponentenfehler muss zwischen Sender und Empfänger abgestimmt werden.";
CM_ SG_ 2589283472 LAD_KomponentenFehler_15 "Übertragung OBD relevanter Fehlerpfade vom Secondary zum Primary Steuergerät. 
Zuordnung der generischen Komponentenfehler muss zwischen Sender und Empfänger abgestimmt werden.";
CM_ SG_ 2589283472 LAD_KomponentenFehler_16 "Übertragung OBD relevanter Fehlerpfade vom Secondary zum Primary Steuergerät. 
Zuordnung der generischen Komponentenfehler muss zwischen Sender und Empfänger abgestimmt werden.";
CM_ SG_ 2589283472 LAD_KomponentenFehler_17 "Übertragung OBD relevanter Fehlerpfade vom Secondary zum Primary Steuergerät. 
Zuordnung der generischen Komponentenfehler muss zwischen Sender und Empfänger abgestimmt werden.";
CM_ SG_ 2589283472 LAD_KomponentenFehler_18 "Übertragung OBD relevanter Fehlerpfade vom Secondary zum Primary Steuergerät. 
Zuordnung der generischen Komponentenfehler muss zwischen Sender und Empfänger abgestimmt werden.";
CM_ SG_ 2589283472 LAD_KomponentenFehler_19 "Übertragung OBD relevanter Fehlerpfade vom Secondary zum Primary Steuergerät. 
Zuordnung der generischen Komponentenfehler muss zwischen Sender und Empfänger abgestimmt werden.";
CM_ SG_ 2589283472 LAD_KomponentenFehler_20 "Übertragung OBD relevanter Fehlerpfade vom Secondary zum Primary Steuergerät. 
Zuordnung der generischen Komponentenfehler muss zwischen Sender und Empfänger abgestimmt werden.";
CM_ SG_ 2589283472 LAD_KomponentenFehler_21 "Übertragung OBD relevanter Fehlerpfade vom Secondary zum Primary Steuergerät. 
Zuordnung der generischen Komponentenfehler muss zwischen Sender und Empfänger abgestimmt werden.";
CM_ SG_ 2589283472 LAD_KomponentenFehler_22 "Übertragung OBD relevanter Fehlerpfade vom Secondary zum Primary Steuergerät. 
Zuordnung der generischen Komponentenfehler muss zwischen Sender und Empfänger abgestimmt werden.";
CM_ SG_ 2589283472 LAD_KomponentenFehler_23 "Übertragung OBD relevanter Fehlerpfade vom Secondary zum Primary Steuergerät. 
Zuordnung der generischen Komponentenfehler muss zwischen Sender und Empfänger abgestimmt werden.";
CM_ SG_ 2589283472 LAD_KomponentenFehler_24 "Übertragung OBD relevanter Fehlerpfade vom Secondary zum Primary Steuergerät. 
Zuordnung der generischen Komponentenfehler muss zwischen Sender und Empfänger abgestimmt werden.";
CM_ SG_ 2589283472 LAD_KomponentenFehler_25 "Übertragung OBD relevanter Fehlerpfade vom Secondary zum Primary Steuergerät. 
Zuordnung der generischen Komponentenfehler muss zwischen Sender und Empfänger abgestimmt werden.";
CM_ SG_ 2589283472 LAD_KomponentenFehler_26 "Übertragung OBD relevanter Fehlerpfade vom Secondary zum Primary Steuergerät. 
Zuordnung der generischen Komponentenfehler muss zwischen Sender und Empfänger abgestimmt werden.";
CM_ SG_ 2589283472 LAD_KomponentenFehler_27 "Übertragung OBD relevanter Fehlerpfade vom Secondary zum Primary Steuergerät. 
Zuordnung der generischen Komponentenfehler muss zwischen Sender und Empfänger abgestimmt werden.";
CM_ SG_ 2589283472 LAD_KomponentenFehler_28 "Übertragung OBD relevanter Fehlerpfade vom Secondary zum Primary Steuergerät. 
Zuordnung der generischen Komponentenfehler muss zwischen Sender und Empfänger abgestimmt werden.";
CM_ SG_ 2589283472 LAD_KomponentenFehler_29 "Übertragung OBD relevanter Fehlerpfade vom Secondary zum Primary Steuergerät. 
Zuordnung der generischen Komponentenfehler muss zwischen Sender und Empfänger abgestimmt werden.";
CM_ SG_ 2589283472 LAD_KomponentenFehler_30 "Übertragung OBD relevanter Fehlerpfade vom Secondary zum Primary Steuergerät. 
Zuordnung der generischen Komponentenfehler muss zwischen Sender und Empfänger abgestimmt werden.";
CM_ SG_ 2589283472 LAD_KomponentenFehler_31 "Übertragung OBD relevanter Fehlerpfade vom Secondary zum Primary Steuergerät. 
Zuordnung der generischen Komponentenfehler muss zwischen Sender und Empfänger abgestimmt werden.";
CM_ SG_ 2589283472 LAD_KomponentenFehler_32 "Übertragung OBD relevanter Fehlerpfade vom Secondary zum Primary Steuergerät. 
Zuordnung der generischen Komponentenfehler muss zwischen Sender und Empfänger abgestimmt werden.";
BA_DEF_ BO_  "DiagRequest" ENUM  "No","Yes";
BA_DEF_ BO_  "DiagResponse" ENUM  "No","Yes";
BA_DEF_ BO_  "DiagState" ENUM  "No","Yes";
BA_DEF_ BO_  "GenMsgChkConstant" HEX 0 4095;
BA_DEF_ BO_  "GenMsgCycleTime" INT 0 65535;
BA_DEF_ BO_  "GenMsgCycleTimeFast" INT 0 65535;
BA_DEF_ BO_  "GenMsgDelayTime" INT 0 100000;
BA_DEF_ BO_  "GenMsgILSupport" ENUM  "No","Yes";
BA_DEF_ BO_  "GenMsgNrOfRepetition" INT 0 100;
BA_DEF_ BO_  "GenMsgPDUConstants" STRING ;
BA_DEF_ BO_  "GenMsgSendType" ENUM  "Cyclic","not_used","not_used","not_used","not_used","not_used","not_used","IfActive","NoMsgSendType";
BA_DEF_ BO_  "GenMsgStartDelayTime" INT 0 100000;
BA_DEF_ BO_  "NmMessage" ENUM  "No","Yes";
BA_DEF_ BO_  "NmhMessage" ENUM  "No","Yes";
BA_DEF_ BO_  "MsgType" ENUM  "Application","NM ","NMH","TP2.0","ISO-TP ","BAP","EID","KS","XCP_PRE_CONFIGURED","XCP_RUNTIME_CONFIGURED";
BA_DEF_ BO_  "VAGTP20_API" HEX 0 255;
BA_DEF_ BO_  "VAGTP20_DynConnection" ENUM  "No","Yes";
BA_DEF_ BO_  "VAGTP20_DynSetup" ENUM  "No","Yes";
BA_DEF_ BO_  "VAGTP20_StatConnection" ENUM  "No","Yes";
BA_DEF_ SG_  "GenSigActiveRepetitions" INT -2147483648 2147483647;
BA_DEF_ SG_  "GenSigInactiveValue" INT -2147483648 2147483647;
BA_DEF_ SG_  "GenSigSendType" ENUM  "Cyclic","OnWrite","OnWriteWithRepetition","OnChange","OnChangeWithRepetition","IfActive","IfActiveWithRepetition","NoSigSendType","OnChangeAndIfActive","OnChangeAndIfActiveWithRepetition";
BA_DEF_ SG_  "GenSigStartValue" INT -2147483648 2147483647;
BA_DEF_ SG_  "NWM-WakeupAllowed" ENUM  "No","Yes";
BA_DEF_ SG_  "GenSigFuncType" ENUM  "NoFunction","MsgCounter","CRC-8","XOR","XOR-2","DatedBit","SW-Kl15","CHK","Constant","Protocol","CRC-8-SAE_J1850","CRC-32","DataLength","DataID","MsgCounter16","SOK-Signatur","Cluster";
BA_DEF_ SG_  "GenSigSwitchedByIgnition" ENUM  "No","Yes";
BA_DEF_ SG_  "Fehlerwert" HEX 0 2147483647;
BA_DEF_ SG_  "GenSigMissingSourceValue" HEX 0 2147483647;
BA_DEF_REL_ BU_SG_REL_  "GenSigTimeoutTime" INT 0 65535;
BA_DEF_DEF_REL_ "GenSigTimeoutTime" 0;
BA_DEF_DEF_  "DiagRequest" "No";
BA_DEF_DEF_  "DiagResponse" "No";
BA_DEF_DEF_  "DiagState" "No";
BA_DEF_DEF_  "GenMsgChkConstant" 0;
BA_DEF_DEF_  "GenMsgCycleTime" 0;
BA_DEF_DEF_  "GenMsgCycleTimeFast" 0;
BA_DEF_DEF_  "GenMsgDelayTime" 0;
BA_DEF_DEF_  "GenMsgILSupport" "No";
BA_DEF_DEF_  "GenMsgNrOfRepetition" 0;
BA_DEF_DEF_  "GenMsgPDUConstants" "";
BA_DEF_DEF_  "GenMsgSendType" "NoMsgSendType";
BA_DEF_DEF_  "GenMsgStartDelayTime" 0;
BA_DEF_DEF_  "NmMessage" "No";
BA_DEF_DEF_  "NmhMessage" "No";
BA_DEF_DEF_  "MsgType" "Application";
BA_DEF_DEF_  "VAGTP20_API" 0;
BA_DEF_DEF_  "VAGTP20_DynConnection" "No";
BA_DEF_DEF_  "VAGTP20_DynSetup" "No";
BA_DEF_DEF_  "VAGTP20_StatConnection" "No";
BA_DEF_DEF_  "GenSigActiveRepetitions" 0;
BA_DEF_DEF_  "GenSigInactiveValue" 0;
BA_DEF_DEF_  "GenSigSendType" "NoSigSendType";
BA_DEF_DEF_  "GenSigStartValue" 0;
BA_DEF_DEF_  "NWM-WakeupAllowed" "No";
BA_DEF_DEF_  "GenSigFuncType" "NoFunction";
BA_DEF_DEF_  "GenSigSwitchedByIgnition" "Yes";
BA_DEF_DEF_  "Fehlerwert" 0;
BA_DEF_DEF_  "GenSigMissingSourceValue" 0;
BA_ "GenMsgSendType" BO_ 2549088437 0;
BA_ "GenMsgILSupport" BO_ 2549088437 1;
BA_ "GenMsgCycleTime" BO_ 2549088437 500;
BA_ "GenMsgStartDelayTime" BO_ 2549088272 75;
BA_ "GenMsgSendType" BO_ 2549088272 0;
BA_ "GenMsgILSupport" BO_ 2549088272 1;
BA_ "GenMsgCycleTime" BO_ 2549088272 500;
BA_ "GenMsgSendType" BO_ 2549088379 0;
BA_ "GenMsgILSupport" BO_ 2549088379 1;
BA_ "GenMsgCycleTime" BO_ 2549088379 500;
BA_ "GenMsgSendType" BO_ 2549088324 0;
BA_ "GenMsgILSupport" BO_ 2549088324 1;
BA_ "GenMsgCycleTime" BO_ 2549088324 500;
BA_ "GenMsgSendType" BO_ 2549088454 0;
BA_ "GenMsgILSupport" BO_ 2549088454 1;
BA_ "GenMsgCycleTime" BO_ 2549088454 500;
BA_ "GenMsgSendType" BO_ 2549088257 0;
BA_ "GenMsgILSupport" BO_ 2549088257 1;
BA_ "GenMsgCycleTime" BO_ 2549088257 500;
BA_ "GenMsgSendType" BO_ 2549088259 0;
BA_ "GenMsgILSupport" BO_ 2549088259 1;
BA_ "GenMsgCycleTime" BO_ 2549088259 500;
BA_ "GenMsgSendType" BO_ 2549088329 0;
BA_ "GenMsgILSupport" BO_ 2549088329 1;
BA_ "GenMsgCycleTime" BO_ 2549088329 500;
BA_ "GenMsgSendType" BO_ 2549088322 0;
BA_ "GenMsgILSupport" BO_ 2549088322 1;
BA_ "GenMsgCycleTime" BO_ 2549088322 500;
BA_ "GenMsgSendType" BO_ 779 0;
BA_ "GenMsgILSupport" BO_ 779 1;
BA_ "GenMsgCycleTime" BO_ 779 50;
BA_ "GenMsgSendType" BO_ 1719 0;
BA_ "GenMsgILSupport" BO_ 1719 1;
BA_ "GenMsgDelayTime" BO_ 1719 100;
BA_ "GenMsgCycleTime" BO_ 1719 1000;
BA_ "MsgType" BO_ 2549875067 4;
BA_ "MsgType" BO_ 2550006139 4;
BA_ "MsgType" BO_ 2549875142 4;
BA_ "MsgType" BO_ 2550006214 4;
BA_ "MsgType" BO_ 2549875012 4;
BA_ "MsgType" BO_ 2550006084 4;
BA_ "MsgType" BO_ 2549899473 4;
BA_ "MsgType" BO_ 2550030545 4;
BA_ "MsgType" BO_ 2549899474 4;
BA_ "MsgType" BO_ 2550030546 4;
BA_ "MsgType" BO_ 2549899475 4;
BA_ "MsgType" BO_ 2550030547 4;
BA_ "MsgType" BO_ 2549899476 4;
BA_ "MsgType" BO_ 2550030548 4;
BA_ "MsgType" BO_ 2549899477 4;
BA_ "MsgType" BO_ 2550030549 4;
BA_ "MsgType" BO_ 2549899478 4;
BA_ "MsgType" BO_ 2550030550 4;
BA_ "MsgType" BO_ 2549899479 4;
BA_ "MsgType" BO_ 2550030551 4;
BA_ "MsgType" BO_ 2549899480 4;
BA_ "MsgType" BO_ 2550030552 4;
BA_ "MsgType" BO_ 2549899481 4;
BA_ "MsgType" BO_ 2550030553 4;
BA_ "MsgType" BO_ 2549899482 4;
BA_ "MsgType" BO_ 2550030554 4;
BA_ "MsgType" BO_ 2549899483 4;
BA_ "MsgType" BO_ 2550030555 4;
BA_ "MsgType" BO_ 2549899484 4;
BA_ "MsgType" BO_ 2550030556 4;
BA_ "MsgType" BO_ 2549899505 4;
BA_ "MsgType" BO_ 2550030577 4;
BA_ "MsgType" BO_ 2549899506 4;
BA_ "MsgType" BO_ 2550030578 4;
BA_ "MsgType" BO_ 2549899507 4;
BA_ "MsgType" BO_ 2550030579 4;
BA_ "GenMsgSendType" BO_ 2463978640 0;
BA_ "GenMsgPDUConstants" BO_ 2463978640 "0x48,0x52,0xa7,0xe6,0x83,0x2b,0x8c,0xfb,0x7b,0x64,0x58,0x50,0xbc,0xb3,0x0f,0x9c";
BA_ "GenMsgILSupport" BO_ 2463978640 1;
BA_ "GenMsgCycleTime" BO_ 2463978640 100;
BA_ "GenMsgSendType" BO_ 2463978644 0;
BA_ "GenMsgILSupport" BO_ 2463978644 1;
BA_ "GenMsgCycleTime" BO_ 2463978644 100;
BA_ "GenMsgSendType" BO_ 2463978645 0;
BA_ "GenMsgILSupport" BO_ 2463978645 1;
BA_ "GenMsgCycleTime" BO_ 2463978645 100;
BA_ "GenMsgSendType" BO_ 2589283493 0;
BA_ "GenMsgILSupport" BO_ 2589283493 1;
BA_ "GenMsgCycleTime" BO_ 2589283493 1000;
BA_ "GenMsgSendType" BO_ 2589283392 0;
BA_ "GenMsgILSupport" BO_ 2589283392 1;
BA_ "GenMsgCycleTime" BO_ 2589283392 500;
BA_ "GenMsgSendType" BO_ 2589283688 0;
BA_ "GenMsgILSupport" BO_ 2589283688 1;
BA_ "GenMsgCycleTime" BO_ 2589283688 1000;
BA_ "GenMsgSendType" BO_ 1380 0;
BA_ "GenMsgPDUConstants" BO_ 1380 "0x24,0x24,0x24,0x24,0x24,0x24,0x24,0x24,0x24,0x24,0x24,0x24,0x24,0x24,0x24,0x24";
BA_ "GenMsgNrOfRepetition" BO_ 1380 5;
BA_ "GenMsgILSupport" BO_ 1380 1;
BA_ "GenMsgDelayTime" BO_ 1380 100;
BA_ "GenMsgCycleTimeFast" BO_ 1380 100;
BA_ "GenMsgCycleTime" BO_ 1380 1000;
BA_ "GenMsgChkConstant" BO_ 1380 36;
BA_ "GenMsgSendType" BO_ 1662 0;
BA_ "GenMsgPDUConstants" BO_ 1662 "0x25,0x25,0x25,0x25,0x25,0x25,0x25,0x25,0x25,0x25,0x25,0x25,0x25,0x25,0x25,0x25";
BA_ "GenMsgILSupport" BO_ 1662 1;
BA_ "GenMsgDelayTime" BO_ 1662 50;
BA_ "GenMsgCycleTime" BO_ 1662 1000;
BA_ "GenMsgChkConstant" BO_ 1662 37;
BA_ "GenMsgSendType" BO_ 2463978642 0;
BA_ "GenMsgILSupport" BO_ 2463978642 1;
BA_ "GenMsgCycleTime" BO_ 2463978642 100;
BA_ "GenMsgSendType" BO_ 2463978643 0;
BA_ "GenMsgPDUConstants" BO_ 2463978643 "0x74,0x7e,0x45,0xe8,0x3c,0xd0,0x13,0x1f,0x4e,0x3a,0x88,0x0b,0x7d,0xd2,0x6d,0xab";
BA_ "GenMsgILSupport" BO_ 2463978643 1;
BA_ "GenMsgCycleTime" BO_ 2463978643 100;
BA_ "GenMsgSendType" BO_ 2589283663 0;
BA_ "GenMsgILSupport" BO_ 2589283663 1;
BA_ "GenMsgDelayTime" BO_ 2589283663 100;
BA_ "GenMsgCycleTime" BO_ 2589283663 1000;
BA_ "GenMsgSendType" BO_ 2589283415 0;
BA_ "GenMsgILSupport" BO_ 2589283415 1;
BA_ "GenMsgCycleTime" BO_ 2589283415 1000;
BA_ "GenMsgSendType" BO_ 2589283472 0;
BA_ "GenMsgILSupport" BO_ 2589283472 1;
BA_ "GenMsgCycleTime" BO_ 2589283472 500;
BA_ "GenSigSendType" SG_ 2549088437 FCU_KompSchutz 0;
BA_ "GenSigSendType" SG_ 2549088437 FCU_Abschaltstufe 0;
BA_ "GenSigSwitchedByIgnition" SG_ 2549088437 FCU_Transport_Mode 0;
BA_ "GenSigSendType" SG_ 2549088437 FCU_Transport_Mode 0;
BA_ "GenSigSwitchedByIgnition" SG_ 2549088437 FCU_Nachlauftyp 0;
BA_ "GenSigStartValue" SG_ 2549088437 FCU_Nachlauftyp 2;
BA_ "GenSigSendType" SG_ 2549088437 FCU_Nachlauftyp 0;
BA_ "GenSigSwitchedByIgnition" SG_ 2549088437 FCU_SNI 0;
BA_ "GenSigStartValue" SG_ 2549088437 FCU_SNI 181;
BA_ "GenSigSendType" SG_ 2549088437 FCU_SNI 0;
BA_ "GenSigSwitchedByIgnition" SG_ 2549088437 KN_FCU_ECUKnockOutTimer 0;
BA_ "GenSigSendType" SG_ 2549088437 KN_FCU_ECUKnockOutTimer 0;
BA_ "GenSigSwitchedByIgnition" SG_ 2549088437 KN_FCU_BusKnockOut 0;
BA_ "GenSigSendType" SG_ 2549088437 KN_FCU_BusKnockOut 0;
BA_ "GenSigSwitchedByIgnition" SG_ 2549088437 KN_FCU_BusKnockOutTimer 0;
BA_ "GenSigSendType" SG_ 2549088437 KN_FCU_BusKnockOutTimer 0;
BA_ "GenSigSwitchedByIgnition" SG_ 2549088437 NM_FCU_Wakeup 0;
BA_ "GenSigSendType" SG_ 2549088437 NM_FCU_Wakeup 0;
BA_ "GenSigSwitchedByIgnition" SG_ 2549088437 KN_FCU_ECUKnockOut 0;
BA_ "GenSigSendType" SG_ 2549088437 KN_FCU_ECUKnockOut 0;
BA_ "GenSigSendType" SG_ 2549088437 KN_FCU_DiagPfad 0;
BA_ "GenSigSwitchedByIgnition" SG_ 2549088437 NM_FCU_Lokalaktiv 0;
BA_ "GenSigSendType" SG_ 2549088437 NM_FCU_Lokalaktiv 0;
BA_ "GenSigSwitchedByIgnition" SG_ 2549088437 NM_FCU_Subsystemaktiv 0;
BA_ "GenSigSendType" SG_ 2549088437 NM_FCU_Subsystemaktiv 0;
BA_ "GenSigSwitchedByIgnition" SG_ 2549088437 FCU_KD_Fehler 0;
BA_ "GenSigSendType" SG_ 2549088437 FCU_KD_Fehler 0;
BA_ "GenSigSwitchedByIgnition" SG_ 2549088272 Gateway_KompSchutz 0;
BA_ "GenSigSendType" SG_ 2549088272 Gateway_KompSchutz 0;
BA_ "GenSigSwitchedByIgnition" SG_ 2549088272 Gateway_Abschaltstufe 0;
BA_ "GenSigSendType" SG_ 2549088272 Gateway_Abschaltstufe 0;
BA_ "GenSigSwitchedByIgnition" SG_ 2549088272 Gateway_Transport_Mode 0;
BA_ "GenSigSendType" SG_ 2549088272 Gateway_Transport_Mode 0;
BA_ "GenSigSwitchedByIgnition" SG_ 2549088272 Gateway_Nachlauftyp 0;
BA_ "GenSigStartValue" SG_ 2549088272 Gateway_Nachlauftyp 2;
BA_ "GenSigSendType" SG_ 2549088272 Gateway_Nachlauftyp 0;
BA_ "GenSigSwitchedByIgnition" SG_ 2549088272 Gateway_SNI 0;
BA_ "GenSigStartValue" SG_ 2549088272 Gateway_SNI 16;
BA_ "GenSigSendType" SG_ 2549088272 Gateway_SNI 0;
BA_ "GenSigSwitchedByIgnition" SG_ 2549088272 Gateway_Matrix_Version 0;
BA_ "GenSigSendType" SG_ 2549088272 Gateway_Matrix_Version 0;
BA_ "GenSigSwitchedByIgnition" SG_ 2549088272 Gateway_Matrix_Generation 0;
BA_ "GenSigSendType" SG_ 2549088272 Gateway_Matrix_Generation 0;
BA_ "GenSigSwitchedByIgnition" SG_ 2549088272 NM_Gateway_Wakeup 0;
BA_ "NWM-WakeupAllowed" SG_ 2549088272 NM_Gateway_Wakeup 1;
BA_ "GenSigSendType" SG_ 2549088272 NM_Gateway_Wakeup 0;
BA_ "GenSigSwitchedByIgnition" SG_ 2549088272 NM_Gateway_Lokalaktiv 0;
BA_ "GenSigSendType" SG_ 2549088272 NM_Gateway_Lokalaktiv 0;
BA_ "GenSigSendType" SG_ 2549088272 NM_Gateway_Subsystemaktiv 0;
BA_ "GenSigSendType" SG_ 2549088272 GW_KD_Fehler 0;
BA_ "GenSigSwitchedByIgnition" SG_ 2549088379 Hybrid_KompSchutz 0;
BA_ "GenSigSendType" SG_ 2549088379 Hybrid_KompSchutz 0;
BA_ "GenSigSwitchedByIgnition" SG_ 2549088379 Hybrid_01_Abschaltstufe 0;
BA_ "GenSigSendType" SG_ 2549088379 Hybrid_01_Abschaltstufe 0;
BA_ "GenSigSwitchedByIgnition" SG_ 2549088379 Hybrid_01_Transport_Mode 0;
BA_ "GenSigSendType" SG_ 2549088379 Hybrid_01_Transport_Mode 0;
BA_ "GenSigSwitchedByIgnition" SG_ 2549088379 Hybrid_Nachlauftyp 0;
BA_ "GenSigStartValue" SG_ 2549088379 Hybrid_Nachlauftyp 2;
BA_ "GenSigSendType" SG_ 2549088379 Hybrid_Nachlauftyp 0;
BA_ "GenSigSwitchedByIgnition" SG_ 2549088379 Hybrid_01_SNI 0;
BA_ "GenSigStartValue" SG_ 2549088379 Hybrid_01_SNI 123;
BA_ "GenSigSendType" SG_ 2549088379 Hybrid_01_SNI 0;
BA_ "GenSigSwitchedByIgnition" SG_ 2549088379 KN_BMS_ECUKnockOutTimer 0;
BA_ "GenSigSendType" SG_ 2549088379 KN_BMS_ECUKnockOutTimer 0;
BA_ "GenSigSwitchedByIgnition" SG_ 2549088379 KN_BMS_BusKnockOut 0;
BA_ "GenSigSendType" SG_ 2549088379 KN_BMS_BusKnockOut 0;
BA_ "GenSigSwitchedByIgnition" SG_ 2549088379 KN_BMS_BusKnockOutTimer 0;
BA_ "GenSigSendType" SG_ 2549088379 KN_BMS_BusKnockOutTimer 0;
BA_ "GenSigSwitchedByIgnition" SG_ 2549088379 NM_Hybrid_01_Wakeup 0;
BA_ "NWM-WakeupAllowed" SG_ 2549088379 NM_Hybrid_01_Wakeup 1;
BA_ "GenSigSendType" SG_ 2549088379 NM_Hybrid_01_Wakeup 0;
BA_ "GenSigSwitchedByIgnition" SG_ 2549088379 KN_BMS_ECUKnockOut 0;
BA_ "GenSigSendType" SG_ 2549088379 KN_BMS_ECUKnockOut 0;
BA_ "GenSigSwitchedByIgnition" SG_ 2549088379 Hybrid_01_Lokalaktiv 0;
BA_ "GenSigSendType" SG_ 2549088379 Hybrid_01_Lokalaktiv 0;
BA_ "GenSigSwitchedByIgnition" SG_ 2549088379 Hybrid_01_Subsystemaktiv 0;
BA_ "GenSigSendType" SG_ 2549088379 Hybrid_01_Subsystemaktiv 0;
BA_ "GenSigSwitchedByIgnition" SG_ 2549088379 BMS_HYB_KD_Fehler 0;
BA_ "GenSigSendType" SG_ 2549088379 BMS_HYB_KD_Fehler 0;
BA_ "GenSigSwitchedByIgnition" SG_ 2549088324 LG_KompSchutz 0;
BA_ "GenSigSendType" SG_ 2549088324 LG_KompSchutz 0;
BA_ "GenSigSendType" SG_ 2549088324 LG_Abschaltstufe 0;
BA_ "GenSigSendType" SG_ 2549088324 LG_Transport_Mode 0;
BA_ "GenSigSwitchedByIgnition" SG_ 2549088324 LG_Nachlauftyp 0;
BA_ "GenSigStartValue" SG_ 2549088324 LG_Nachlauftyp 2;
BA_ "GenSigSendType" SG_ 2549088324 LG_Nachlauftyp 0;
BA_ "GenSigSwitchedByIgnition" SG_ 2549088324 LG_SNI 0;
BA_ "GenSigStartValue" SG_ 2549088324 LG_SNI 68;
BA_ "GenSigSendType" SG_ 2549088324 LG_SNI 0;
BA_ "GenSigSwitchedByIgnition" SG_ 2549088324 KN_Ladegeraet_ECUKnockOutTimer 0;
BA_ "GenSigSendType" SG_ 2549088324 KN_Ladegeraet_ECUKnockOutTimer 0;
BA_ "GenSigSwitchedByIgnition" SG_ 2549088324 KN_Ladegeraet_BusKnockOut 0;
BA_ "GenSigSendType" SG_ 2549088324 KN_Ladegeraet_BusKnockOut 0;
BA_ "GenSigSwitchedByIgnition" SG_ 2549088324 KN_Ladegeraet_BusKnockOutTimer 0;
BA_ "GenSigSendType" SG_ 2549088324 KN_Ladegeraet_BusKnockOutTimer 0;
BA_ "GenSigSwitchedByIgnition" SG_ 2549088324 NM_Ladegeraet_Wakeup 0;
BA_ "NWM-WakeupAllowed" SG_ 2549088324 NM_Ladegeraet_Wakeup 1;
BA_ "GenSigSendType" SG_ 2549088324 NM_Ladegeraet_Wakeup 0;
BA_ "GenSigSwitchedByIgnition" SG_ 2549088324 KN_Ladegeraet_ECUKnockOut 0;
BA_ "GenSigSendType" SG_ 2549088324 KN_Ladegeraet_ECUKnockOut 0;
BA_ "GenSigSwitchedByIgnition" SG_ 2549088324 NMH_Ladegeraet_Lokalaktiv 0;
BA_ "GenSigSendType" SG_ 2549088324 NMH_Ladegeraet_Lokalaktiv 0;
BA_ "GenSigSwitchedByIgnition" SG_ 2549088324 NMH_Ladegeraet_Subsystemaktiv 0;
BA_ "GenSigSendType" SG_ 2549088324 NMH_Ladegeraet_Subsystemaktiv 0;
BA_ "GenSigSwitchedByIgnition" SG_ 2549088324 LG_KD_Fehler 0;
BA_ "GenSigSendType" SG_ 2549088324 LG_KD_Fehler 0;
BA_ "GenSigSendType" SG_ 2549088454 Ladegeraet_2_KompSchutz 0;
BA_ "GenSigSendType" SG_ 2549088454 Ladegeraet_2_Abschaltstufe 0;
BA_ "GenSigSwitchedByIgnition" SG_ 2549088454 Ladegeraet_2_Transport_Mode 0;
BA_ "GenSigSendType" SG_ 2549088454 Ladegeraet_2_Transport_Mode 0;
BA_ "GenSigSwitchedByIgnition" SG_ 2549088454 Ladegeraet_2_Nachlauftyp 0;
BA_ "GenSigStartValue" SG_ 2549088454 Ladegeraet_2_Nachlauftyp 2;
BA_ "GenSigSendType" SG_ 2549088454 Ladegeraet_2_Nachlauftyp 0;
BA_ "GenSigSwitchedByIgnition" SG_ 2549088454 Ladegeraet_2_SNI 0;
BA_ "GenSigStartValue" SG_ 2549088454 Ladegeraet_2_SNI 198;
BA_ "GenSigSendType" SG_ 2549088454 Ladegeraet_2_SNI 0;
BA_ "GenSigSwitchedByIgnition" SG_ 2549088454 KN_Ladegeraet_2_ECUKnockOutTimer 0;
BA_ "GenSigSendType" SG_ 2549088454 KN_Ladegeraet_2_ECUKnockOutTimer 0;
BA_ "GenSigSwitchedByIgnition" SG_ 2549088454 KN_Ladegeraet_2_BusKnockOut 0;
BA_ "GenSigSendType" SG_ 2549088454 KN_Ladegeraet_2_BusKnockOut 0;
BA_ "GenSigSwitchedByIgnition" SG_ 2549088454 KN_Ladegeraet_2_BusKnockOutTimer 0;
BA_ "GenSigSendType" SG_ 2549088454 KN_Ladegeraet_2_BusKnockOutTimer 0;
BA_ "GenSigSwitchedByIgnition" SG_ 2549088454 NM_Ladegeraet_2_Wakeup 0;
BA_ "GenSigSendType" SG_ 2549088454 NM_Ladegeraet_2_Wakeup 0;
BA_ "GenSigSwitchedByIgnition" SG_ 2549088454 KN_Ladegeraet_2_ECUKnockOut 0;
BA_ "GenSigSendType" SG_ 2549088454 KN_Ladegeraet_2_ECUKnockOut 0;
BA_ "GenSigSwitchedByIgnition" SG_ 2549088454 NM_Ladegeraet_2_Lokalaktiv 0;
BA_ "GenSigSendType" SG_ 2549088454 NM_Ladegeraet_2_Lokalaktiv 0;
BA_ "GenSigSwitchedByIgnition" SG_ 2549088454 Ladegeraet2_KD_Fehler 0;
BA_ "GenSigSendType" SG_ 2549088454 Ladegeraet2_KD_Fehler 0;
BA_ "GenSigSendType" SG_ 2549088257 Sekundaer_01_KompSchutz 0;
BA_ "GenSigSwitchedByIgnition" SG_ 2549088257 Sekundaer_01_Abschaltstufe 0;
BA_ "GenSigSendType" SG_ 2549088257 Sekundaer_01_Abschaltstufe 0;
BA_ "GenSigSendType" SG_ 2549088257 Sekundaer_01_Transport_Mode 0;
BA_ "GenSigSwitchedByIgnition" SG_ 2549088257 Sekundaer_01_Nachlauftyp 0;
BA_ "GenSigStartValue" SG_ 2549088257 Sekundaer_01_Nachlauftyp 2;
BA_ "GenSigSendType" SG_ 2549088257 Sekundaer_01_Nachlauftyp 0;
BA_ "GenSigSwitchedByIgnition" SG_ 2549088257 Sekundaer_01_SNI 0;
BA_ "GenSigStartValue" SG_ 2549088257 Sekundaer_01_SNI 1;
BA_ "GenSigSendType" SG_ 2549088257 Sekundaer_01_SNI 0;
BA_ "GenSigSwitchedByIgnition" SG_ 2549088257 KN_Sekundaer_01_ECUKnockOutTimer 0;
BA_ "GenSigSendType" SG_ 2549088257 KN_Sekundaer_01_ECUKnockOutTimer 0;
BA_ "GenSigSwitchedByIgnition" SG_ 2549088257 KN_Sekundaer_01_BusKnockOut 0;
BA_ "GenSigSendType" SG_ 2549088257 KN_Sekundaer_01_BusKnockOut 0;
BA_ "GenSigSwitchedByIgnition" SG_ 2549088257 KN_Sekundaer_01_BusKnockOutTimer 0;
BA_ "GenSigSendType" SG_ 2549088257 KN_Sekundaer_01_BusKnockOutTimer 0;
BA_ "GenSigSwitchedByIgnition" SG_ 2549088257 NM_Sekundaer_01_Wakeup 0;
BA_ "GenSigSendType" SG_ 2549088257 NM_Sekundaer_01_Wakeup 0;
BA_ "GenSigSwitchedByIgnition" SG_ 2549088257 KN_Sekundaer_01_ECUKnockOut 0;
BA_ "GenSigSendType" SG_ 2549088257 KN_Sekundaer_01_ECUKnockOut 0;
BA_ "GenSigSwitchedByIgnition" SG_ 2549088257 NM_Sekundaer_01_Lokalaktiv 0;
BA_ "GenSigSendType" SG_ 2549088257 NM_Sekundaer_01_Lokalaktiv 0;
BA_ "GenSigSwitchedByIgnition" SG_ 2549088257 Sekundaer_01_KD_Fehler 0;
BA_ "GenSigSendType" SG_ 2549088257 Sekundaer_01_KD_Fehler 0;
BA_ "GenSigSendType" SG_ 2549088259 Sekundaer_03_KompSchutz 0;
BA_ "GenSigSwitchedByIgnition" SG_ 2549088259 Sekundaer_03_Abschaltstufe 0;
BA_ "GenSigSendType" SG_ 2549088259 Sekundaer_03_Abschaltstufe 0;
BA_ "GenSigSendType" SG_ 2549088259 Sekundaer_03_Transport_Mode 0;
BA_ "GenSigSwitchedByIgnition" SG_ 2549088259 Sekundaer_03_Nachlauftyp 0;
BA_ "GenSigStartValue" SG_ 2549088259 Sekundaer_03_Nachlauftyp 2;
BA_ "GenSigSendType" SG_ 2549088259 Sekundaer_03_Nachlauftyp 0;
BA_ "GenSigSwitchedByIgnition" SG_ 2549088259 Sekundaer_03_SNI 0;
BA_ "GenSigStartValue" SG_ 2549088259 Sekundaer_03_SNI 3;
BA_ "GenSigSendType" SG_ 2549088259 Sekundaer_03_SNI 0;
BA_ "GenSigSwitchedByIgnition" SG_ 2549088259 KN_Sekundaer_03_ECUKnockOutTimer 0;
BA_ "GenSigSendType" SG_ 2549088259 KN_Sekundaer_03_ECUKnockOutTimer 0;
BA_ "GenSigSwitchedByIgnition" SG_ 2549088259 KN_Sekundaer_03_ECUKnockOut 0;
BA_ "GenSigSendType" SG_ 2549088259 KN_Sekundaer_03_ECUKnockOut 0;
BA_ "GenSigSwitchedByIgnition" SG_ 2549088259 KN_Sekundaer_03_BusKnockOutTimer 0;
BA_ "GenSigSendType" SG_ 2549088259 KN_Sekundaer_03_BusKnockOutTimer 0;
BA_ "GenSigSwitchedByIgnition" SG_ 2549088259 Sekundaer_03_LEH_Wakeup 0;
BA_ "GenSigSendType" SG_ 2549088259 Sekundaer_03_LEH_Wakeup 0;
BA_ "GenSigSwitchedByIgnition" SG_ 2549088259 KN_Sekundaer_03_BusKnockOut 0;
BA_ "GenSigSendType" SG_ 2549088259 KN_Sekundaer_03_BusKnockOut 0;
BA_ "GenSigSwitchedByIgnition" SG_ 2549088259 Sekundaer_03_Lokalaktiv 0;
BA_ "GenSigSendType" SG_ 2549088259 Sekundaer_03_Lokalaktiv 0;
BA_ "GenSigSwitchedByIgnition" SG_ 2549088259 Sekundaer_03_KD_Fehler 0;
BA_ "GenSigSendType" SG_ 2549088259 Sekundaer_03_KD_Fehler 0;
BA_ "GenSigSendType" SG_ 2549088329 Sub_Gateway_KompSchutz 0;
BA_ "GenSigSwitchedByIgnition" SG_ 2549088329 Sub_Gateway_Abschaltstufe 0;
BA_ "GenSigSendType" SG_ 2549088329 Sub_Gateway_Abschaltstufe 0;
BA_ "GenSigSwitchedByIgnition" SG_ 2549088329 Sub_Gateway_Transport_Mode 0;
BA_ "GenSigSendType" SG_ 2549088329 Sub_Gateway_Transport_Mode 0;
BA_ "GenSigSwitchedByIgnition" SG_ 2549088329 Sub_Gateway_Nachlauftyp 0;
BA_ "GenSigStartValue" SG_ 2549088329 Sub_Gateway_Nachlauftyp 2;
BA_ "GenSigSendType" SG_ 2549088329 Sub_Gateway_Nachlauftyp 0;
BA_ "GenSigSwitchedByIgnition" SG_ 2549088329 Sub_Gateway_SNI 0;
BA_ "GenSigStartValue" SG_ 2549088329 Sub_Gateway_SNI 73;
BA_ "GenSigSendType" SG_ 2549088329 Sub_Gateway_SNI 0;
BA_ "GenSigSwitchedByIgnition" SG_ 2549088329 Sub_Gateway_BusKnockOutTimer 0;
BA_ "GenSigSendType" SG_ 2549088329 Sub_Gateway_BusKnockOutTimer 0;
BA_ "GenSigSwitchedByIgnition" SG_ 2549088329 NM_Sub_Gateway_Wakeup 0;
BA_ "NWM-WakeupAllowed" SG_ 2549088329 NM_Sub_Gateway_Wakeup 1;
BA_ "GenSigSendType" SG_ 2549088329 NM_Sub_Gateway_Wakeup 0;
BA_ "GenSigSwitchedByIgnition" SG_ 2549088329 NM_Sub_Gateway_Lokalaktiv 0;
BA_ "GenSigSendType" SG_ 2549088329 NM_Sub_Gateway_Lokalaktiv 0;
BA_ "GenSigSwitchedByIgnition" SG_ 2549088329 NM_Sub_Gateway_Subsystemaktiv 0;
BA_ "GenSigSendType" SG_ 2549088329 NM_Sub_Gateway_Subsystemaktiv 0;
BA_ "GenSigSwitchedByIgnition" SG_ 2549088329 Sub_Gateway_KD_Fehler 0;
BA_ "GenSigSendType" SG_ 2549088329 Sub_Gateway_KD_Fehler 0;
BA_ "GenSigSendType" SG_ 2549088322 TME_KompSchutz 0;
BA_ "GenSigSwitchedByIgnition" SG_ 2549088322 TME_Abschaltstufe 0;
BA_ "GenSigSendType" SG_ 2549088322 TME_Abschaltstufe 0;
BA_ "GenSigSwitchedByIgnition" SG_ 2549088322 TME_Transport_Mode 0;
BA_ "GenSigSendType" SG_ 2549088322 TME_Transport_Mode 0;
BA_ "GenSigSwitchedByIgnition" SG_ 2549088322 TME_Nachlauftyp 0;
BA_ "GenSigStartValue" SG_ 2549088322 TME_Nachlauftyp 2;
BA_ "GenSigSendType" SG_ 2549088322 TME_Nachlauftyp 0;
BA_ "GenSigSwitchedByIgnition" SG_ 2549088322 TME_SNI 0;
BA_ "GenSigStartValue" SG_ 2549088322 TME_SNI 66;
BA_ "GenSigSendType" SG_ 2549088322 TME_SNI 0;
BA_ "GenSigSwitchedByIgnition" SG_ 2549088322 KN_TME_BusKnockOutTimer 0;
BA_ "GenSigSendType" SG_ 2549088322 KN_TME_BusKnockOutTimer 0;
BA_ "GenSigSwitchedByIgnition" SG_ 2549088322 NM_TME_Wakeup 0;
BA_ "NWM-WakeupAllowed" SG_ 2549088322 NM_TME_Wakeup 1;
BA_ "GenSigSendType" SG_ 2549088322 NM_TME_Wakeup 0;
BA_ "GenSigSwitchedByIgnition" SG_ 2549088322 NMH_TME_Lokalaktiv 0;
BA_ "GenSigSendType" SG_ 2549088322 NMH_TME_Lokalaktiv 0;
BA_ "GenSigSwitchedByIgnition" SG_ 2549088322 NMH_TME_Subsystemaktiv 0;
BA_ "GenSigSendType" SG_ 2549088322 NMH_TME_Subsystemaktiv 0;
BA_ "GenSigSwitchedByIgnition" SG_ 2549088322 TME_KD_Fehler 0;
BA_ "GenSigSendType" SG_ 2549088322 TME_KD_Fehler 0;
BA_ "GenSigSwitchedByIgnition" SG_ 779 KBI_ABS_Lampe 0;
BA_ "GenSigSendType" SG_ 779 KBI_ABS_Lampe 0;
BA_ "GenSigSwitchedByIgnition" SG_ 779 KBI_ESP_Lampe 0;
BA_ "GenSigSendType" SG_ 779 KBI_ESP_Lampe 0;
BA_ "GenSigSwitchedByIgnition" SG_ 779 KBI_BKL_Lampe 0;
BA_ "GenSigSendType" SG_ 779 KBI_BKL_Lampe 0;
BA_ "GenSigSwitchedByIgnition" SG_ 779 KBI_Airbag_Lampe 0;
BA_ "GenSigSendType" SG_ 779 KBI_Airbag_Lampe 0;
BA_ "GenSigSwitchedByIgnition" SG_ 779 KBI_SILA_gueltig 0;
BA_ "GenSigSendType" SG_ 779 KBI_SILA_gueltig 0;
BA_ "GenSigSendType" SG_ 779 KBI_Lenkung_Lampe 0;
BA_ "GenSigSwitchedByIgnition" SG_ 779 KBI_Vorglueh_System_Lampe 0;
BA_ "GenSigSendType" SG_ 779 KBI_Vorglueh_System_Lampe 0;
BA_ "GenSigSwitchedByIgnition" SG_ 779 KBI_NV_in_Anzeige 0;
BA_ "GenSigSendType" SG_ 779 KBI_NV_in_Anzeige 0;
BA_ "GenSigSwitchedByIgnition" SG_ 779 Kombi_01_BZ 0;
BA_ "GenSigFuncType" SG_ 779 Kombi_01_BZ 1;
BA_ "GenSigSendType" SG_ 779 Kombi_01_BZ 0;
BA_ "GenSigSwitchedByIgnition" SG_ 779 KBI_Anzeigestatus_ACC 0;
BA_ "GenSigSendType" SG_ 779 KBI_Anzeigestatus_ACC 0;
BA_ "Fehlerwert" SG_ 779 KBI_Anzeigestatus_GRA 3;
BA_ "GenSigSwitchedByIgnition" SG_ 779 KBI_Anzeigestatus_GRA 0;
BA_ "GenSigSendType" SG_ 779 KBI_Anzeigestatus_GRA 0;
BA_ "GenSigSwitchedByIgnition" SG_ 779 KBI_Tankwarnung 0;
BA_ "GenSigSendType" SG_ 779 KBI_Tankwarnung 0;
BA_ "GenSigSwitchedByIgnition" SG_ 779 KBI_MFA_v_Einheit_01 0;
BA_ "GenSigSendType" SG_ 779 KBI_MFA_v_Einheit_01 0;
BA_ "GenSigSwitchedByIgnition" SG_ 779 KBI_im_Stellgliedtest 0;
BA_ "GenSigSendType" SG_ 779 KBI_im_Stellgliedtest 0;
BA_ "GenSigSwitchedByIgnition" SG_ 779 KBI_Anzeigefehler_LDW 0;
BA_ "GenSigSendType" SG_ 779 KBI_Anzeigefehler_LDW 0;
BA_ "GenSigSwitchedByIgnition" SG_ 779 KBI_Tankwarnung_ungueltig 0;
BA_ "GenSigStartValue" SG_ 779 KBI_Tankwarnung_ungueltig 1;
BA_ "GenSigSendType" SG_ 779 KBI_Tankwarnung_ungueltig 0;
BA_ "GenSigSendType" SG_ 779 KBI_Handbremse 0;
BA_ "GenSigSwitchedByIgnition" SG_ 779 KBI_V_Digital 0;
BA_ "GenSigSendType" SG_ 779 KBI_V_Digital 0;
BA_ "GenSigSwitchedByIgnition" SG_ 779 KBI_PLA_in_Anzeige 0;
BA_ "GenSigSendType" SG_ 779 KBI_PLA_in_Anzeige 0;
BA_ "GenSigSwitchedByIgnition" SG_ 779 KBI_Anzeigefehler_NV 0;
BA_ "GenSigSendType" SG_ 779 KBI_Anzeigefehler_NV 0;
BA_ "Fehlerwert" SG_ 779 KBI_Anzeigestatus_LIM 3;
BA_ "GenSigSwitchedByIgnition" SG_ 779 KBI_Anzeigestatus_LIM 0;
BA_ "GenSigSendType" SG_ 779 KBI_Anzeigestatus_LIM 0;
BA_ "GenSigSwitchedByIgnition" SG_ 779 KBI_ARA_in_Anzeige 0;
BA_ "GenSigSendType" SG_ 779 KBI_ARA_in_Anzeige 0;
BA_ "GenSigSwitchedByIgnition" SG_ 779 KBI_Taster_Lift 0;
BA_ "GenSigSendType" SG_ 779 KBI_Taster_Lift 0;
BA_ "GenSigSwitchedByIgnition" SG_ 779 KBI_Taster_Fahrwerk 0;
BA_ "GenSigSendType" SG_ 779 KBI_Taster_Fahrwerk 0;
BA_ "GenSigSwitchedByIgnition" SG_ 779 KBI_angez_Geschw 0;
BA_ "GenSigSendType" SG_ 779 KBI_angez_Geschw 0;
BA_ "GenSigSwitchedByIgnition" SG_ 779 KBI_Einheit_Tacho 0;
BA_ "GenSigSendType" SG_ 779 KBI_Einheit_Tacho 0;
BA_ "GenSigSwitchedByIgnition" SG_ 779 KBI_Konsistenz_ACC 0;
BA_ "GenSigSendType" SG_ 779 KBI_Konsistenz_ACC 0;
BA_ "GenSigSwitchedByIgnition" SG_ 779 KBI_Fehler_Anzeige_ACC 0;
BA_ "GenSigSendType" SG_ 779 KBI_Fehler_Anzeige_ACC 0;
BA_ "GenSigSwitchedByIgnition" SG_ 779 KBI_Anzeigefehler_SWA 0;
BA_ "GenSigSendType" SG_ 779 KBI_Anzeigefehler_SWA 0;
BA_ "GenSigSwitchedByIgnition" SG_ 779 KBI_Systemstatus 0;
BA_ "GenSigSendType" SG_ 779 KBI_Systemstatus 0;
BA_ "Fehlerwert" SG_ 1719 KBI_Kilometerstand 1048575;
BA_ "GenSigSwitchedByIgnition" SG_ 1719 KBI_Kilometerstand 0;
BA_ "GenSigStartValue" SG_ 1719 KBI_Kilometerstand 1048574;
BA_ "GenSigSendType" SG_ 1719 KBI_Kilometerstand 0;
BA_ "Fehlerwert" SG_ 1719 KBI_Standzeit_02 131071;
BA_ "GenSigSwitchedByIgnition" SG_ 1719 KBI_Standzeit_02 0;
BA_ "GenSigStartValue" SG_ 1719 KBI_Standzeit_02 131070;
BA_ "GenSigSendType" SG_ 1719 KBI_Standzeit_02 0;
BA_ "GenSigSwitchedByIgnition" SG_ 1719 KBI_LVDS_Lock 0;
BA_ "GenSigSendType" SG_ 1719 KBI_LVDS_Lock 3;
BA_ "GenSigSwitchedByIgnition" SG_ 1719 KBI_Reserve_Warnung_Sek 0;
BA_ "GenSigSendType" SG_ 1719 KBI_Reserve_Warnung_Sek 3;
BA_ "GenSigSwitchedByIgnition" SG_ 1719 KBI_RDK_Kalibrier_Anf 0;
BA_ "GenSigSendType" SG_ 1719 KBI_RDK_Kalibrier_Anf 3;
BA_ "Fehlerwert" SG_ 1719 KBI_Inhalt_Tank 127;
BA_ "GenSigSwitchedByIgnition" SG_ 1719 KBI_Inhalt_Tank 0;
BA_ "GenSigStartValue" SG_ 1719 KBI_Inhalt_Tank 126;
BA_ "GenSigSendType" SG_ 1719 KBI_Inhalt_Tank 0;
BA_ "GenSigSwitchedByIgnition" SG_ 1719 KBI_FStatus_Tank 0;
BA_ "GenSigSendType" SG_ 1719 KBI_FStatus_Tank 0;
BA_ "GenSigSendType" SG_ 1719 KBI_aktive_Laengsfunktion 3;
BA_ "GenSigSendType" SG_ 1719 KBI_FoD_PopUP_Quittiert 3;
BA_ "GenSigSendType" SG_ 1719 KBI_GRA_im_ACC 3;
BA_ "GenSigSwitchedByIgnition" SG_ 1719 KBI_Oelwechsel_durchgefuehrt 0;
BA_ "GenSigSendType" SG_ 1719 KBI_Oelwechsel_durchgefuehrt 0;
BA_ "GenSigSwitchedByIgnition" SG_ 1719 KBI_QBit_Aussen_Temp_gef 0;
BA_ "GenSigStartValue" SG_ 1719 KBI_QBit_Aussen_Temp_gef 1;
BA_ "GenSigSendType" SG_ 1719 KBI_QBit_Aussen_Temp_gef 0;
BA_ "Fehlerwert" SG_ 1719 KBI_Aussen_Temp_gef 255;
BA_ "GenSigSwitchedByIgnition" SG_ 1719 KBI_Aussen_Temp_gef 0;
BA_ "GenSigStartValue" SG_ 1719 KBI_Aussen_Temp_gef 254;
BA_ "GenSigSendType" SG_ 1719 KBI_Aussen_Temp_gef 0;
BA_ "GenSigSwitchedByIgnition" SG_ 2549875067 KS_Hybrid_01_Req_Data 0;
BA_ "GenSigSendType" SG_ 2549875067 KS_Hybrid_01_Req_Data 3;
BA_ "GenSigSwitchedByIgnition" SG_ 2550006139 KS_Hybrid_01_Resp_Data 0;
BA_ "GenSigSendType" SG_ 2550006139 KS_Hybrid_01_Resp_Data 3;
BA_ "GenSigSwitchedByIgnition" SG_ 2549875142 KS_Ladegeraet_2_Req_Data 0;
BA_ "GenSigFuncType" SG_ 2549875142 KS_Ladegeraet_2_Req_Data 9;
BA_ "GenSigSendType" SG_ 2549875142 KS_Ladegeraet_2_Req_Data 3;
BA_ "GenSigSwitchedByIgnition" SG_ 2550006214 KS_Ladegeraet_2_Resp_Data 0;
BA_ "GenSigFuncType" SG_ 2550006214 KS_Ladegeraet_2_Resp_Data 9;
BA_ "GenSigSendType" SG_ 2550006214 KS_Ladegeraet_2_Resp_Data 3;
BA_ "GenSigSwitchedByIgnition" SG_ 2549875012 KS_Ladegeraet_Req_Data 0;
BA_ "GenSigFuncType" SG_ 2549875012 KS_Ladegeraet_Req_Data 9;
BA_ "GenSigSendType" SG_ 2549875012 KS_Ladegeraet_Req_Data 3;
BA_ "GenSigSwitchedByIgnition" SG_ 2550006084 KS_Ladegeraet_Resp_Data 0;
BA_ "GenSigFuncType" SG_ 2550006084 KS_Ladegeraet_Resp_Data 9;
BA_ "GenSigSendType" SG_ 2550006084 KS_Ladegeraet_Resp_Data 3;
BA_ "GenSigSwitchedByIgnition" SG_ 2549899473 KS_SSN_CMC_01_Req_Data 0;
BA_ "GenSigFuncType" SG_ 2549899473 KS_SSN_CMC_01_Req_Data 9;
BA_ "GenSigSendType" SG_ 2549899473 KS_SSN_CMC_01_Req_Data 3;
BA_ "GenSigSwitchedByIgnition" SG_ 2550030545 KS_SSN_CMC_01_Resp_Data 0;
BA_ "GenSigFuncType" SG_ 2550030545 KS_SSN_CMC_01_Resp_Data 9;
BA_ "GenSigSendType" SG_ 2550030545 KS_SSN_CMC_01_Resp_Data 3;
BA_ "GenSigSwitchedByIgnition" SG_ 2549899474 KS_SSN_CMC_02_Req_Data 0;
BA_ "GenSigFuncType" SG_ 2549899474 KS_SSN_CMC_02_Req_Data 9;
BA_ "GenSigSendType" SG_ 2549899474 KS_SSN_CMC_02_Req_Data 3;
BA_ "GenSigSwitchedByIgnition" SG_ 2550030546 KS_SSN_CMC_02_Resp_Data 0;
BA_ "GenSigFuncType" SG_ 2550030546 KS_SSN_CMC_02_Resp_Data 9;
BA_ "GenSigSendType" SG_ 2550030546 KS_SSN_CMC_02_Resp_Data 3;
BA_ "GenSigSwitchedByIgnition" SG_ 2549899475 KS_SSN_CMC_03_Req_Data 0;
BA_ "GenSigFuncType" SG_ 2549899475 KS_SSN_CMC_03_Req_Data 9;
BA_ "GenSigSendType" SG_ 2549899475 KS_SSN_CMC_03_Req_Data 3;
BA_ "GenSigSwitchedByIgnition" SG_ 2550030547 KS_SSN_CMC_03_Resp_Data 0;
BA_ "GenSigFuncType" SG_ 2550030547 KS_SSN_CMC_03_Resp_Data 9;
BA_ "GenSigSendType" SG_ 2550030547 KS_SSN_CMC_03_Resp_Data 3;
BA_ "GenSigSwitchedByIgnition" SG_ 2549899476 KS_SSN_CMC_04_Req_Data 0;
BA_ "GenSigFuncType" SG_ 2549899476 KS_SSN_CMC_04_Req_Data 9;
BA_ "GenSigSendType" SG_ 2549899476 KS_SSN_CMC_04_Req_Data 3;
BA_ "GenSigSwitchedByIgnition" SG_ 2550030548 KS_SSN_CMC_04_Resp_Data 0;
BA_ "GenSigFuncType" SG_ 2550030548 KS_SSN_CMC_04_Resp_Data 9;
BA_ "GenSigSendType" SG_ 2550030548 KS_SSN_CMC_04_Resp_Data 3;
BA_ "GenSigSwitchedByIgnition" SG_ 2549899477 KS_SSN_CMC_05_Req_Data 0;
BA_ "GenSigFuncType" SG_ 2549899477 KS_SSN_CMC_05_Req_Data 9;
BA_ "GenSigSendType" SG_ 2549899477 KS_SSN_CMC_05_Req_Data 3;
BA_ "GenSigSwitchedByIgnition" SG_ 2550030549 KS_SSN_CMC_05_Resp_Data 0;
BA_ "GenSigFuncType" SG_ 2550030549 KS_SSN_CMC_05_Resp_Data 9;
BA_ "GenSigSendType" SG_ 2550030549 KS_SSN_CMC_05_Resp_Data 3;
BA_ "GenSigSwitchedByIgnition" SG_ 2549899478 KS_SSN_CMC_06_Req_Data 0;
BA_ "GenSigFuncType" SG_ 2549899478 KS_SSN_CMC_06_Req_Data 9;
BA_ "GenSigSendType" SG_ 2549899478 KS_SSN_CMC_06_Req_Data 3;
BA_ "GenSigSwitchedByIgnition" SG_ 2550030550 KS_SSN_CMC_06_Resp_Data 0;
BA_ "GenSigFuncType" SG_ 2550030550 KS_SSN_CMC_06_Resp_Data 9;
BA_ "GenSigSendType" SG_ 2550030550 KS_SSN_CMC_06_Resp_Data 3;
BA_ "GenSigSwitchedByIgnition" SG_ 2549899479 KS_SSN_CMC_07_Req_Data 0;
BA_ "GenSigFuncType" SG_ 2549899479 KS_SSN_CMC_07_Req_Data 9;
BA_ "GenSigSendType" SG_ 2549899479 KS_SSN_CMC_07_Req_Data 3;
BA_ "GenSigSwitchedByIgnition" SG_ 2550030551 KS_SSN_CMC_07_Resp_Data 0;
BA_ "GenSigFuncType" SG_ 2550030551 KS_SSN_CMC_07_Resp_Data 9;
BA_ "GenSigSendType" SG_ 2550030551 KS_SSN_CMC_07_Resp_Data 3;
BA_ "GenSigSwitchedByIgnition" SG_ 2549899480 KS_SSN_CMC_08_Req_Data 0;
BA_ "GenSigFuncType" SG_ 2549899480 KS_SSN_CMC_08_Req_Data 9;
BA_ "GenSigSendType" SG_ 2549899480 KS_SSN_CMC_08_Req_Data 3;
BA_ "GenSigSwitchedByIgnition" SG_ 2550030552 KS_SSN_CMC_08_Resp_Data 0;
BA_ "GenSigFuncType" SG_ 2550030552 KS_SSN_CMC_08_Resp_Data 9;
BA_ "GenSigSendType" SG_ 2550030552 KS_SSN_CMC_08_Resp_Data 3;
BA_ "GenSigSwitchedByIgnition" SG_ 2549899481 KS_SSN_CMC_09_Req_Data 0;
BA_ "GenSigFuncType" SG_ 2549899481 KS_SSN_CMC_09_Req_Data 9;
BA_ "GenSigSendType" SG_ 2549899481 KS_SSN_CMC_09_Req_Data 3;
BA_ "GenSigSwitchedByIgnition" SG_ 2550030553 KS_SSN_CMC_09_Resp_Data 0;
BA_ "GenSigFuncType" SG_ 2550030553 KS_SSN_CMC_09_Resp_Data 9;
BA_ "GenSigSendType" SG_ 2550030553 KS_SSN_CMC_09_Resp_Data 3;
BA_ "GenSigSwitchedByIgnition" SG_ 2549899482 KS_SSN_CMC_10_Req_Data 0;
BA_ "GenSigFuncType" SG_ 2549899482 KS_SSN_CMC_10_Req_Data 9;
BA_ "GenSigSendType" SG_ 2549899482 KS_SSN_CMC_10_Req_Data 3;
BA_ "GenSigSwitchedByIgnition" SG_ 2550030554 KS_SSN_CMC_10_Resp_Data 0;
BA_ "GenSigFuncType" SG_ 2550030554 KS_SSN_CMC_10_Resp_Data 9;
BA_ "GenSigSendType" SG_ 2550030554 KS_SSN_CMC_10_Resp_Data 3;
BA_ "GenSigSwitchedByIgnition" SG_ 2549899483 KS_SSN_CMC_11_Req_Data 0;
BA_ "GenSigFuncType" SG_ 2549899483 KS_SSN_CMC_11_Req_Data 9;
BA_ "GenSigSendType" SG_ 2549899483 KS_SSN_CMC_11_Req_Data 3;
BA_ "GenSigSwitchedByIgnition" SG_ 2550030555 KS_SSN_CMC_11_Resp_Data 0;
BA_ "GenSigFuncType" SG_ 2550030555 KS_SSN_CMC_11_Resp_Data 9;
BA_ "GenSigSendType" SG_ 2550030555 KS_SSN_CMC_11_Resp_Data 3;
BA_ "GenSigSwitchedByIgnition" SG_ 2549899484 KS_SSN_CMC_12_Req_Data 0;
BA_ "GenSigFuncType" SG_ 2549899484 KS_SSN_CMC_12_Req_Data 9;
BA_ "GenSigSendType" SG_ 2549899484 KS_SSN_CMC_12_Req_Data 3;
BA_ "GenSigSwitchedByIgnition" SG_ 2550030556 KS_SSN_CMC_12_Resp_Data 0;
BA_ "GenSigFuncType" SG_ 2550030556 KS_SSN_CMC_12_Resp_Data 9;
BA_ "GenSigSendType" SG_ 2550030556 KS_SSN_CMC_12_Resp_Data 3;
BA_ "GenSigSwitchedByIgnition" SG_ 2549899505 KS_SSN_CMC_13_Req_Data 0;
BA_ "GenSigFuncType" SG_ 2549899505 KS_SSN_CMC_13_Req_Data 9;
BA_ "GenSigSendType" SG_ 2549899505 KS_SSN_CMC_13_Req_Data 3;
BA_ "GenSigSwitchedByIgnition" SG_ 2550030577 KS_SSN_CMC_13_Resp_Data 0;
BA_ "GenSigFuncType" SG_ 2550030577 KS_SSN_CMC_13_Resp_Data 9;
BA_ "GenSigSendType" SG_ 2550030577 KS_SSN_CMC_13_Resp_Data 3;
BA_ "GenSigSwitchedByIgnition" SG_ 2549899506 KS_SSN_CMC_14_Req_Data 0;
BA_ "GenSigFuncType" SG_ 2549899506 KS_SSN_CMC_14_Req_Data 9;
BA_ "GenSigSendType" SG_ 2549899506 KS_SSN_CMC_14_Req_Data 3;
BA_ "GenSigSwitchedByIgnition" SG_ 2550030578 KS_SSN_CMC_14_Resp_Data 0;
BA_ "GenSigFuncType" SG_ 2550030578 KS_SSN_CMC_14_Resp_Data 9;
BA_ "GenSigSendType" SG_ 2550030578 KS_SSN_CMC_14_Resp_Data 3;
BA_ "GenSigSwitchedByIgnition" SG_ 2549899507 KS_SSN_CMC_15_Req_Data 0;
BA_ "GenSigFuncType" SG_ 2549899507 KS_SSN_CMC_15_Req_Data 9;
BA_ "GenSigSendType" SG_ 2549899507 KS_SSN_CMC_15_Req_Data 3;
BA_ "GenSigSwitchedByIgnition" SG_ 2550030579 KS_SSN_CMC_15_Resp_Data 0;
BA_ "GenSigFuncType" SG_ 2550030579 KS_SSN_CMC_15_Resp_Data 9;
BA_ "GenSigSendType" SG_ 2550030579 KS_SSN_CMC_15_Resp_Data 3;
BA_ "GenSigSwitchedByIgnition" SG_ 2463978640 LAD2_01_CRC 0;
BA_ "GenSigFuncType" SG_ 2463978640 LAD2_01_CRC 2;
BA_ "GenSigSendType" SG_ 2463978640 LAD2_01_CRC 0;
BA_ "GenSigSwitchedByIgnition" SG_ 2463978640 LAD2_01_BZ 0;
BA_ "GenSigFuncType" SG_ 2463978640 LAD2_01_BZ 1;
BA_ "GenSigSendType" SG_ 2463978640 LAD2_01_BZ 0;
BA_ "Fehlerwert" SG_ 2463978640 LAD2_IstModus 5;
BA_ "GenSigSwitchedByIgnition" SG_ 2463978640 LAD2_IstModus 0;
BA_ "GenSigStartValue" SG_ 2463978640 LAD2_IstModus 7;
BA_ "GenSigSendType" SG_ 2463978640 LAD2_IstModus 0;
BA_ "GenSigSwitchedByIgnition" SG_ 2463978640 LAD2_Abregelung_Temperatur 0;
BA_ "GenSigSendType" SG_ 2463978640 LAD2_Abregelung_Temperatur 0;
BA_ "Fehlerwert" SG_ 2463978640 LAD2_Temperatur 255;
BA_ "GenSigSwitchedByIgnition" SG_ 2463978640 LAD2_Temperatur 0;
BA_ "GenSigStartValue" SG_ 2463978640 LAD2_Temperatur 254;
BA_ "GenSigSendType" SG_ 2463978640 LAD2_Temperatur 0;
BA_ "Fehlerwert" SG_ 2463978640 LAD2_IstSpannung_HV 1023;
BA_ "GenSigSwitchedByIgnition" SG_ 2463978640 LAD2_IstSpannung_HV 0;
BA_ "GenSigStartValue" SG_ 2463978640 LAD2_IstSpannung_HV 1022;
BA_ "GenSigSendType" SG_ 2463978640 LAD2_IstSpannung_HV 0;
BA_ "GenSigSwitchedByIgnition" SG_ 2463978640 LAD2_Fehlerstatus 0;
BA_ "GenSigStartValue" SG_ 2463978640 LAD2_Fehlerstatus 7;
BA_ "GenSigSendType" SG_ 2463978640 LAD2_Fehlerstatus 0;
BA_ "GenSigSwitchedByIgnition" SG_ 2463978640 LAD2_Status_Spgfreiheit 0;
BA_ "GenSigSendType" SG_ 2463978640 LAD2_Status_Spgfreiheit 0;
BA_ "Fehlerwert" SG_ 2463978640 LAD2_Status_Phasenumschaltung1 1;
BA_ "GenSigSwitchedByIgnition" SG_ 2463978640 LAD2_Status_Phasenumschaltung1 0;
BA_ "GenSigSendType" SG_ 2463978640 LAD2_Status_Phasenumschaltung1 0;
BA_ "Fehlerwert" SG_ 2463978640 LAD2_Status_Phasenumschaltung2 1;
BA_ "GenSigSwitchedByIgnition" SG_ 2463978640 LAD2_Status_Phasenumschaltung2 0;
BA_ "GenSigSendType" SG_ 2463978640 LAD2_Status_Phasenumschaltung2 0;
BA_ "Fehlerwert" SG_ 2463978640 LAD2_Status_Pfad1 1;
BA_ "GenSigSwitchedByIgnition" SG_ 2463978640 LAD2_Status_Pfad1 0;
BA_ "GenSigSendType" SG_ 2463978640 LAD2_Status_Pfad1 0;
BA_ "Fehlerwert" SG_ 2463978640 LAD2_Status_Pfad2 1;
BA_ "GenSigSwitchedByIgnition" SG_ 2463978640 LAD2_Status_Pfad2 0;
BA_ "GenSigSendType" SG_ 2463978640 LAD2_Status_Pfad2 0;
BA_ "Fehlerwert" SG_ 2463978640 LAD2_Status_Pfad3 1;
BA_ "GenSigSwitchedByIgnition" SG_ 2463978640 LAD2_Status_Pfad3 0;
BA_ "GenSigSendType" SG_ 2463978640 LAD2_Status_Pfad3 0;
BA_ "Fehlerwert" SG_ 2463978644 LAD2_AC_Istspannung_L1 511;
BA_ "GenSigSwitchedByIgnition" SG_ 2463978644 LAD2_AC_Istspannung_L1 0;
BA_ "GenSigStartValue" SG_ 2463978644 LAD2_AC_Istspannung_L1 510;
BA_ "GenSigSendType" SG_ 2463978644 LAD2_AC_Istspannung_L1 0;
BA_ "Fehlerwert" SG_ 2463978644 LAD2_AC_Istspannung_L2 511;
BA_ "GenSigSwitchedByIgnition" SG_ 2463978644 LAD2_AC_Istspannung_L2 0;
BA_ "GenSigStartValue" SG_ 2463978644 LAD2_AC_Istspannung_L2 510;
BA_ "GenSigSendType" SG_ 2463978644 LAD2_AC_Istspannung_L2 0;
BA_ "Fehlerwert" SG_ 2463978644 LAD2_AC_Istspannung_L3 511;
BA_ "GenSigSwitchedByIgnition" SG_ 2463978644 LAD2_AC_Istspannung_L3 0;
BA_ "GenSigStartValue" SG_ 2463978644 LAD2_AC_Istspannung_L3 510;
BA_ "GenSigSendType" SG_ 2463978644 LAD2_AC_Istspannung_L3 0;
BA_ "Fehlerwert" SG_ 2463978644 LAD2_IstStrom_HV_Pfad1 255;
BA_ "GenSigSwitchedByIgnition" SG_ 2463978644 LAD2_IstStrom_HV_Pfad1 0;
BA_ "GenSigStartValue" SG_ 2463978644 LAD2_IstStrom_HV_Pfad1 254;
BA_ "GenSigSendType" SG_ 2463978644 LAD2_IstStrom_HV_Pfad1 0;
BA_ "Fehlerwert" SG_ 2463978644 LAD2_IstStrom_HV_Pfad2 255;
BA_ "GenSigSwitchedByIgnition" SG_ 2463978644 LAD2_IstStrom_HV_Pfad2 0;
BA_ "GenSigStartValue" SG_ 2463978644 LAD2_IstStrom_HV_Pfad2 254;
BA_ "GenSigSendType" SG_ 2463978644 LAD2_IstStrom_HV_Pfad2 0;
BA_ "Fehlerwert" SG_ 2463978644 LAD2_IstStrom_HV_Pfad3 255;
BA_ "GenSigSwitchedByIgnition" SG_ 2463978644 LAD2_IstStrom_HV_Pfad3 0;
BA_ "GenSigStartValue" SG_ 2463978644 LAD2_IstStrom_HV_Pfad3 254;
BA_ "GenSigSendType" SG_ 2463978644 LAD2_IstStrom_HV_Pfad3 0;
BA_ "Fehlerwert" SG_ 2463978645 LAD2_AC_IstStrom_L1 1023;
BA_ "GenSigSwitchedByIgnition" SG_ 2463978645 LAD2_AC_IstStrom_L1 0;
BA_ "GenSigStartValue" SG_ 2463978645 LAD2_AC_IstStrom_L1 1022;
BA_ "GenSigSendType" SG_ 2463978645 LAD2_AC_IstStrom_L1 0;
BA_ "Fehlerwert" SG_ 2463978645 LAD2_AC_IstStrom_L2 1023;
BA_ "GenSigSwitchedByIgnition" SG_ 2463978645 LAD2_AC_IstStrom_L2 0;
BA_ "GenSigStartValue" SG_ 2463978645 LAD2_AC_IstStrom_L2 1022;
BA_ "GenSigSendType" SG_ 2463978645 LAD2_AC_IstStrom_L2 0;
BA_ "Fehlerwert" SG_ 2463978645 LAD2_AC_IstStrom_L3 1023;
BA_ "GenSigSwitchedByIgnition" SG_ 2463978645 LAD2_AC_IstStrom_L3 0;
BA_ "GenSigStartValue" SG_ 2463978645 LAD2_AC_IstStrom_L3 1022;
BA_ "GenSigSendType" SG_ 2463978645 LAD2_AC_IstStrom_L3 0;
BA_ "GenSigSwitchedByIgnition" SG_ 2589283493 LAD2_CALID_CVN_MUX 0;
BA_ "GenSigSendType" SG_ 2589283493 LAD2_CALID_CVN_MUX 0;
BA_ "GenSigSwitchedByIgnition" SG_ 2589283493 LAD2_CVN_VLD 0;
BA_ "GenSigSendType" SG_ 2589283493 LAD2_CVN_VLD 0;
BA_ "GenSigSwitchedByIgnition" SG_ 2589283493 LAD2_CALID_Index_01 0;
BA_ "GenSigStartValue" SG_ 2589283493 LAD2_CALID_Index_01 48;
BA_ "GenSigSwitchedByIgnition" SG_ 2589283493 LAD2_CALID_Index_05 0;
BA_ "GenSigStartValue" SG_ 2589283493 LAD2_CALID_Index_05 48;
BA_ "GenSigSwitchedByIgnition" SG_ 2589283493 LAD2_CALID_Index_09 0;
BA_ "GenSigStartValue" SG_ 2589283493 LAD2_CALID_Index_09 48;
BA_ "GenSigSwitchedByIgnition" SG_ 2589283493 LAD2_CALID_Index_13 0;
BA_ "GenSigStartValue" SG_ 2589283493 LAD2_CALID_Index_13 48;
BA_ "GenSigSwitchedByIgnition" SG_ 2589283493 LAD2_CALID_Index_02 0;
BA_ "GenSigStartValue" SG_ 2589283493 LAD2_CALID_Index_02 48;
BA_ "GenSigSwitchedByIgnition" SG_ 2589283493 LAD2_CALID_Index_06 0;
BA_ "GenSigStartValue" SG_ 2589283493 LAD2_CALID_Index_06 48;
BA_ "GenSigSwitchedByIgnition" SG_ 2589283493 LAD2_CALID_Index_10 0;
BA_ "GenSigStartValue" SG_ 2589283493 LAD2_CALID_Index_10 48;
BA_ "GenSigSwitchedByIgnition" SG_ 2589283493 LAD2_CALID_Index_14 0;
BA_ "GenSigStartValue" SG_ 2589283493 LAD2_CALID_Index_14 48;
BA_ "GenSigSwitchedByIgnition" SG_ 2589283493 LAD2_CALID_Index_03 0;
BA_ "GenSigStartValue" SG_ 2589283493 LAD2_CALID_Index_03 48;
BA_ "GenSigSwitchedByIgnition" SG_ 2589283493 LAD2_CALID_Index_07 0;
BA_ "GenSigStartValue" SG_ 2589283493 LAD2_CALID_Index_07 48;
BA_ "GenSigSwitchedByIgnition" SG_ 2589283493 LAD2_CALID_Index_11 0;
BA_ "GenSigStartValue" SG_ 2589283493 LAD2_CALID_Index_11 48;
BA_ "GenSigSwitchedByIgnition" SG_ 2589283493 LAD2_CALID_Index_15 0;
BA_ "GenSigStartValue" SG_ 2589283493 LAD2_CALID_Index_15 48;
BA_ "GenSigSwitchedByIgnition" SG_ 2589283493 LAD2_CALID_Index_04 0;
BA_ "GenSigStartValue" SG_ 2589283493 LAD2_CALID_Index_04 48;
BA_ "GenSigSwitchedByIgnition" SG_ 2589283493 LAD2_CALID_Index_08 0;
BA_ "GenSigStartValue" SG_ 2589283493 LAD2_CALID_Index_08 48;
BA_ "GenSigSwitchedByIgnition" SG_ 2589283493 LAD2_CALID_Index_12 0;
BA_ "GenSigStartValue" SG_ 2589283493 LAD2_CALID_Index_12 48;
BA_ "GenSigSwitchedByIgnition" SG_ 2589283493 LAD2_CALID_Index_16 0;
BA_ "GenSigStartValue" SG_ 2589283493 LAD2_CALID_Index_16 48;
BA_ "GenSigSwitchedByIgnition" SG_ 2589283493 LAD2_CVN_Byte_1 0;
BA_ "GenSigSwitchedByIgnition" SG_ 2589283493 LAD2_CVN_Byte_2 0;
BA_ "GenSigSwitchedByIgnition" SG_ 2589283493 LAD2_CVN_Byte_3 0;
BA_ "GenSigSwitchedByIgnition" SG_ 2589283493 LAD2_CVN_Byte_4 0;
BA_ "GenSigSwitchedByIgnition" SG_ 2589283392 LAD2_KomponentenFehler_01 0;
BA_ "GenSigStartValue" SG_ 2589283392 LAD2_KomponentenFehler_01 2;
BA_ "GenSigSendType" SG_ 2589283392 LAD2_KomponentenFehler_01 0;
BA_ "GenSigSwitchedByIgnition" SG_ 2589283392 LAD2_KomponentenFehler_02 0;
BA_ "GenSigStartValue" SG_ 2589283392 LAD2_KomponentenFehler_02 2;
BA_ "GenSigSendType" SG_ 2589283392 LAD2_KomponentenFehler_02 0;
BA_ "GenSigSwitchedByIgnition" SG_ 2589283392 LAD2_KomponentenFehler_03 0;
BA_ "GenSigStartValue" SG_ 2589283392 LAD2_KomponentenFehler_03 2;
BA_ "GenSigSendType" SG_ 2589283392 LAD2_KomponentenFehler_03 0;
BA_ "GenSigSwitchedByIgnition" SG_ 2589283392 LAD2_KomponentenFehler_04 0;
BA_ "GenSigStartValue" SG_ 2589283392 LAD2_KomponentenFehler_04 2;
BA_ "GenSigSendType" SG_ 2589283392 LAD2_KomponentenFehler_04 0;
BA_ "GenSigSwitchedByIgnition" SG_ 2589283392 LAD2_KomponentenFehler_05 0;
BA_ "GenSigStartValue" SG_ 2589283392 LAD2_KomponentenFehler_05 2;
BA_ "GenSigSendType" SG_ 2589283392 LAD2_KomponentenFehler_05 0;
BA_ "GenSigSwitchedByIgnition" SG_ 2589283392 LAD2_KomponentenFehler_06 0;
BA_ "GenSigStartValue" SG_ 2589283392 LAD2_KomponentenFehler_06 2;
BA_ "GenSigSendType" SG_ 2589283392 LAD2_KomponentenFehler_06 0;
BA_ "GenSigSwitchedByIgnition" SG_ 2589283392 LAD2_KomponentenFehler_07 0;
BA_ "GenSigStartValue" SG_ 2589283392 LAD2_KomponentenFehler_07 2;
BA_ "GenSigSendType" SG_ 2589283392 LAD2_KomponentenFehler_07 0;
BA_ "GenSigSwitchedByIgnition" SG_ 2589283392 LAD2_KomponentenFehler_08 0;
BA_ "GenSigStartValue" SG_ 2589283392 LAD2_KomponentenFehler_08 2;
BA_ "GenSigSendType" SG_ 2589283392 LAD2_KomponentenFehler_08 0;
BA_ "GenSigSwitchedByIgnition" SG_ 2589283392 LAD2_KomponentenFehler_09 0;
BA_ "GenSigStartValue" SG_ 2589283392 LAD2_KomponentenFehler_09 2;
BA_ "GenSigSendType" SG_ 2589283392 LAD2_KomponentenFehler_09 0;
BA_ "GenSigSwitchedByIgnition" SG_ 2589283392 LAD2_KomponentenFehler_10 0;
BA_ "GenSigStartValue" SG_ 2589283392 LAD2_KomponentenFehler_10 2;
BA_ "GenSigSendType" SG_ 2589283392 LAD2_KomponentenFehler_10 0;
BA_ "GenSigSwitchedByIgnition" SG_ 2589283392 LAD2_KomponentenFehler_11 0;
BA_ "GenSigStartValue" SG_ 2589283392 LAD2_KomponentenFehler_11 2;
BA_ "GenSigSendType" SG_ 2589283392 LAD2_KomponentenFehler_11 0;
BA_ "GenSigSwitchedByIgnition" SG_ 2589283392 LAD2_KomponentenFehler_12 0;
BA_ "GenSigStartValue" SG_ 2589283392 LAD2_KomponentenFehler_12 2;
BA_ "GenSigSendType" SG_ 2589283392 LAD2_KomponentenFehler_12 0;
BA_ "GenSigSwitchedByIgnition" SG_ 2589283392 LAD2_KomponentenFehler_13 0;
BA_ "GenSigStartValue" SG_ 2589283392 LAD2_KomponentenFehler_13 2;
BA_ "GenSigSendType" SG_ 2589283392 LAD2_KomponentenFehler_13 0;
BA_ "GenSigSwitchedByIgnition" SG_ 2589283392 LAD2_KomponentenFehler_14 0;
BA_ "GenSigStartValue" SG_ 2589283392 LAD2_KomponentenFehler_14 2;
BA_ "GenSigSendType" SG_ 2589283392 LAD2_KomponentenFehler_14 0;
BA_ "GenSigSwitchedByIgnition" SG_ 2589283392 LAD2_KomponentenFehler_15 0;
BA_ "GenSigStartValue" SG_ 2589283392 LAD2_KomponentenFehler_15 2;
BA_ "GenSigSendType" SG_ 2589283392 LAD2_KomponentenFehler_15 0;
BA_ "GenSigSwitchedByIgnition" SG_ 2589283392 LAD2_KomponentenFehler_16 0;
BA_ "GenSigStartValue" SG_ 2589283392 LAD2_KomponentenFehler_16 2;
BA_ "GenSigSendType" SG_ 2589283392 LAD2_KomponentenFehler_16 0;
BA_ "GenSigSwitchedByIgnition" SG_ 2589283392 LAD2_KomponentenFehler_17 0;
BA_ "GenSigStartValue" SG_ 2589283392 LAD2_KomponentenFehler_17 2;
BA_ "GenSigSendType" SG_ 2589283392 LAD2_KomponentenFehler_17 0;
BA_ "GenSigSwitchedByIgnition" SG_ 2589283392 LAD2_KomponentenFehler_18 0;
BA_ "GenSigStartValue" SG_ 2589283392 LAD2_KomponentenFehler_18 2;
BA_ "GenSigSendType" SG_ 2589283392 LAD2_KomponentenFehler_18 0;
BA_ "GenSigSwitchedByIgnition" SG_ 2589283392 LAD2_KomponentenFehler_19 0;
BA_ "GenSigStartValue" SG_ 2589283392 LAD2_KomponentenFehler_19 2;
BA_ "GenSigSendType" SG_ 2589283392 LAD2_KomponentenFehler_19 0;
BA_ "GenSigSwitchedByIgnition" SG_ 2589283392 LAD2_KomponentenFehler_20 0;
BA_ "GenSigStartValue" SG_ 2589283392 LAD2_KomponentenFehler_20 2;
BA_ "GenSigSendType" SG_ 2589283392 LAD2_KomponentenFehler_20 0;
BA_ "GenSigSwitchedByIgnition" SG_ 2589283688 LAD2_Version 0;
BA_ "GenSigSendType" SG_ 2589283688 LAD2_Version 0;
BA_ "GenSigSwitchedByIgnition" SG_ 2589283688 LAD2_Version_MUX 0;
BA_ "GenSigSendType" SG_ 2589283688 LAD2_Version_MUX 0;
BA_ "GenSigSwitchedByIgnition" SG_ 2589283688 LAD2_Version_Index_01 0;
BA_ "GenSigStartValue" SG_ 2589283688 LAD2_Version_Index_01 31;
BA_ "GenSigSwitchedByIgnition" SG_ 2589283688 LAD2_Version_Index_02 0;
BA_ "GenSigStartValue" SG_ 2589283688 LAD2_Version_Index_02 31;
BA_ "GenSigSwitchedByIgnition" SG_ 2589283688 LAD2_Version_Index_03 0;
BA_ "GenSigStartValue" SG_ 2589283688 LAD2_Version_Index_03 31;
BA_ "GenSigSwitchedByIgnition" SG_ 2589283688 LAD2_Version_Index_04 0;
BA_ "GenSigStartValue" SG_ 2589283688 LAD2_Version_Index_04 31;
BA_ "GenSigSwitchedByIgnition" SG_ 1380 LAD_01_CRC 0;
BA_ "GenSigFuncType" SG_ 1380 LAD_01_CRC 2;
BA_ "GenSigSendType" SG_ 1380 LAD_01_CRC 0;
BA_ "GenSigSwitchedByIgnition" SG_ 1380 LAD_01_BZ 0;
BA_ "GenSigFuncType" SG_ 1380 LAD_01_BZ 1;
BA_ "GenSigSendType" SG_ 1380 LAD_01_BZ 0;
BA_ "Fehlerwert" SG_ 1380 LAD_IstModus 5;
BA_ "GenSigSwitchedByIgnition" SG_ 1380 LAD_IstModus 0;
BA_ "GenSigStartValue" SG_ 1380 LAD_IstModus 7;
BA_ "GenSigSendType" SG_ 1380 LAD_IstModus 5;
BA_ "Fehlerwert" SG_ 1380 LAD_AC_Istspannung 511;
BA_ "GenSigStartValue" SG_ 1380 LAD_AC_Istspannung 510;
BA_ "GenSigSendType" SG_ 1380 LAD_AC_Istspannung 0;
BA_ "Fehlerwert" SG_ 1380 LAD_IstSpannung_HV 1023;
BA_ "GenSigStartValue" SG_ 1380 LAD_IstSpannung_HV 1022;
BA_ "GenSigSendType" SG_ 1380 LAD_IstSpannung_HV 0;
BA_ "Fehlerwert" SG_ 1380 LAD_IstStrom_HV 1023;
BA_ "GenSigSwitchedByIgnition" SG_ 1380 LAD_IstStrom_HV 0;
BA_ "GenSigStartValue" SG_ 1380 LAD_IstStrom_HV 1022;
BA_ "GenSigSendType" SG_ 1380 LAD_IstStrom_HV 0;
BA_ "GenSigSwitchedByIgnition" SG_ 1380 LAD_Status_Spgfreiheit 0;
BA_ "GenSigSendType" SG_ 1380 LAD_Status_Spgfreiheit 4;
BA_ "GenSigActiveRepetitions" SG_ 1380 LAD_Status_Spgfreiheit 5;
BA_ "Fehlerwert" SG_ 1380 LAD_Temperatur 255;
BA_ "GenSigSwitchedByIgnition" SG_ 1380 LAD_Temperatur 0;
BA_ "GenSigStartValue" SG_ 1380 LAD_Temperatur 254;
BA_ "GenSigSendType" SG_ 1380 LAD_Temperatur 0;
BA_ "Fehlerwert" SG_ 1380 LAD_Verlustleistung 255;
BA_ "GenSigSwitchedByIgnition" SG_ 1380 LAD_Verlustleistung 0;
BA_ "GenSigStartValue" SG_ 1380 LAD_Verlustleistung 254;
BA_ "GenSigSendType" SG_ 1380 LAD_Verlustleistung 0;
BA_ "GenSigSwitchedByIgnition" SG_ 1662 LAD_02_CRC 0;
BA_ "GenSigFuncType" SG_ 1662 LAD_02_CRC 2;
BA_ "GenSigSendType" SG_ 1662 LAD_02_CRC 0;
BA_ "GenSigSwitchedByIgnition" SG_ 1662 LAD_02_BZ 0;
BA_ "GenSigFuncType" SG_ 1662 LAD_02_BZ 1;
BA_ "GenSigSendType" SG_ 1662 LAD_02_BZ 0;
BA_ "GenSigSwitchedByIgnition" SG_ 1662 LAD_Abregelung_Temperatur 0;
BA_ "GenSigSendType" SG_ 1662 LAD_Abregelung_Temperatur 0;
BA_ "GenSigSendType" SG_ 1662 LAD_Abregelung_IU_Ein_Aus 0;
BA_ "GenSigSendType" SG_ 1662 LAD_Abregelung_BuchseTemp 0;
BA_ "Fehlerwert" SG_ 1662 LAD_MaxLadLeistung_HV 511;
BA_ "GenSigSwitchedByIgnition" SG_ 1662 LAD_MaxLadLeistung_HV 0;
BA_ "GenSigStartValue" SG_ 1662 LAD_MaxLadLeistung_HV 510;
BA_ "GenSigSendType" SG_ 1662 LAD_MaxLadLeistung_HV 0;
BA_ "Fehlerwert" SG_ 1662 LAD_PRX_Stromlimit 7;
BA_ "GenSigStartValue" SG_ 1662 LAD_PRX_Stromlimit 6;
BA_ "GenSigSendType" SG_ 1662 LAD_PRX_Stromlimit 0;
BA_ "GenSigSendType" SG_ 1662 LAD_CP_Erkennung 3;
BA_ "GenSigSendType" SG_ 1662 LAD_Stecker_Verriegelt 0;
BA_ "GenSigSendType" SG_ 1662 LAD_Kuehlbedarf 0;
BA_ "GenSigSendType" SG_ 1662 LAD_MaxLadLeistung_HV_Offset 0;
BA_ "GenSigSendType" SG_ 1662 LAD_Warnzustand 0;
BA_ "GenSigSendType" SG_ 1662 LAD_Fehlerzustand 0;
BA_ "Fehlerwert" SG_ 2463978642 LAD_SollStrom_HV_Pfad1 255;
BA_ "GenSigSwitchedByIgnition" SG_ 2463978642 LAD_SollStrom_HV_Pfad1 0;
BA_ "GenSigStartValue" SG_ 2463978642 LAD_SollStrom_HV_Pfad1 254;
BA_ "GenSigSendType" SG_ 2463978642 LAD_SollStrom_HV_Pfad1 0;
BA_ "Fehlerwert" SG_ 2463978642 LAD_SollStrom_HV_Pfad2 255;
BA_ "GenSigSwitchedByIgnition" SG_ 2463978642 LAD_SollStrom_HV_Pfad2 0;
BA_ "GenSigStartValue" SG_ 2463978642 LAD_SollStrom_HV_Pfad2 254;
BA_ "GenSigSendType" SG_ 2463978642 LAD_SollStrom_HV_Pfad2 0;
BA_ "Fehlerwert" SG_ 2463978642 LAD_SollStrom_HV_Pfad3 255;
BA_ "GenSigSwitchedByIgnition" SG_ 2463978642 LAD_SollStrom_HV_Pfad3 0;
BA_ "GenSigStartValue" SG_ 2463978642 LAD_SollStrom_HV_Pfad3 254;
BA_ "GenSigSendType" SG_ 2463978642 LAD_SollStrom_HV_Pfad3 0;
BA_ "GenSigSwitchedByIgnition" SG_ 2463978643 LAD_05_CRC 0;
BA_ "GenSigFuncType" SG_ 2463978643 LAD_05_CRC 2;
BA_ "GenSigSendType" SG_ 2463978643 LAD_05_CRC 0;
BA_ "GenSigSwitchedByIgnition" SG_ 2463978643 LAD_05_BZ 0;
BA_ "GenSigFuncType" SG_ 2463978643 LAD_05_BZ 1;
BA_ "GenSigSendType" SG_ 2463978643 LAD_05_BZ 0;
BA_ "Fehlerwert" SG_ 2463978643 LAD_AC_MaxStrom_L1 1023;
BA_ "GenSigSwitchedByIgnition" SG_ 2463978643 LAD_AC_MaxStrom_L1 0;
BA_ "GenSigStartValue" SG_ 2463978643 LAD_AC_MaxStrom_L1 1022;
BA_ "GenSigSendType" SG_ 2463978643 LAD_AC_MaxStrom_L1 0;
BA_ "Fehlerwert" SG_ 2463978643 LAD_AC_MaxStrom_L2 1023;
BA_ "GenSigSwitchedByIgnition" SG_ 2463978643 LAD_AC_MaxStrom_L2 0;
BA_ "GenSigStartValue" SG_ 2463978643 LAD_AC_MaxStrom_L2 1022;
BA_ "GenSigSendType" SG_ 2463978643 LAD_AC_MaxStrom_L2 0;
BA_ "Fehlerwert" SG_ 2463978643 LAD_AC_MaxStrom_L3 1023;
BA_ "GenSigSwitchedByIgnition" SG_ 2463978643 LAD_AC_MaxStrom_L3 0;
BA_ "GenSigStartValue" SG_ 2463978643 LAD_AC_MaxStrom_L3 1022;
BA_ "GenSigSendType" SG_ 2463978643 LAD_AC_MaxStrom_L3 0;
BA_ "GenSigSwitchedByIgnition" SG_ 2463978643 LAD_Freigabe_LAD2 0;
BA_ "GenSigSendType" SG_ 2463978643 LAD_Freigabe_LAD2 0;
BA_ "Fehlerwert" SG_ 2463978643 LAD_Max_LadeSpannung_LAD2 1023;
BA_ "GenSigSwitchedByIgnition" SG_ 2463978643 LAD_Max_LadeSpannung_LAD2 0;
BA_ "GenSigStartValue" SG_ 2463978643 LAD_Max_LadeSpannung_LAD2 1022;
BA_ "GenSigSendType" SG_ 2463978643 LAD_Max_LadeSpannung_LAD2 0;
BA_ "Fehlerwert" SG_ 2589283663 LAD_PlanAntw_Verlustleistung 4095;
BA_ "GenSigSwitchedByIgnition" SG_ 2589283663 LAD_PlanAntw_Verlustleistung 0;
BA_ "GenSigStartValue" SG_ 2589283663 LAD_PlanAntw_Verlustleistung 4094;
BA_ "GenSigSendType" SG_ 2589283663 LAD_PlanAntw_Verlustleistung 0;
BA_ "Fehlerwert" SG_ 2589283663 LAD_PlanAntw_Zaehler 15;
BA_ "GenSigSwitchedByIgnition" SG_ 2589283663 LAD_PlanAntw_Zaehler 0;
BA_ "GenSigStartValue" SG_ 2589283663 LAD_PlanAntw_Zaehler 14;
BA_ "GenSigSendType" SG_ 2589283663 LAD_PlanAntw_Zaehler 3;
BA_ "GenSigSwitchedByIgnition" SG_ 2589283415 LAD_CALID_CVN_MUX 0;
BA_ "GenSigSendType" SG_ 2589283415 LAD_CALID_CVN_MUX 0;
BA_ "GenSigSwitchedByIgnition" SG_ 2589283415 LAD_CVN_VLD 0;
BA_ "GenSigSendType" SG_ 2589283415 LAD_CVN_VLD 0;
BA_ "GenSigSwitchedByIgnition" SG_ 2589283415 LAD_CALID_Index_01 0;
BA_ "GenSigStartValue" SG_ 2589283415 LAD_CALID_Index_01 48;
BA_ "GenSigSwitchedByIgnition" SG_ 2589283415 LAD_CALID_Index_05 0;
BA_ "GenSigStartValue" SG_ 2589283415 LAD_CALID_Index_05 48;
BA_ "GenSigSwitchedByIgnition" SG_ 2589283415 LAD_CALID_Index_09 0;
BA_ "GenSigStartValue" SG_ 2589283415 LAD_CALID_Index_09 48;
BA_ "GenSigSwitchedByIgnition" SG_ 2589283415 LAD_CALID_Index_13 0;
BA_ "GenSigStartValue" SG_ 2589283415 LAD_CALID_Index_13 48;
BA_ "GenSigSwitchedByIgnition" SG_ 2589283415 LAD_CALID_Index_02 0;
BA_ "GenSigStartValue" SG_ 2589283415 LAD_CALID_Index_02 48;
BA_ "GenSigSwitchedByIgnition" SG_ 2589283415 LAD_CALID_Index_06 0;
BA_ "GenSigStartValue" SG_ 2589283415 LAD_CALID_Index_06 48;
BA_ "GenSigSwitchedByIgnition" SG_ 2589283415 LAD_CALID_Index_10 0;
BA_ "GenSigStartValue" SG_ 2589283415 LAD_CALID_Index_10 48;
BA_ "GenSigSwitchedByIgnition" SG_ 2589283415 LAD_CALID_Index_14 0;
BA_ "GenSigStartValue" SG_ 2589283415 LAD_CALID_Index_14 48;
BA_ "GenSigSwitchedByIgnition" SG_ 2589283415 LAD_CALID_Index_03 0;
BA_ "GenSigStartValue" SG_ 2589283415 LAD_CALID_Index_03 48;
BA_ "GenSigSwitchedByIgnition" SG_ 2589283415 LAD_CALID_Index_07 0;
BA_ "GenSigStartValue" SG_ 2589283415 LAD_CALID_Index_07 48;
BA_ "GenSigSwitchedByIgnition" SG_ 2589283415 LAD_CALID_Index_11 0;
BA_ "GenSigStartValue" SG_ 2589283415 LAD_CALID_Index_11 48;
BA_ "GenSigSwitchedByIgnition" SG_ 2589283415 LAD_CALID_Index_15 0;
BA_ "GenSigStartValue" SG_ 2589283415 LAD_CALID_Index_15 48;
BA_ "GenSigSwitchedByIgnition" SG_ 2589283415 LAD_CALID_Index_04 0;
BA_ "GenSigStartValue" SG_ 2589283415 LAD_CALID_Index_04 48;
BA_ "GenSigSwitchedByIgnition" SG_ 2589283415 LAD_CALID_Index_08 0;
BA_ "GenSigStartValue" SG_ 2589283415 LAD_CALID_Index_08 48;
BA_ "GenSigSwitchedByIgnition" SG_ 2589283415 LAD_CALID_Index_12 0;
BA_ "GenSigStartValue" SG_ 2589283415 LAD_CALID_Index_12 48;
BA_ "GenSigSwitchedByIgnition" SG_ 2589283415 LAD_CALID_Index_16 0;
BA_ "GenSigStartValue" SG_ 2589283415 LAD_CALID_Index_16 48;
BA_ "GenSigSwitchedByIgnition" SG_ 2589283415 LAD_CVN_Byte_1 0;
BA_ "GenSigSwitchedByIgnition" SG_ 2589283415 LAD_CVN_Byte_2 0;
BA_ "GenSigSwitchedByIgnition" SG_ 2589283415 LAD_CVN_Byte_3 0;
BA_ "GenSigSwitchedByIgnition" SG_ 2589283415 LAD_CVN_Byte_4 0;
BA_ "GenSigSwitchedByIgnition" SG_ 2589283472 LAD_KomponentenFehler_01 0;
BA_ "GenSigStartValue" SG_ 2589283472 LAD_KomponentenFehler_01 2;
BA_ "GenSigSendType" SG_ 2589283472 LAD_KomponentenFehler_01 0;
BA_ "GenSigSwitchedByIgnition" SG_ 2589283472 LAD_KomponentenFehler_02 0;
BA_ "GenSigStartValue" SG_ 2589283472 LAD_KomponentenFehler_02 2;
BA_ "GenSigSendType" SG_ 2589283472 LAD_KomponentenFehler_02 0;
BA_ "GenSigSwitchedByIgnition" SG_ 2589283472 LAD_KomponentenFehler_03 0;
BA_ "GenSigStartValue" SG_ 2589283472 LAD_KomponentenFehler_03 2;
BA_ "GenSigSendType" SG_ 2589283472 LAD_KomponentenFehler_03 0;
BA_ "GenSigSwitchedByIgnition" SG_ 2589283472 LAD_KomponentenFehler_04 0;
BA_ "GenSigStartValue" SG_ 2589283472 LAD_KomponentenFehler_04 2;
BA_ "GenSigSendType" SG_ 2589283472 LAD_KomponentenFehler_04 0;
BA_ "GenSigSwitchedByIgnition" SG_ 2589283472 LAD_KomponentenFehler_05 0;
BA_ "GenSigStartValue" SG_ 2589283472 LAD_KomponentenFehler_05 2;
BA_ "GenSigSendType" SG_ 2589283472 LAD_KomponentenFehler_05 0;
BA_ "GenSigSwitchedByIgnition" SG_ 2589283472 LAD_KomponentenFehler_06 0;
BA_ "GenSigStartValue" SG_ 2589283472 LAD_KomponentenFehler_06 2;
BA_ "GenSigSendType" SG_ 2589283472 LAD_KomponentenFehler_06 0;
BA_ "GenSigSwitchedByIgnition" SG_ 2589283472 LAD_KomponentenFehler_07 0;
BA_ "GenSigStartValue" SG_ 2589283472 LAD_KomponentenFehler_07 2;
BA_ "GenSigSendType" SG_ 2589283472 LAD_KomponentenFehler_07 0;
BA_ "GenSigSwitchedByIgnition" SG_ 2589283472 LAD_KomponentenFehler_08 0;
BA_ "GenSigStartValue" SG_ 2589283472 LAD_KomponentenFehler_08 2;
BA_ "GenSigSendType" SG_ 2589283472 LAD_KomponentenFehler_08 0;
BA_ "GenSigSwitchedByIgnition" SG_ 2589283472 LAD_KomponentenFehler_09 0;
BA_ "GenSigStartValue" SG_ 2589283472 LAD_KomponentenFehler_09 2;
BA_ "GenSigSendType" SG_ 2589283472 LAD_KomponentenFehler_09 0;
BA_ "GenSigSwitchedByIgnition" SG_ 2589283472 LAD_KomponentenFehler_10 0;
BA_ "GenSigStartValue" SG_ 2589283472 LAD_KomponentenFehler_10 2;
BA_ "GenSigSendType" SG_ 2589283472 LAD_KomponentenFehler_10 0;
BA_ "GenSigSwitchedByIgnition" SG_ 2589283472 LAD_KomponentenFehler_11 0;
BA_ "GenSigStartValue" SG_ 2589283472 LAD_KomponentenFehler_11 2;
BA_ "GenSigSendType" SG_ 2589283472 LAD_KomponentenFehler_11 0;
BA_ "GenSigSwitchedByIgnition" SG_ 2589283472 LAD_KomponentenFehler_12 0;
BA_ "GenSigStartValue" SG_ 2589283472 LAD_KomponentenFehler_12 2;
BA_ "GenSigSendType" SG_ 2589283472 LAD_KomponentenFehler_12 0;
BA_ "GenSigSwitchedByIgnition" SG_ 2589283472 LAD_KomponentenFehler_13 0;
BA_ "GenSigStartValue" SG_ 2589283472 LAD_KomponentenFehler_13 2;
BA_ "GenSigSendType" SG_ 2589283472 LAD_KomponentenFehler_13 0;
BA_ "GenSigSwitchedByIgnition" SG_ 2589283472 LAD_KomponentenFehler_14 0;
BA_ "GenSigStartValue" SG_ 2589283472 LAD_KomponentenFehler_14 2;
BA_ "GenSigSendType" SG_ 2589283472 LAD_KomponentenFehler_14 0;
BA_ "GenSigSwitchedByIgnition" SG_ 2589283472 LAD_KomponentenFehler_15 0;
BA_ "GenSigStartValue" SG_ 2589283472 LAD_KomponentenFehler_15 2;
BA_ "GenSigSendType" SG_ 2589283472 LAD_KomponentenFehler_15 0;
BA_ "GenSigSwitchedByIgnition" SG_ 2589283472 LAD_KomponentenFehler_16 0;
BA_ "GenSigStartValue" SG_ 2589283472 LAD_KomponentenFehler_16 2;
BA_ "GenSigSendType" SG_ 2589283472 LAD_KomponentenFehler_16 0;
BA_ "GenSigSwitchedByIgnition" SG_ 2589283472 LAD_KomponentenFehler_17 0;
BA_ "GenSigStartValue" SG_ 2589283472 LAD_KomponentenFehler_17 2;
BA_ "GenSigSendType" SG_ 2589283472 LAD_KomponentenFehler_17 0;
BA_ "GenSigSwitchedByIgnition" SG_ 2589283472 LAD_KomponentenFehler_18 0;
BA_ "GenSigStartValue" SG_ 2589283472 LAD_KomponentenFehler_18 2;
BA_ "GenSigSendType" SG_ 2589283472 LAD_KomponentenFehler_18 0;
BA_ "GenSigSwitchedByIgnition" SG_ 2589283472 LAD_KomponentenFehler_19 0;
BA_ "GenSigStartValue" SG_ 2589283472 LAD_KomponentenFehler_19 2;
BA_ "GenSigSendType" SG_ 2589283472 LAD_KomponentenFehler_19 0;
BA_ "GenSigSwitchedByIgnition" SG_ 2589283472 LAD_KomponentenFehler_20 0;
BA_ "GenSigStartValue" SG_ 2589283472 LAD_KomponentenFehler_20 2;
BA_ "GenSigSendType" SG_ 2589283472 LAD_KomponentenFehler_20 0;
BA_ "GenSigSwitchedByIgnition" SG_ 2589283472 LAD_KomponentenFehler_21 0;
BA_ "GenSigStartValue" SG_ 2589283472 LAD_KomponentenFehler_21 2;
BA_ "GenSigSendType" SG_ 2589283472 LAD_KomponentenFehler_21 0;
BA_ "GenSigSwitchedByIgnition" SG_ 2589283472 LAD_KomponentenFehler_22 0;
BA_ "GenSigStartValue" SG_ 2589283472 LAD_KomponentenFehler_22 2;
BA_ "GenSigSendType" SG_ 2589283472 LAD_KomponentenFehler_22 0;
BA_ "GenSigSwitchedByIgnition" SG_ 2589283472 LAD_KomponentenFehler_23 0;
BA_ "GenSigStartValue" SG_ 2589283472 LAD_KomponentenFehler_23 2;
BA_ "GenSigSendType" SG_ 2589283472 LAD_KomponentenFehler_23 0;
BA_ "GenSigSwitchedByIgnition" SG_ 2589283472 LAD_KomponentenFehler_24 0;
BA_ "GenSigStartValue" SG_ 2589283472 LAD_KomponentenFehler_24 2;
BA_ "GenSigSendType" SG_ 2589283472 LAD_KomponentenFehler_24 0;
BA_ "GenSigSwitchedByIgnition" SG_ 2589283472 LAD_KomponentenFehler_25 0;
BA_ "GenSigStartValue" SG_ 2589283472 LAD_KomponentenFehler_25 2;
BA_ "GenSigSendType" SG_ 2589283472 LAD_KomponentenFehler_25 0;
BA_ "GenSigSwitchedByIgnition" SG_ 2589283472 LAD_KomponentenFehler_26 0;
BA_ "GenSigStartValue" SG_ 2589283472 LAD_KomponentenFehler_26 2;
BA_ "GenSigSendType" SG_ 2589283472 LAD_KomponentenFehler_26 0;
BA_ "GenSigSwitchedByIgnition" SG_ 2589283472 LAD_KomponentenFehler_27 0;
BA_ "GenSigStartValue" SG_ 2589283472 LAD_KomponentenFehler_27 2;
BA_ "GenSigSendType" SG_ 2589283472 LAD_KomponentenFehler_27 0;
BA_ "GenSigSwitchedByIgnition" SG_ 2589283472 LAD_KomponentenFehler_28 0;
BA_ "GenSigStartValue" SG_ 2589283472 LAD_KomponentenFehler_28 2;
BA_ "GenSigSendType" SG_ 2589283472 LAD_KomponentenFehler_28 0;
BA_ "GenSigSwitchedByIgnition" SG_ 2589283472 LAD_KomponentenFehler_29 0;
BA_ "GenSigStartValue" SG_ 2589283472 LAD_KomponentenFehler_29 2;
BA_ "GenSigSendType" SG_ 2589283472 LAD_KomponentenFehler_29 0;
BA_ "GenSigSwitchedByIgnition" SG_ 2589283472 LAD_KomponentenFehler_30 0;
BA_ "GenSigStartValue" SG_ 2589283472 LAD_KomponentenFehler_30 2;
BA_ "GenSigSendType" SG_ 2589283472 LAD_KomponentenFehler_30 0;
BA_ "GenSigSwitchedByIgnition" SG_ 2589283472 LAD_KomponentenFehler_31 0;
BA_ "GenSigStartValue" SG_ 2589283472 LAD_KomponentenFehler_31 2;
BA_ "GenSigSendType" SG_ 2589283472 LAD_KomponentenFehler_31 0;
BA_ "GenSigSwitchedByIgnition" SG_ 2589283472 LAD_KomponentenFehler_32 0;
BA_ "GenSigStartValue" SG_ 2589283472 LAD_KomponentenFehler_32 2;
BA_ "GenSigSendType" SG_ 2589283472 LAD_KomponentenFehler_32 0;
BA_REL_ "GenSigTimeoutTime" BU_SG_REL_ Gateway SG_ 2549088437 FCU_Nachlauftyp 5000;
BA_REL_ "GenSigTimeoutTime" BU_SG_REL_ Gateway SG_ 2549088437 FCU_SNI 5000;
BA_REL_ "GenSigTimeoutTime" BU_SG_REL_ Gateway SG_ 2549088437 KN_FCU_ECUKnockOutTimer 5000;
BA_REL_ "GenSigTimeoutTime" BU_SG_REL_ Gateway SG_ 2549088437 KN_FCU_BusKnockOut 5000;
BA_REL_ "GenSigTimeoutTime" BU_SG_REL_ Gateway SG_ 2549088437 KN_FCU_BusKnockOutTimer 5000;
BA_REL_ "GenSigTimeoutTime" BU_SG_REL_ Gateway SG_ 2549088437 KN_FCU_ECUKnockOut 5000;
BA_REL_ "GenSigTimeoutTime" BU_SG_REL_ Gateway SG_ 2549088437 NM_FCU_Lokalaktiv 5000;
BA_REL_ "GenSigTimeoutTime" BU_SG_REL_ Gateway SG_ 2549088437 NM_FCU_Subsystemaktiv 5000;
BA_REL_ "GenSigTimeoutTime" BU_SG_REL_ Gateway SG_ 2549088437 FCU_KD_Fehler 2500;
BA_REL_ "GenSigTimeoutTime" BU_SG_REL_ Gateway SG_ 2549088379 Hybrid_Nachlauftyp 5000;
BA_REL_ "GenSigTimeoutTime" BU_SG_REL_ Gateway_PAG SG_ 2549088379 Hybrid_Nachlauftyp 5000;
BA_REL_ "GenSigTimeoutTime" BU_SG_REL_ Gateway SG_ 2549088379 Hybrid_01_SNI 5000;
BA_REL_ "GenSigTimeoutTime" BU_SG_REL_ Gateway_PAG SG_ 2549088379 Hybrid_01_SNI 5000;
BA_REL_ "GenSigTimeoutTime" BU_SG_REL_ Gateway SG_ 2549088379 KN_BMS_BusKnockOutTimer 5000;
BA_REL_ "GenSigTimeoutTime" BU_SG_REL_ Gateway_PAG SG_ 2549088379 KN_BMS_BusKnockOutTimer 5000;
BA_REL_ "GenSigTimeoutTime" BU_SG_REL_ Gateway SG_ 2549088379 Hybrid_01_Lokalaktiv 5000;
BA_REL_ "GenSigTimeoutTime" BU_SG_REL_ Gateway_PAG SG_ 2549088379 Hybrid_01_Lokalaktiv 5000;
BA_REL_ "GenSigTimeoutTime" BU_SG_REL_ Gateway SG_ 2549088379 Hybrid_01_Subsystemaktiv 5000;
BA_REL_ "GenSigTimeoutTime" BU_SG_REL_ Gateway_PAG SG_ 2549088379 Hybrid_01_Subsystemaktiv 5000;
BA_REL_ "GenSigTimeoutTime" BU_SG_REL_ Gateway SG_ 2549088379 BMS_HYB_KD_Fehler 2500;
BA_REL_ "GenSigTimeoutTime" BU_SG_REL_ Gateway_PAG SG_ 2549088379 BMS_HYB_KD_Fehler 2500;
BA_REL_ "GenSigTimeoutTime" BU_SG_REL_ Gateway SG_ 2549088324 LG_Nachlauftyp 5000;
BA_REL_ "GenSigTimeoutTime" BU_SG_REL_ Gateway_PAG SG_ 2549088324 LG_Nachlauftyp 5000;
BA_REL_ "GenSigTimeoutTime" BU_SG_REL_ Gateway SG_ 2549088324 LG_SNI 5000;
BA_REL_ "GenSigTimeoutTime" BU_SG_REL_ Gateway_PAG SG_ 2549088324 LG_SNI 5000;
BA_REL_ "GenSigTimeoutTime" BU_SG_REL_ Gateway SG_ 2549088324 KN_Ladegeraet_ECUKnockOutTimer 5000;
BA_REL_ "GenSigTimeoutTime" BU_SG_REL_ Gateway SG_ 2549088324 KN_Ladegeraet_BusKnockOut 5000;
BA_REL_ "GenSigTimeoutTime" BU_SG_REL_ Gateway SG_ 2549088324 KN_Ladegeraet_BusKnockOutTimer 5000;
BA_REL_ "GenSigTimeoutTime" BU_SG_REL_ Gateway_PAG SG_ 2549088324 KN_Ladegeraet_BusKnockOutTimer 5000;
BA_REL_ "GenSigTimeoutTime" BU_SG_REL_ Gateway SG_ 2549088324 KN_Ladegeraet_ECUKnockOut 5000;
BA_REL_ "GenSigTimeoutTime" BU_SG_REL_ Gateway SG_ 2549088324 NMH_Ladegeraet_Lokalaktiv 5000;
BA_REL_ "GenSigTimeoutTime" BU_SG_REL_ Gateway_PAG SG_ 2549088324 NMH_Ladegeraet_Lokalaktiv 5000;
BA_REL_ "GenSigTimeoutTime" BU_SG_REL_ Gateway SG_ 2549088324 LG_KD_Fehler 2500;
BA_REL_ "GenSigTimeoutTime" BU_SG_REL_ Gateway_PAG SG_ 2549088324 LG_KD_Fehler 2500;
BA_REL_ "GenSigTimeoutTime" BU_SG_REL_ Gateway SG_ 2549088454 Ladegeraet_2_Nachlauftyp 5000;
BA_REL_ "GenSigTimeoutTime" BU_SG_REL_ Gateway_PAG SG_ 2549088454 Ladegeraet_2_Nachlauftyp 5000;
BA_REL_ "GenSigTimeoutTime" BU_SG_REL_ Gateway SG_ 2549088454 Ladegeraet_2_SNI 5000;
BA_REL_ "GenSigTimeoutTime" BU_SG_REL_ Gateway_PAG SG_ 2549088454 Ladegeraet_2_SNI 5000;
BA_REL_ "GenSigTimeoutTime" BU_SG_REL_ Gateway SG_ 2549088454 KN_Ladegeraet_2_BusKnockOutTimer 5000;
BA_REL_ "GenSigTimeoutTime" BU_SG_REL_ Gateway SG_ 2549088454 NM_Ladegeraet_2_Lokalaktiv 5000;
BA_REL_ "GenSigTimeoutTime" BU_SG_REL_ Gateway_PAG SG_ 2549088454 NM_Ladegeraet_2_Lokalaktiv 5000;
BA_REL_ "GenSigTimeoutTime" BU_SG_REL_ Gateway SG_ 2549088454 Ladegeraet2_KD_Fehler 2500;
BA_REL_ "GenSigTimeoutTime" BU_SG_REL_ Gateway_PAG SG_ 2549088454 Ladegeraet2_KD_Fehler 2500;
BA_REL_ "GenSigTimeoutTime" BU_SG_REL_ Gateway SG_ 2549088257 Sekundaer_01_Nachlauftyp 5000;
BA_REL_ "GenSigTimeoutTime" BU_SG_REL_ Gateway_PAG SG_ 2549088257 Sekundaer_01_Nachlauftyp 5000;
BA_REL_ "GenSigTimeoutTime" BU_SG_REL_ Gateway SG_ 2549088257 Sekundaer_01_SNI 5000;
BA_REL_ "GenSigTimeoutTime" BU_SG_REL_ Gateway_PAG SG_ 2549088257 Sekundaer_01_SNI 5000;
BA_REL_ "GenSigTimeoutTime" BU_SG_REL_ Gateway SG_ 2549088257 KN_Sekundaer_01_ECUKnockOutTimer 5000;
BA_REL_ "GenSigTimeoutTime" BU_SG_REL_ Gateway_PAG SG_ 2549088257 KN_Sekundaer_01_ECUKnockOutTimer 5000;
BA_REL_ "GenSigTimeoutTime" BU_SG_REL_ Gateway SG_ 2549088257 KN_Sekundaer_01_BusKnockOut 5000;
BA_REL_ "GenSigTimeoutTime" BU_SG_REL_ Gateway_PAG SG_ 2549088257 KN_Sekundaer_01_BusKnockOut 5000;
BA_REL_ "GenSigTimeoutTime" BU_SG_REL_ Gateway SG_ 2549088257 KN_Sekundaer_01_BusKnockOutTimer 5000;
BA_REL_ "GenSigTimeoutTime" BU_SG_REL_ Gateway_PAG SG_ 2549088257 KN_Sekundaer_01_BusKnockOutTimer 5000;
BA_REL_ "GenSigTimeoutTime" BU_SG_REL_ Gateway SG_ 2549088257 KN_Sekundaer_01_ECUKnockOut 5000;
BA_REL_ "GenSigTimeoutTime" BU_SG_REL_ Gateway_PAG SG_ 2549088257 KN_Sekundaer_01_ECUKnockOut 5000;
BA_REL_ "GenSigTimeoutTime" BU_SG_REL_ Gateway SG_ 2549088257 NM_Sekundaer_01_Lokalaktiv 5000;
BA_REL_ "GenSigTimeoutTime" BU_SG_REL_ Gateway SG_ 2549088257 Sekundaer_01_KD_Fehler 2500;
BA_REL_ "GenSigTimeoutTime" BU_SG_REL_ Gateway_PAG SG_ 2549088257 Sekundaer_01_KD_Fehler 2500;
BA_REL_ "GenSigTimeoutTime" BU_SG_REL_ Gateway SG_ 2549088259 Sekundaer_03_Nachlauftyp 5000;
BA_REL_ "GenSigTimeoutTime" BU_SG_REL_ Gateway_PAG SG_ 2549088259 Sekundaer_03_Nachlauftyp 5000;
BA_REL_ "GenSigTimeoutTime" BU_SG_REL_ Gateway SG_ 2549088259 Sekundaer_03_SNI 5000;
BA_REL_ "GenSigTimeoutTime" BU_SG_REL_ Gateway_PAG SG_ 2549088259 Sekundaer_03_SNI 5000;
BA_REL_ "GenSigTimeoutTime" BU_SG_REL_ Gateway SG_ 2549088259 KN_Sekundaer_03_ECUKnockOutTimer 5000;
BA_REL_ "GenSigTimeoutTime" BU_SG_REL_ Gateway_PAG SG_ 2549088259 KN_Sekundaer_03_ECUKnockOutTimer 5000;
BA_REL_ "GenSigTimeoutTime" BU_SG_REL_ Gateway SG_ 2549088259 KN_Sekundaer_03_ECUKnockOut 5000;
BA_REL_ "GenSigTimeoutTime" BU_SG_REL_ Gateway_PAG SG_ 2549088259 KN_Sekundaer_03_ECUKnockOut 5000;
BA_REL_ "GenSigTimeoutTime" BU_SG_REL_ Gateway SG_ 2549088259 KN_Sekundaer_03_BusKnockOutTimer 5000;
BA_REL_ "GenSigTimeoutTime" BU_SG_REL_ Gateway_PAG SG_ 2549088259 KN_Sekundaer_03_BusKnockOutTimer 5000;
BA_REL_ "GenSigTimeoutTime" BU_SG_REL_ Gateway SG_ 2549088259 KN_Sekundaer_03_BusKnockOut 5000;
BA_REL_ "GenSigTimeoutTime" BU_SG_REL_ Gateway_PAG SG_ 2549088259 KN_Sekundaer_03_BusKnockOut 5000;
BA_REL_ "GenSigTimeoutTime" BU_SG_REL_ Gateway SG_ 2549088259 Sekundaer_03_Lokalaktiv 5000;
BA_REL_ "GenSigTimeoutTime" BU_SG_REL_ Gateway SG_ 2549088259 Sekundaer_03_KD_Fehler 2500;
BA_REL_ "GenSigTimeoutTime" BU_SG_REL_ Gateway_PAG SG_ 2549088259 Sekundaer_03_KD_Fehler 2500;
BA_REL_ "GenSigTimeoutTime" BU_SG_REL_ Gateway SG_ 2549088329 Sub_Gateway_Nachlauftyp 5000;
BA_REL_ "GenSigTimeoutTime" BU_SG_REL_ Gateway_PAG SG_ 2549088329 Sub_Gateway_Nachlauftyp 5000;
BA_REL_ "GenSigTimeoutTime" BU_SG_REL_ Gateway SG_ 2549088329 Sub_Gateway_SNI 5000;
BA_REL_ "GenSigTimeoutTime" BU_SG_REL_ Gateway_PAG SG_ 2549088329 Sub_Gateway_SNI 5000;
BA_REL_ "GenSigTimeoutTime" BU_SG_REL_ Gateway SG_ 2549088329 NM_Sub_Gateway_Lokalaktiv 5000;
BA_REL_ "GenSigTimeoutTime" BU_SG_REL_ Gateway SG_ 2549088329 NM_Sub_Gateway_Subsystemaktiv 5000;
BA_REL_ "GenSigTimeoutTime" BU_SG_REL_ Gateway SG_ 2549088329 Sub_Gateway_KD_Fehler 2500;
BA_REL_ "GenSigTimeoutTime" BU_SG_REL_ Gateway_PAG SG_ 2549088329 Sub_Gateway_KD_Fehler 2500;
BA_REL_ "GenSigTimeoutTime" BU_SG_REL_ Gateway SG_ 2549088322 TME_Nachlauftyp 5000;
BA_REL_ "GenSigTimeoutTime" BU_SG_REL_ Gateway_PAG SG_ 2549088322 TME_Nachlauftyp 5000;
BA_REL_ "GenSigTimeoutTime" BU_SG_REL_ Gateway SG_ 2549088322 TME_SNI 5000;
BA_REL_ "GenSigTimeoutTime" BU_SG_REL_ Gateway_PAG SG_ 2549088322 TME_SNI 5000;
BA_REL_ "GenSigTimeoutTime" BU_SG_REL_ Gateway SG_ 2549088322 KN_TME_BusKnockOutTimer 5000;
BA_REL_ "GenSigTimeoutTime" BU_SG_REL_ Gateway_PAG SG_ 2549088322 KN_TME_BusKnockOutTimer 5000;
BA_REL_ "GenSigTimeoutTime" BU_SG_REL_ Gateway SG_ 2549088322 NMH_TME_Lokalaktiv 5000;
BA_REL_ "GenSigTimeoutTime" BU_SG_REL_ Gateway_PAG SG_ 2549088322 NMH_TME_Lokalaktiv 5000;
BA_REL_ "GenSigTimeoutTime" BU_SG_REL_ Gateway SG_ 2549088322 NMH_TME_Subsystemaktiv 5000;
BA_REL_ "GenSigTimeoutTime" BU_SG_REL_ Gateway_PAG SG_ 2549088322 NMH_TME_Subsystemaktiv 5000;
BA_REL_ "GenSigTimeoutTime" BU_SG_REL_ Gateway SG_ 2549088322 TME_KD_Fehler 2500;
BA_REL_ "GenSigTimeoutTime" BU_SG_REL_ Gateway_PAG SG_ 2549088322 TME_KD_Fehler 2500;
BA_REL_ "GenSigTimeoutTime" BU_SG_REL_ TME SG_ 779 KBI_Tankwarnung 500;
BA_REL_ "GenSigTimeoutTime" BU_SG_REL_ TME SG_ 1719 KBI_Standzeit_02 5000;
BA_REL_ "GenSigTimeoutTime" BU_SG_REL_ AWC SG_ 1719 KBI_QBit_Aussen_Temp_gef 5000;
BA_REL_ "GenSigTimeoutTime" BU_SG_REL_ AWC SG_ 1719 KBI_Aussen_Temp_gef 5000;
BA_REL_ "GenSigTimeoutTime" BU_SG_REL_ Ladegeraet_Konzern SG_ 1719 KBI_Aussen_Temp_gef 5000;
BA_REL_ "GenSigTimeoutTime" BU_SG_REL_ Gateway SG_ 2463978640 LAD2_01_CRC 1000;
BA_REL_ "GenSigTimeoutTime" BU_SG_REL_ Gateway_PAG SG_ 2463978640 LAD2_01_CRC 1000;
BA_REL_ "GenSigTimeoutTime" BU_SG_REL_ Ladegeraet_Konzern SG_ 2463978640 LAD2_01_CRC 1000;
BA_REL_ "GenSigTimeoutTime" BU_SG_REL_ Gateway SG_ 2463978640 LAD2_01_BZ 1000;
BA_REL_ "GenSigTimeoutTime" BU_SG_REL_ Gateway_PAG SG_ 2463978640 LAD2_01_BZ 1000;
BA_REL_ "GenSigTimeoutTime" BU_SG_REL_ Ladegeraet_Konzern SG_ 2463978640 LAD2_01_BZ 1000;
BA_REL_ "GenSigTimeoutTime" BU_SG_REL_ Ladegeraet_Konzern SG_ 2463978640 LAD2_IstModus 1000;
BA_REL_ "GenSigTimeoutTime" BU_SG_REL_ Ladegeraet_Konzern SG_ 2463978640 LAD2_Abregelung_Temperatur 1000;
BA_REL_ "GenSigTimeoutTime" BU_SG_REL_ Ladegeraet_Konzern SG_ 2463978640 LAD2_Temperatur 1000;
BA_REL_ "GenSigTimeoutTime" BU_SG_REL_ Gateway SG_ 2463978640 LAD2_IstSpannung_HV 1000;
BA_REL_ "GenSigTimeoutTime" BU_SG_REL_ Gateway_PAG SG_ 2463978640 LAD2_IstSpannung_HV 1000;
BA_REL_ "GenSigTimeoutTime" BU_SG_REL_ Ladegeraet_Konzern SG_ 2463978640 LAD2_IstSpannung_HV 1000;
BA_REL_ "GenSigTimeoutTime" BU_SG_REL_ Gateway SG_ 2463978640 LAD2_Fehlerstatus 1000;
BA_REL_ "GenSigTimeoutTime" BU_SG_REL_ Gateway_PAG SG_ 2463978640 LAD2_Fehlerstatus 1000;
BA_REL_ "GenSigTimeoutTime" BU_SG_REL_ Ladegeraet_Konzern SG_ 2463978640 LAD2_Fehlerstatus 1000;
BA_REL_ "GenSigTimeoutTime" BU_SG_REL_ Gateway SG_ 2463978640 LAD2_Status_Spgfreiheit 1000;
BA_REL_ "GenSigTimeoutTime" BU_SG_REL_ Gateway_PAG SG_ 2463978640 LAD2_Status_Spgfreiheit 1000;
BA_REL_ "GenSigTimeoutTime" BU_SG_REL_ Ladegeraet_Konzern SG_ 2463978640 LAD2_Status_Spgfreiheit 1000;
BA_REL_ "GenSigTimeoutTime" BU_SG_REL_ Ladegeraet_Konzern SG_ 2463978640 LAD2_Status_Phasenumschaltung1 1000;
BA_REL_ "GenSigTimeoutTime" BU_SG_REL_ Ladegeraet_Konzern SG_ 2463978640 LAD2_Status_Phasenumschaltung2 1000;
BA_REL_ "GenSigTimeoutTime" BU_SG_REL_ Ladegeraet_Konzern SG_ 2463978640 LAD2_Status_Pfad1 1000;
BA_REL_ "GenSigTimeoutTime" BU_SG_REL_ Ladegeraet_Konzern SG_ 2463978640 LAD2_Status_Pfad2 1000;
BA_REL_ "GenSigTimeoutTime" BU_SG_REL_ Ladegeraet_Konzern SG_ 2463978640 LAD2_Status_Pfad3 1000;
BA_REL_ "GenSigTimeoutTime" BU_SG_REL_ Ladegeraet_Konzern SG_ 2463978644 LAD2_AC_Istspannung_L1 1000;
BA_REL_ "GenSigTimeoutTime" BU_SG_REL_ Ladegeraet_Konzern SG_ 2463978644 LAD2_AC_Istspannung_L2 1000;
BA_REL_ "GenSigTimeoutTime" BU_SG_REL_ Ladegeraet_Konzern SG_ 2463978644 LAD2_AC_Istspannung_L3 1000;
BA_REL_ "GenSigTimeoutTime" BU_SG_REL_ Ladegeraet_Konzern SG_ 2463978644 LAD2_IstStrom_HV_Pfad1 1000;
BA_REL_ "GenSigTimeoutTime" BU_SG_REL_ Ladegeraet_Konzern SG_ 2463978644 LAD2_IstStrom_HV_Pfad2 1000;
BA_REL_ "GenSigTimeoutTime" BU_SG_REL_ Ladegeraet_Konzern SG_ 2463978644 LAD2_IstStrom_HV_Pfad3 1000;
BA_REL_ "GenSigTimeoutTime" BU_SG_REL_ Ladegeraet_Konzern SG_ 2463978645 LAD2_AC_IstStrom_L1 1000;
BA_REL_ "GenSigTimeoutTime" BU_SG_REL_ Ladegeraet_Konzern SG_ 2463978645 LAD2_AC_IstStrom_L2 1000;
BA_REL_ "GenSigTimeoutTime" BU_SG_REL_ Ladegeraet_Konzern SG_ 2463978645 LAD2_AC_IstStrom_L3 1000;
BA_REL_ "GenSigTimeoutTime" BU_SG_REL_ BMC_MLBevo SG_ 2589283493 LAD2_CALID_CVN_MUX 5000;
BA_REL_ "GenSigTimeoutTime" BU_SG_REL_ BMC_MLBevo SG_ 2589283493 LAD2_CVN_VLD 5000;
BA_REL_ "GenSigTimeoutTime" BU_SG_REL_ BMC_MLBevo SG_ 2589283493 LAD2_CALID_Index_01 5000;
BA_REL_ "GenSigTimeoutTime" BU_SG_REL_ BMC_MLBevo SG_ 2589283493 LAD2_CALID_Index_05 5000;
BA_REL_ "GenSigTimeoutTime" BU_SG_REL_ BMC_MLBevo SG_ 2589283493 LAD2_CALID_Index_09 5000;
BA_REL_ "GenSigTimeoutTime" BU_SG_REL_ BMC_MLBevo SG_ 2589283493 LAD2_CALID_Index_13 5000;
BA_REL_ "GenSigTimeoutTime" BU_SG_REL_ BMC_MLBevo SG_ 2589283493 LAD2_CALID_Index_02 5000;
BA_REL_ "GenSigTimeoutTime" BU_SG_REL_ BMC_MLBevo SG_ 2589283493 LAD2_CALID_Index_06 5000;
BA_REL_ "GenSigTimeoutTime" BU_SG_REL_ BMC_MLBevo SG_ 2589283493 LAD2_CALID_Index_10 5000;
BA_REL_ "GenSigTimeoutTime" BU_SG_REL_ BMC_MLBevo SG_ 2589283493 LAD2_CALID_Index_14 5000;
BA_REL_ "GenSigTimeoutTime" BU_SG_REL_ BMC_MLBevo SG_ 2589283493 LAD2_CALID_Index_03 5000;
BA_REL_ "GenSigTimeoutTime" BU_SG_REL_ BMC_MLBevo SG_ 2589283493 LAD2_CALID_Index_07 5000;
BA_REL_ "GenSigTimeoutTime" BU_SG_REL_ BMC_MLBevo SG_ 2589283493 LAD2_CALID_Index_11 5000;
BA_REL_ "GenSigTimeoutTime" BU_SG_REL_ BMC_MLBevo SG_ 2589283493 LAD2_CALID_Index_15 5000;
BA_REL_ "GenSigTimeoutTime" BU_SG_REL_ BMC_MLBevo SG_ 2589283493 LAD2_CALID_Index_04 5000;
BA_REL_ "GenSigTimeoutTime" BU_SG_REL_ BMC_MLBevo SG_ 2589283493 LAD2_CALID_Index_08 5000;
BA_REL_ "GenSigTimeoutTime" BU_SG_REL_ BMC_MLBevo SG_ 2589283493 LAD2_CALID_Index_12 5000;
BA_REL_ "GenSigTimeoutTime" BU_SG_REL_ BMC_MLBevo SG_ 2589283493 LAD2_CALID_Index_16 5000;
BA_REL_ "GenSigTimeoutTime" BU_SG_REL_ BMC_MLBevo SG_ 2589283493 LAD2_CVN_Byte_1 5000;
BA_REL_ "GenSigTimeoutTime" BU_SG_REL_ BMC_MLBevo SG_ 2589283493 LAD2_CVN_Byte_2 5000;
BA_REL_ "GenSigTimeoutTime" BU_SG_REL_ BMC_MLBevo SG_ 2589283493 LAD2_CVN_Byte_3 5000;
BA_REL_ "GenSigTimeoutTime" BU_SG_REL_ BMC_MLBevo SG_ 2589283493 LAD2_CVN_Byte_4 5000;
BA_REL_ "GenSigTimeoutTime" BU_SG_REL_ BMC_MLBevo SG_ 2589283392 LAD2_KomponentenFehler_01 5000;
BA_REL_ "GenSigTimeoutTime" BU_SG_REL_ BMC_MLBevo SG_ 2589283392 LAD2_KomponentenFehler_02 5000;
BA_REL_ "GenSigTimeoutTime" BU_SG_REL_ BMC_MLBevo SG_ 2589283392 LAD2_KomponentenFehler_03 5000;
BA_REL_ "GenSigTimeoutTime" BU_SG_REL_ BMC_MLBevo SG_ 2589283392 LAD2_KomponentenFehler_04 5000;
BA_REL_ "GenSigTimeoutTime" BU_SG_REL_ BMC_MLBevo SG_ 2589283392 LAD2_KomponentenFehler_05 5000;
BA_REL_ "GenSigTimeoutTime" BU_SG_REL_ BMC_MLBevo SG_ 2589283392 LAD2_KomponentenFehler_06 5000;
BA_REL_ "GenSigTimeoutTime" BU_SG_REL_ BMC_MLBevo SG_ 2589283392 LAD2_KomponentenFehler_07 5000;
BA_REL_ "GenSigTimeoutTime" BU_SG_REL_ BMC_MLBevo SG_ 2589283392 LAD2_KomponentenFehler_08 5000;
BA_REL_ "GenSigTimeoutTime" BU_SG_REL_ BMC_MLBevo SG_ 2589283392 LAD2_KomponentenFehler_09 5000;
BA_REL_ "GenSigTimeoutTime" BU_SG_REL_ BMC_MLBevo SG_ 2589283392 LAD2_KomponentenFehler_10 5000;
BA_REL_ "GenSigTimeoutTime" BU_SG_REL_ BMC_MLBevo SG_ 2589283392 LAD2_KomponentenFehler_11 5000;
BA_REL_ "GenSigTimeoutTime" BU_SG_REL_ BMC_MLBevo SG_ 2589283392 LAD2_KomponentenFehler_12 5000;
BA_REL_ "GenSigTimeoutTime" BU_SG_REL_ BMC_MLBevo SG_ 2589283392 LAD2_KomponentenFehler_13 5000;
BA_REL_ "GenSigTimeoutTime" BU_SG_REL_ BMC_MLBevo SG_ 2589283392 LAD2_KomponentenFehler_14 5000;
BA_REL_ "GenSigTimeoutTime" BU_SG_REL_ BMC_MLBevo SG_ 2589283392 LAD2_KomponentenFehler_15 5000;
BA_REL_ "GenSigTimeoutTime" BU_SG_REL_ BMC_MLBevo SG_ 2589283392 LAD2_KomponentenFehler_16 5000;
BA_REL_ "GenSigTimeoutTime" BU_SG_REL_ BMC_MLBevo SG_ 2589283392 LAD2_KomponentenFehler_17 5000;
BA_REL_ "GenSigTimeoutTime" BU_SG_REL_ BMC_MLBevo SG_ 2589283392 LAD2_KomponentenFehler_18 5000;
BA_REL_ "GenSigTimeoutTime" BU_SG_REL_ BMC_MLBevo SG_ 2589283392 LAD2_KomponentenFehler_19 5000;
BA_REL_ "GenSigTimeoutTime" BU_SG_REL_ BMC_MLBevo SG_ 2589283392 LAD2_KomponentenFehler_20 5000;
BA_REL_ "GenSigTimeoutTime" BU_SG_REL_ Ladegeraet_Konzern SG_ 2589283688 LAD2_Version 5000;
BA_REL_ "GenSigTimeoutTime" BU_SG_REL_ Ladegeraet_Konzern SG_ 2589283688 LAD2_Version_MUX 5000;
BA_REL_ "GenSigTimeoutTime" BU_SG_REL_ Ladegeraet_Konzern SG_ 2589283688 LAD2_Version_Index_01 5000;
BA_REL_ "GenSigTimeoutTime" BU_SG_REL_ Ladegeraet_Konzern SG_ 2589283688 LAD2_Version_Index_02 5000;
BA_REL_ "GenSigTimeoutTime" BU_SG_REL_ Ladegeraet_Konzern SG_ 2589283688 LAD2_Version_Index_03 5000;
BA_REL_ "GenSigTimeoutTime" BU_SG_REL_ Ladegeraet_Konzern SG_ 2589283688 LAD2_Version_Index_04 5000;
BA_REL_ "GenSigTimeoutTime" BU_SG_REL_ Gateway SG_ 1380 LAD_01_CRC 5000;
BA_REL_ "GenSigTimeoutTime" BU_SG_REL_ Gateway_PAG SG_ 1380 LAD_01_CRC 5000;
BA_REL_ "GenSigTimeoutTime" BU_SG_REL_ Gateway SG_ 1380 LAD_01_BZ 5000;
BA_REL_ "GenSigTimeoutTime" BU_SG_REL_ Gateway_PAG SG_ 1380 LAD_01_BZ 5000;
BA_REL_ "GenSigTimeoutTime" BU_SG_REL_ Gateway SG_ 1380 LAD_IstModus 5000;
BA_REL_ "GenSigTimeoutTime" BU_SG_REL_ Gateway_PAG SG_ 1380 LAD_IstModus 5000;
BA_REL_ "GenSigTimeoutTime" BU_SG_REL_ Ladegeraet_2 SG_ 1380 LAD_IstModus 5000;
BA_REL_ "GenSigTimeoutTime" BU_SG_REL_ TME SG_ 1380 LAD_IstModus 5000;
BA_REL_ "GenSigTimeoutTime" BU_SG_REL_ Gateway SG_ 1380 LAD_IstStrom_HV 5000;
BA_REL_ "GenSigTimeoutTime" BU_SG_REL_ Gateway_PAG SG_ 1380 LAD_IstStrom_HV 5000;
BA_REL_ "GenSigTimeoutTime" BU_SG_REL_ Gateway SG_ 1380 LAD_Status_Spgfreiheit 5000;
BA_REL_ "GenSigTimeoutTime" BU_SG_REL_ Gateway_PAG SG_ 1380 LAD_Status_Spgfreiheit 5000;
BA_REL_ "GenSigTimeoutTime" BU_SG_REL_ TME SG_ 1380 LAD_Temperatur 5000;
BA_REL_ "GenSigTimeoutTime" BU_SG_REL_ TME SG_ 1380 LAD_Verlustleistung 5000;
BA_REL_ "GenSigTimeoutTime" BU_SG_REL_ Gateway SG_ 1662 LAD_02_CRC 5000;
BA_REL_ "GenSigTimeoutTime" BU_SG_REL_ Gateway_PAG SG_ 1662 LAD_02_CRC 5000;
BA_REL_ "GenSigTimeoutTime" BU_SG_REL_ Gateway SG_ 1662 LAD_02_BZ 5000;
BA_REL_ "GenSigTimeoutTime" BU_SG_REL_ Gateway_PAG SG_ 1662 LAD_02_BZ 5000;
BA_REL_ "GenSigTimeoutTime" BU_SG_REL_ TME SG_ 1662 LAD_Abregelung_Temperatur 5000;
BA_REL_ "GenSigTimeoutTime" BU_SG_REL_ TME SG_ 1662 LAD_MaxLadLeistung_HV 5000;
BA_REL_ "GenSigTimeoutTime" BU_SG_REL_ Ladegeraet_2 SG_ 2463978642 LAD_SollStrom_HV_Pfad1 1000;
BA_REL_ "GenSigTimeoutTime" BU_SG_REL_ Ladegeraet_2 SG_ 2463978642 LAD_SollStrom_HV_Pfad2 1000;
BA_REL_ "GenSigTimeoutTime" BU_SG_REL_ Ladegeraet_2 SG_ 2463978642 LAD_SollStrom_HV_Pfad3 1000;
BA_REL_ "GenSigTimeoutTime" BU_SG_REL_ Ladegeraet_2 SG_ 2463978643 LAD_05_CRC 1000;
BA_REL_ "GenSigTimeoutTime" BU_SG_REL_ Ladegeraet_2 SG_ 2463978643 LAD_05_BZ 1000;
BA_REL_ "GenSigTimeoutTime" BU_SG_REL_ Ladegeraet_2 SG_ 2463978643 LAD_AC_MaxStrom_L1 1000;
BA_REL_ "GenSigTimeoutTime" BU_SG_REL_ Ladegeraet_2 SG_ 2463978643 LAD_AC_MaxStrom_L2 1000;
BA_REL_ "GenSigTimeoutTime" BU_SG_REL_ Ladegeraet_2 SG_ 2463978643 LAD_AC_MaxStrom_L3 1000;
BA_REL_ "GenSigTimeoutTime" BU_SG_REL_ Ladegeraet_2 SG_ 2463978643 LAD_Freigabe_LAD2 1000;
BA_REL_ "GenSigTimeoutTime" BU_SG_REL_ Ladegeraet_2 SG_ 2463978643 LAD_Max_LadeSpannung_LAD2 1000;
BA_REL_ "GenSigTimeoutTime" BU_SG_REL_ TME SG_ 2589283663 LAD_PlanAntw_Verlustleistung 5000;
BA_REL_ "GenSigTimeoutTime" BU_SG_REL_ TME SG_ 2589283663 LAD_PlanAntw_Zaehler 5000;
BA_REL_ "GenSigTimeoutTime" BU_SG_REL_ BMC_MLBevo SG_ 2589283415 LAD_CALID_CVN_MUX 5000;
BA_REL_ "GenSigTimeoutTime" BU_SG_REL_ BMC_MLBevo SG_ 2589283415 LAD_CVN_VLD 5000;
BA_REL_ "GenSigTimeoutTime" BU_SG_REL_ BMC_MLBevo SG_ 2589283415 LAD_CALID_Index_01 5000;
BA_REL_ "GenSigTimeoutTime" BU_SG_REL_ BMC_MLBevo SG_ 2589283415 LAD_CALID_Index_05 5000;
BA_REL_ "GenSigTimeoutTime" BU_SG_REL_ BMC_MLBevo SG_ 2589283415 LAD_CALID_Index_09 5000;
BA_REL_ "GenSigTimeoutTime" BU_SG_REL_ BMC_MLBevo SG_ 2589283415 LAD_CALID_Index_13 5000;
BA_REL_ "GenSigTimeoutTime" BU_SG_REL_ BMC_MLBevo SG_ 2589283415 LAD_CALID_Index_02 5000;
BA_REL_ "GenSigTimeoutTime" BU_SG_REL_ BMC_MLBevo SG_ 2589283415 LAD_CALID_Index_06 5000;
BA_REL_ "GenSigTimeoutTime" BU_SG_REL_ BMC_MLBevo SG_ 2589283415 LAD_CALID_Index_10 5000;
BA_REL_ "GenSigTimeoutTime" BU_SG_REL_ BMC_MLBevo SG_ 2589283415 LAD_CALID_Index_14 5000;
BA_REL_ "GenSigTimeoutTime" BU_SG_REL_ BMC_MLBevo SG_ 2589283415 LAD_CALID_Index_03 5000;
BA_REL_ "GenSigTimeoutTime" BU_SG_REL_ BMC_MLBevo SG_ 2589283415 LAD_CALID_Index_07 5000;
BA_REL_ "GenSigTimeoutTime" BU_SG_REL_ BMC_MLBevo SG_ 2589283415 LAD_CALID_Index_11 5000;
BA_REL_ "GenSigTimeoutTime" BU_SG_REL_ BMC_MLBevo SG_ 2589283415 LAD_CALID_Index_15 5000;
BA_REL_ "GenSigTimeoutTime" BU_SG_REL_ BMC_MLBevo SG_ 2589283415 LAD_CALID_Index_04 5000;
BA_REL_ "GenSigTimeoutTime" BU_SG_REL_ BMC_MLBevo SG_ 2589283415 LAD_CALID_Index_08 5000;
BA_REL_ "GenSigTimeoutTime" BU_SG_REL_ BMC_MLBevo SG_ 2589283415 LAD_CALID_Index_12 5000;
BA_REL_ "GenSigTimeoutTime" BU_SG_REL_ BMC_MLBevo SG_ 2589283415 LAD_CALID_Index_16 5000;
BA_REL_ "GenSigTimeoutTime" BU_SG_REL_ BMC_MLBevo SG_ 2589283415 LAD_CVN_Byte_1 5000;
BA_REL_ "GenSigTimeoutTime" BU_SG_REL_ BMC_MLBevo SG_ 2589283415 LAD_CVN_Byte_2 5000;
BA_REL_ "GenSigTimeoutTime" BU_SG_REL_ BMC_MLBevo SG_ 2589283415 LAD_CVN_Byte_3 5000;
BA_REL_ "GenSigTimeoutTime" BU_SG_REL_ BMC_MLBevo SG_ 2589283415 LAD_CVN_Byte_4 5000;
BA_REL_ "GenSigTimeoutTime" BU_SG_REL_ BMC_MLBevo SG_ 2589283472 LAD_KomponentenFehler_01 5000;
BA_REL_ "GenSigTimeoutTime" BU_SG_REL_ BMC_MLBevo SG_ 2589283472 LAD_KomponentenFehler_02 5000;
BA_REL_ "GenSigTimeoutTime" BU_SG_REL_ BMC_MLBevo SG_ 2589283472 LAD_KomponentenFehler_03 5000;
BA_REL_ "GenSigTimeoutTime" BU_SG_REL_ BMC_MLBevo SG_ 2589283472 LAD_KomponentenFehler_04 5000;
BA_REL_ "GenSigTimeoutTime" BU_SG_REL_ BMC_MLBevo SG_ 2589283472 LAD_KomponentenFehler_05 5000;
BA_REL_ "GenSigTimeoutTime" BU_SG_REL_ BMC_MLBevo SG_ 2589283472 LAD_KomponentenFehler_06 5000;
BA_REL_ "GenSigTimeoutTime" BU_SG_REL_ BMC_MLBevo SG_ 2589283472 LAD_KomponentenFehler_07 5000;
BA_REL_ "GenSigTimeoutTime" BU_SG_REL_ BMC_MLBevo SG_ 2589283472 LAD_KomponentenFehler_08 5000;
BA_REL_ "GenSigTimeoutTime" BU_SG_REL_ BMC_MLBevo SG_ 2589283472 LAD_KomponentenFehler_09 5000;
BA_REL_ "GenSigTimeoutTime" BU_SG_REL_ BMC_MLBevo SG_ 2589283472 LAD_KomponentenFehler_10 5000;
BA_REL_ "GenSigTimeoutTime" BU_SG_REL_ BMC_MLBevo SG_ 2589283472 LAD_KomponentenFehler_11 5000;
BA_REL_ "GenSigTimeoutTime" BU_SG_REL_ BMC_MLBevo SG_ 2589283472 LAD_KomponentenFehler_12 5000;
BA_REL_ "GenSigTimeoutTime" BU_SG_REL_ BMC_MLBevo SG_ 2589283472 LAD_KomponentenFehler_13 5000;
BA_REL_ "GenSigTimeoutTime" BU_SG_REL_ BMC_MLBevo SG_ 2589283472 LAD_KomponentenFehler_14 5000;
BA_REL_ "GenSigTimeoutTime" BU_SG_REL_ BMC_MLBevo SG_ 2589283472 LAD_KomponentenFehler_15 5000;
BA_REL_ "GenSigTimeoutTime" BU_SG_REL_ BMC_MLBevo SG_ 2589283472 LAD_KomponentenFehler_16 5000;
BA_REL_ "GenSigTimeoutTime" BU_SG_REL_ BMC_MLBevo SG_ 2589283472 LAD_KomponentenFehler_17 5000;
BA_REL_ "GenSigTimeoutTime" BU_SG_REL_ BMC_MLBevo SG_ 2589283472 LAD_KomponentenFehler_18 5000;
BA_REL_ "GenSigTimeoutTime" BU_SG_REL_ BMC_MLBevo SG_ 2589283472 LAD_KomponentenFehler_19 5000;
BA_REL_ "GenSigTimeoutTime" BU_SG_REL_ BMC_MLBevo SG_ 2589283472 LAD_KomponentenFehler_20 5000;
BA_REL_ "GenSigTimeoutTime" BU_SG_REL_ BMC_MLBevo SG_ 2589283472 LAD_KomponentenFehler_21 5000;
BA_REL_ "GenSigTimeoutTime" BU_SG_REL_ BMC_MLBevo SG_ 2589283472 LAD_KomponentenFehler_22 5000;
BA_REL_ "GenSigTimeoutTime" BU_SG_REL_ BMC_MLBevo SG_ 2589283472 LAD_KomponentenFehler_23 5000;
BA_REL_ "GenSigTimeoutTime" BU_SG_REL_ BMC_MLBevo SG_ 2589283472 LAD_KomponentenFehler_24 5000;
BA_REL_ "GenSigTimeoutTime" BU_SG_REL_ BMC_MLBevo SG_ 2589283472 LAD_KomponentenFehler_25 5000;
BA_REL_ "GenSigTimeoutTime" BU_SG_REL_ BMC_MLBevo SG_ 2589283472 LAD_KomponentenFehler_26 5000;
BA_REL_ "GenSigTimeoutTime" BU_SG_REL_ BMC_MLBevo SG_ 2589283472 LAD_KomponentenFehler_27 5000;
BA_REL_ "GenSigTimeoutTime" BU_SG_REL_ BMC_MLBevo SG_ 2589283472 LAD_KomponentenFehler_28 5000;
BA_REL_ "GenSigTimeoutTime" BU_SG_REL_ BMC_MLBevo SG_ 2589283472 LAD_KomponentenFehler_29 5000;
BA_REL_ "GenSigTimeoutTime" BU_SG_REL_ BMC_MLBevo SG_ 2589283472 LAD_KomponentenFehler_30 5000;
BA_REL_ "GenSigTimeoutTime" BU_SG_REL_ BMC_MLBevo SG_ 2589283472 LAD_KomponentenFehler_31 5000;
BA_REL_ "GenSigTimeoutTime" BU_SG_REL_ BMC_MLBevo SG_ 2589283472 LAD_KomponentenFehler_32 5000;
VAL_ 2549088437 FCU_KompSchutz 0 "inaktiv" 1 "aktiv" ;
VAL_ 2549088437 FCU_Abschaltstufe 0 "keine_Einschraenkung" 1 "Funktionseinschraenkung" ;
VAL_ 2549088437 FCU_Transport_Mode 0 "keine_Einschraenkung" 1 "Funktionseinschraenkung" ;
VAL_ 2549088437 FCU_Nachlauftyp 0 "Komm_bei_KL15_EIN" 1 "Komm_nach_KL15_AUS" 2 "Komm_bei_KL15_AUS" ;
VAL_ 2549088437 FCU_SNI 181 "FCU" ;
VAL_ 2549088437 KN_FCU_ECUKnockOutTimer 63 "ECUKnockOut_deaktiviert" ;
VAL_ 2549088437 KN_FCU_BusKnockOut 0 "Funktion_nicht_ausgeloest" 1 "Veto_aktiv" 2 "Funktion_ausgeloest" 3 "Funktion_deaktiviert" ;
VAL_ 2549088437 KN_FCU_BusKnockOutTimer 255 "BusKnockOut_deaktiviert" ;
VAL_ 2549088437 NM_FCU_Wakeup 0 "Peripherie_Wakeup__Ursache_nicht_bekannt" 1 "Bus_Wakeup" 2 "KL15_HW" ;
VAL_ 2549088437 KN_FCU_ECUKnockOut 0 "Funktion_nicht_ausgeloest" 1 "Veto_war_aktiv" 2 "Funktion_ausgeloest" 3 "Funktion_deaktiviert" ;
VAL_ 2549088437 KN_FCU_DiagPfad 0 "aktiv" 1 "inaktiv" ;
VAL_ 2549088437 NM_FCU_Lokalaktiv 0 "war_nicht_lokal_aktiv" 1 "war_lokal_aktiv" ;
VAL_ 2549088437 NM_FCU_Subsystemaktiv 0 "war_nicht_lokal_aktiv" 1 "war_lokal_aktiv" ;
VAL_ 2549088437 FCU_KD_Fehler 0 "kein_KD_Fehler" 1 "KD_Fehler" ;
VAL_ 2549088272 Gateway_KompSchutz 0 "inaktiv" 1 "aktiv" ;
VAL_ 2549088272 Gateway_Abschaltstufe 0 "keine_Einschraenkung" 1 "Funktionseinschraenkung" ;
VAL_ 2549088272 Gateway_Transport_Mode 0 "keine_Einschraenkung" 1 "Funktionseinschraenkung" ;
VAL_ 2549088272 Gateway_Nachlauftyp 0 "Komm_bei_KL15_EIN" 1 "Komm_nach_KL15_AUS" 2 "Komm_bei_KL15_AUS" ;
VAL_ 2549088272 Gateway_SNI 16 "Gateway" ;
VAL_ 2549088272 NM_Gateway_Wakeup 0 "Peripherie_Wakeup__Ursache_nicht_bekannt" 1 "Bus_Wakeup" 2 "KL15_HW" 3 "ACAN_Wakeup" 4 "FCAN_Wakeup" 5 "KCAN_Wakeup" 6 "ICAN_Wakeup" 7 "DiagCAN_Wakeup" 8 "ECAN_Wakeup" 9 "Energie_LIN_Wakeup" 10 "Bedien_LIN_Wakeup" 11 "HybridCAN_Wakeup" 12 "Flexray_Wakeup" 13 "MFL_WakeUp" 14 "Ethernet" 15 "DCAN_Wakeup" 16 "K2CAN_Wakeup" 17 "CCAN" 18 "AFSCAN_Wakeup" 32 "FlexRay_Branch1_WakeUp" 33 "FlexRay_Branch2_WakeUp" 34 "FlexRay_Branch3_WakeUp" 35 "FlexRay_Branch4_WakeUp" 36 "FlexRay_Branch5_WakeUp" 37 "FlexRay_Branch6_WakeUp" 38 "FlexRay_Branch7_WakeUp" 39 "FlexRay_Branch8_WakeUp" 40 "FlexRay_Branch9_WakeUp" 41 "FlexRay_Branch10_WakeUp" 42 "FlexRay_Branch11_WakeUp" 43 "FlexRay_Branch12_WakeUp" 44 "FlexRay_Branch13_WakeUp" 45 "FlexRay_Branch14_WakeUp" 46 "FlexRay_Branch15_WakeUp" 47 "FlexRay_Branch16_WakeUp" 128 "Energiemanagement" 129 "Funktionswakeup_OBDC" 130 "Hochvoltenergiemanagement" 131 "CWU_empfangen" 132 "Fuer_Bus_relevanten_FC_empfangen" 133 "OnlineDienst_empfangen" 134 "HV_Aktivieren" 135 "HV_Deaktivieren" 136 "VTS_Suche_DriverCard" 137 "VTS_Hupen_Blinken" 138 "Remote_Vehicle_Status" 139 "Plug_and_Charge" 140 "VTS_Wakeup_Infotainment" 141 "EMHLR" 142 "NFcGW_fordert_OTA_FC_an" 143 "Komponentenschutz" 144 "UserStateServer" 145 "Dimmung" 146 "Kessy" 147 "StandardAussenlicht" 148 "ParkKoordinator" 149 "HVLMDynamicChargingPOI" 150 "HVLMChargingManagementServer" 151 "HVLMExtendedChargingMonitoring" 152 "Zentralverriegelung" 153 "FunctionOnDemand" 154 "IAA" 155 "StandKlimatisierung" 156 "RealTimeMonitor" 157 "Klemmensteuerung" ;
VAL_ 2549088272 NM_Gateway_Lokalaktiv 0 "war_nicht_lokal_aktiv" 1 "war_lokal_aktiv" ;
VAL_ 2549088272 NM_Gateway_Subsystemaktiv 0 "Subsystem_war_nicht_lokalaktiv" 1 "war_lokalaktiv" ;
VAL_ 2549088272 GW_KD_Fehler 0 "kein_KD_Fehler" 1 "KD_Fehler" ;
VAL_ 2549088379 Hybrid_KompSchutz 0 "inaktiv" 1 "aktiv" ;
VAL_ 2549088379 Hybrid_01_Abschaltstufe 0 "keine_Einschraenkung" 1 "Funktionseinschraenkung" ;
VAL_ 2549088379 Hybrid_01_Transport_Mode 0 "keine_Einschraenkung" 1 "Funktionseinschraenkung" ;
VAL_ 2549088379 Hybrid_Nachlauftyp 0 "Komm_bei_KL15_EIN" 1 "Komm_nach_KL15_AUS" 2 "Komm_bei_KL15_AUS" ;
VAL_ 2549088379 Hybrid_01_SNI 123 "Hybrid_01" ;
VAL_ 2549088379 KN_BMS_ECUKnockOutTimer 63 "ECUKnockOut_deaktiviert" ;
VAL_ 2549088379 KN_BMS_BusKnockOut 0 "Funktion_nicht_ausgeloest" 1 "Veto_aktiv" 2 "Funktion_ausgeloest" 3 "Funktion_deaktiviert" ;
VAL_ 2549088379 KN_BMS_BusKnockOutTimer 255 "BusKnockOut_deaktiviert" ;
VAL_ 2549088379 NM_Hybrid_01_Wakeup 0 "Peripherie_Wakeup__Ursache_nicht_bekannt" 1 "Bus_Wakeup" 2 "KL15_HW" ;
VAL_ 2549088379 KN_BMS_ECUKnockOut 0 "Funktion_nicht_ausgeloest" 1 "Veto_war_aktiv" 2 "Funktion_ausgeloest" 3 "Funktion_deaktiviert" ;
VAL_ 2549088379 Hybrid_01_Lokalaktiv 0 "war nicht Lokalaktiv" 1 "war Lokalaktiv" ;
VAL_ 2549088379 Hybrid_01_Subsystemaktiv 0 "Subsystem_war_nicht_lokalaktiv" 1 "war_lokalaktiv" ;
VAL_ 2549088379 BMS_HYB_KD_Fehler 0 "kein_KD_Fehler" 1 "KD_Fehler" ;
VAL_ 2549088324 LG_KompSchutz 0 "inaktiv" 1 "aktiv" ;
VAL_ 2549088324 LG_Abschaltstufe 0 "keine_Einschraenkung" 1 "Funktionseinschraenkung" ;
VAL_ 2549088324 LG_Transport_Mode 0 "keine_Einschraenkung" 1 "Funktionseinschraenkung" ;
VAL_ 2549088324 LG_Nachlauftyp 0 "Komm_bei_KL15_EIN" 1 "Komm_nach_KL15_AUS" 2 "Komm_bei_KL15_AUS" ;
VAL_ 2549088324 LG_SNI 68 "LG" ;
VAL_ 2549088324 KN_Ladegeraet_ECUKnockOutTimer 63 "ECUKnockOut_deaktiviert" ;
VAL_ 2549088324 KN_Ladegeraet_BusKnockOut 0 "Funktion_nicht_ausgeloest" 1 "Veto_aktiv" 2 "Funktion_ausgeloest" 3 "Funktion_deaktiviert" ;
VAL_ 2549088324 KN_Ladegeraet_BusKnockOutTimer 255 "BusKnockOut_deaktiviert" ;
VAL_ 2549088324 NM_Ladegeraet_Wakeup 0 "Peripherie_Wakeup__Ursache_nicht_bekannt" 1 "Bus_Wakeup" 2 "KL15_HW" 4 "AC_Spannung_erkannt" 5 "PRX_Erkennung" 6 "CP_Erkennung" 7 "Taste_1" 8 "Taste_2" 9 "Taste_3" 10 "Chademo_Stecker_stecken" 11 "Chademo_Startknopf_druecken" 12 "Klimatisierung_Funkfernbedienung" 13 "LIN_Wakeup" 14 "GBT_CC1_Wakeup" 15 "GBT_CC2_Wakeup" 16 "CP_Erkennung_0V_auf9V" 17 "CP_Erkennung_9Voder6V_auf0V" 18 "CP_Erkennung_FREQ_AN" 19 "CP_Erkennung_FREQ_AUS" 20 "CP_Erkennung_DELTA_DUTY" 21 "SW_Reset" 22 "KL30_Reset" ;
VAL_ 2549088324 KN_Ladegeraet_ECUKnockOut 0 "Funktion_nicht_ausgeloest" 1 "Veto_war_aktiv" 2 "Funktion_ausgeloest" 3 "Funktion_deaktiviert" ;
VAL_ 2549088324 NMH_Ladegeraet_Lokalaktiv 0 "war_nicht_lokal_aktiv" 1 "war_lokal_aktiv" ;
VAL_ 2549088324 NMH_Ladegeraet_Subsystemaktiv 0 "Subsystem_war_nicht_lokalaktiv" 1 "war_lokalaktiv" ;
VAL_ 2549088324 LG_KD_Fehler 0 "kein_KD_Fehler" 1 "KD_Fehler" ;
VAL_ 2549088454 Ladegeraet_2_KompSchutz 0 "inaktiv" 1 "aktiv" ;
VAL_ 2549088454 Ladegeraet_2_Abschaltstufe 0 "keine_Einschraenkung" 1 "Funktionseinschraenkung" ;
VAL_ 2549088454 Ladegeraet_2_Transport_Mode 0 "keine_Einschraenkung" 1 "Funktionseinschraenkung" ;
VAL_ 2549088454 Ladegeraet_2_Nachlauftyp 0 "Komm_bei_KL15_EIN" 1 "Komm_nach_KL15_AUS" 2 "Komm_bei_KL15_AUS" ;
VAL_ 2549088454 Ladegeraet_2_SNI 198 "Ladegeraet_2" ;
VAL_ 2549088454 KN_Ladegeraet_2_ECUKnockOutTimer 63 "ECUKnockOut_deaktiviert" ;
VAL_ 2549088454 KN_Ladegeraet_2_BusKnockOut 0 "Funktion_nicht_ausgeloest" 1 "Veto_aktiv" 2 "Funktion_ausgeloest" 3 "Funktion_deaktiviert" ;
VAL_ 2549088454 KN_Ladegeraet_2_BusKnockOutTimer 255 "BusKnockOut_deaktiviert" ;
VAL_ 2549088454 NM_Ladegeraet_2_Wakeup 0 "Peripherie_Wakeup__Ursache_nicht_bekannt" 1 "Bus_Wakeup" 2 "KL15_HW" ;
VAL_ 2549088454 KN_Ladegeraet_2_ECUKnockOut 0 "Funktion_nicht_ausgeloest" 1 "Veto_war_aktiv" 2 "Funktion_ausgeloest" 3 "Funktion_deaktiviert" ;
VAL_ 2549088454 NM_Ladegeraet_2_Lokalaktiv 0 "war_nicht_lokal_aktiv" 1 "war_lokal_aktiv" ;
VAL_ 2549088454 Ladegeraet2_KD_Fehler 0 "kein_KD_Fehler" 1 "KD_Fehler" ;
VAL_ 2549088257 Sekundaer_01_KompSchutz 0 "inaktiv" 1 "aktiv" ;
VAL_ 2549088257 Sekundaer_01_Abschaltstufe 0 "keine_Einschraenkung" 1 "Funktionseinschraenkung" ;
VAL_ 2549088257 Sekundaer_01_Transport_Mode 0 "keine_Einschraenkung" 1 "Funktionseinschraenkung" ;
VAL_ 2549088257 Sekundaer_01_Nachlauftyp 0 "Komm_bei_KL15_EIN" 1 "Komm_nach_KL15_AUS" 2 "Komm_bei_KL15_AUS" ;
VAL_ 2549088257 Sekundaer_01_SNI 1 "Sekundaer_01" ;
VAL_ 2549088257 KN_Sekundaer_01_ECUKnockOutTimer 63 "ECUKnockOut_deaktiviert" ;
VAL_ 2549088257 KN_Sekundaer_01_BusKnockOut 0 "Funktion_nicht_ausgeloest" 1 "Veto_aktiv" 2 "Funktion_ausgeloest" 3 "Funktion_deaktiviert" ;
VAL_ 2549088257 KN_Sekundaer_01_BusKnockOutTimer 255 "BusKnockOut_deaktiviert" ;
VAL_ 2549088257 NM_Sekundaer_01_Wakeup 0 "Peripherie_Wakeup__Ursache_nicht_bekannt" 1 "Bus_Wakeup" 2 "KL15_HW" 3 "KL_30__Reset" ;
VAL_ 2549088257 KN_Sekundaer_01_ECUKnockOut 0 "Funktion_nicht_ausgeloest" 1 "Veto_war_aktiv" 2 "Funktion_ausgeloest" 3 "Funktion_deaktiviert" ;
VAL_ 2549088257 NM_Sekundaer_01_Lokalaktiv 0 "war_nicht_lokal_aktiv" 1 "war_lokal_aktiv" ;
VAL_ 2549088257 Sekundaer_01_KD_Fehler 0 "kein_KD_Fehler" 1 "KD_Fehler" ;
VAL_ 2549088259 Sekundaer_03_KompSchutz 0 "inaktiv" 1 "aktiv" ;
VAL_ 2549088259 Sekundaer_03_Abschaltstufe 0 "keine_Einschraenkung" 1 "Funktionseinschraenkung" ;
VAL_ 2549088259 Sekundaer_03_Transport_Mode 0 "keine_Einschraenkung" 1 "Funktionseinschraenkung" ;
VAL_ 2549088259 Sekundaer_03_Nachlauftyp 0 "Komm_bei_KL15_EIN" 1 "Komm_nach_KL15_AUS" 2 "Komm_bei_KL15_AUS" ;
VAL_ 2549088259 Sekundaer_03_SNI 3 "Sekundaer_03" ;
VAL_ 2549088259 KN_Sekundaer_03_ECUKnockOutTimer 63 "ECUKnockOut_deaktiviert" ;
VAL_ 2549088259 KN_Sekundaer_03_ECUKnockOut 0 "Funktion_nicht_ausgeloest" 1 "Veto_war_aktiv" 2 "Funktion_ausgeloest" 3 "Funktion_deaktiviert" ;
VAL_ 2549088259 KN_Sekundaer_03_BusKnockOutTimer 255 "BusKnockOut_deaktiviert" ;
VAL_ 2549088259 Sekundaer_03_LEH_Wakeup 0 "Peripherie_Wakeup__Ursache_nicht_bekannt" 1 "Bus_Wakeup" 2 "KL15_HW" 3 "KL_30__Reset" ;
VAL_ 2549088259 KN_Sekundaer_03_BusKnockOut 0 "Funktion_nicht_ausgeloest" 1 "Veto_aktiv" 2 "Funktion_ausgeloest" 3 "Funktion_deaktiviert" ;
VAL_ 2549088259 Sekundaer_03_Lokalaktiv 0 "war_nicht_lokal_aktiv" 1 "war_lokal_aktiv" ;
VAL_ 2549088259 Sekundaer_03_KD_Fehler 0 "kein_KD_Fehler" 1 "KD_Fehler" ;
VAL_ 2549088329 Sub_Gateway_KompSchutz 0 "inaktiv" 1 "aktiv" ;
VAL_ 2549088329 Sub_Gateway_Abschaltstufe 0 "keine_Einschraenkung" 1 "Funktionseinschraenkung" ;
VAL_ 2549088329 Sub_Gateway_Transport_Mode 0 "keine_Einschraenkung" 1 "Funktionseinschraenkung" ;
VAL_ 2549088329 Sub_Gateway_Nachlauftyp 0 "Komm_bei_KL15_EIN" 1 "Komm_nach_KL15_AUS" 2 "Komm_bei_KL15_AUS" ;
VAL_ 2549088329 Sub_Gateway_SNI 73 "Sub_Gateway" ;
VAL_ 2549088329 Sub_Gateway_BusKnockOutTimer 255 "BusKnockOut_deaktiviert" ;
VAL_ 2549088329 NM_Sub_Gateway_Wakeup 0 "Peripherie_Wakeup__Ursache_nicht_bekannt" 1 "Bus_Wakeup" 2 "KL15_HW" ;
VAL_ 2549088329 NM_Sub_Gateway_Lokalaktiv 0 "war_nicht_lokal_aktiv" 1 "war_lokal_aktiv" ;
VAL_ 2549088329 NM_Sub_Gateway_Subsystemaktiv 0 "Subsystem_war_nicht_lokalaktiv" 1 "war_lokalaktiv" ;
VAL_ 2549088329 Sub_Gateway_KD_Fehler 0 "kein_KD_Fehler" 1 "KD_Fehler" ;
VAL_ 2549088322 TME_KompSchutz 0 "inaktiv" 1 "aktiv" ;
VAL_ 2549088322 TME_Abschaltstufe 0 "keine_Einschraenkung" 1 "Funktionseinschraenkung" ;
VAL_ 2549088322 TME_Transport_Mode 0 "keine_Einschraenkung" 1 "Funktionseinschraenkung" ;
VAL_ 2549088322 TME_Nachlauftyp 0 "Komm_bei_KL15_EIN" 1 "Komm_nach_KL15_AUS" 2 "Komm_bei_KL15_AUS" ;
VAL_ 2549088322 TME_SNI 66 "TME" ;
VAL_ 2549088322 KN_TME_BusKnockOutTimer 255 "BusKnockOut_deaktiviert" ;
VAL_ 2549088322 NM_TME_Wakeup 0 "Peripherie_Wakeup__Ursache_nicht_bekannt" 1 "Bus_Wakeup" 2 "KL15_HW" 3 "KL30_Reset" 4 "Anforderung_HV_Auszeit" ;
VAL_ 2549088322 NMH_TME_Lokalaktiv 0 "war_nicht_lokal_aktiv" 1 "war_lokal_aktiv" ;
VAL_ 2549088322 NMH_TME_Subsystemaktiv 0 "Subsystem_war_nicht_lokalaktiv" 1 "war_lokalaktiv" ;
VAL_ 2549088322 TME_KD_Fehler 0 "kein_KD_Fehler" 1 "KD_Fehler" ;
VAL_ 779 KBI_ABS_Lampe 0 "ABS Lampe aus" 1 "ABS Lampe ein" ;
VAL_ 779 KBI_ESP_Lampe 0 "ESP Lampe aus" 1 "ESP Lampe ein" ;
VAL_ 779 KBI_BKL_Lampe 0 "BKL aus" 1 "BKL ein" ;
VAL_ 779 KBI_Airbag_Lampe 0 "Airbag Lampe aus" 1 "Airbag Lampe ein" ;
VAL_ 779 KBI_SILA_gueltig 0 "ungueltig" 1 "gueltig" ;
VAL_ 779 KBI_Vorglueh_System_Lampe 0 "Lampe aus" 1 "Lampe ein" ;
VAL_ 779 KBI_NV_in_Anzeige 0 "NV_nicht_in_Anzeige" 1 "NV_in_Anzeige" ;
VAL_ 779 KBI_Anzeigestatus_ACC 0 "keine_ACC_Anzeige" 1 "ACC_Anzeige_aktiv" ;
VAL_ 779 KBI_Anzeigestatus_GRA 0 "nicht_vorhanden" 1 "Anzeigemoeglichkeit_vorhanden" 2 "reserviert" 3 "Fehler" ;
VAL_ 779 KBI_Tankwarnung 0 "Lampe aus" 1 "Lampe ein" ;
VAL_ 779 KBI_MFA_v_Einheit_01 0 "kmh" 1 "mph" ;
VAL_ 779 KBI_im_Stellgliedtest 0 "kein Stellgliedtest" 1 "Kombi im Stellgliedtest" ;
VAL_ 779 KBI_Anzeigefehler_LDW 0 "nicht vorhanden bzw. unterstützt" 1 "Anzeige iO" 2 "Anzeigefehler" 3 "nicht definiert" ;
VAL_ 779 KBI_Tankwarnung_ungueltig 0 "KBI_Tankwarnung_gueltig" 1 "KBI_Tankwarnung_ungueltig" ;
VAL_ 779 KBI_Handbremse 0 "nicht_angezogen" 1 "angezogen" ;
VAL_ 779 KBI_PLA_in_Anzeige 0 "PLA_nicht_in_Anzeige" 1 "PLA_in_Anzeige" ;
VAL_ 779 KBI_Anzeigefehler_NV 0 "kein_Anzeigefehler" 1 "Anzeigefehler" ;
VAL_ 779 KBI_Anzeigestatus_LIM 0 "nicht_vorhanden" 1 "Anzeigemoeglichkeit_vorhanden" 2 "reserviert" 3 "Fehler" ;
VAL_ 779 KBI_ARA_in_Anzeige 0 "ARA nicht in Anzeige" 1 "ARA in Anzeige" ;
VAL_ 779 KBI_Taster_Lift 0 "nicht_betaetigt" 1 "betaetigt" ;
VAL_ 779 KBI_Taster_Fahrwerk 0 "nicht_betaetigt" 1 "betaetigt" ;
VAL_ 779 KBI_Einheit_Tacho 0 "km/h" 1 "mph" ;
VAL_ 779 KBI_Konsistenz_ACC 0 "ACC Botschaft konsistent" 1 "ACC Botschaft inkonsistent" ;
VAL_ 779 KBI_Fehler_Anzeige_ACC 0 " iO" 1 "Anzeigefehler ACC" ;
VAL_ 779 KBI_Anzeigefehler_SWA 0 "nicht vorhanden bzw. unterstützt" 1 "Anzeige iO" 2 "Anzeigefehler" 3 "nicht definiert" ;
VAL_ 779 KBI_Systemstatus 0 "KBI_IO" 1 "KBI_System_Failure" ;
VAL_ 1719 KBI_Kilometerstand 1048574 "Init" 1048575 "Fehler" ;
VAL_ 1719 KBI_Standzeit_02 131069 "nicht_verfuegbar" 131070 "Init" 131071 "Fehler" ;
VAL_ 1719 KBI_LVDS_Lock 0 "Init_LVDS_nicht_gelockt" 1 "LVDS_gelockt" ;
VAL_ 1719 KBI_Reserve_Warnung_Sek 0 "Keine_Warnung" 1 "Sekundaere_Reservewarnung" ;
VAL_ 1719 KBI_RDK_Kalibrier_Anf 0 "keine_Kalibrieranforderung" 1 "Kalibrieranforderung" ;
VAL_ 1719 KBI_Inhalt_Tank 126 "Init" 127 "Fehler" ;
VAL_ 1719 KBI_FStatus_Tank 0 "Tankfüllstand i.O." 1 "Tankfüllstand n.i.O" ;
VAL_ 1719 KBI_aktive_Laengsfunktion 0 "Init" 1 "Speedlimiter" 2 "GRA_oder_ACC" 3 "PACCh" 4 "HDC" 5 "p_GRA" 6 "p_Lim" 7 "Umschaltung_GRA_Limiter" ;
VAL_ 1719 KBI_FoD_PopUP_Quittiert 0 "nicht_quittiert" 1 "Meldung_quittiert" ;
VAL_ 1719 KBI_GRA_im_ACC 0 "GRA_im_ACC_nicht_ausgewaehlt" 1 "GRA_im_ACC_ausgewaehlt" ;
VAL_ 1719 KBI_Oelwechsel_durchgefuehrt 0 "Oelwechsel_nicht_durchgefuehrt" 1 "Oelwechsel_durchgefuehrt" ;
VAL_ 1719 KBI_QBit_Aussen_Temp_gef 0 "gueltiger_Wert" 1 "Ersatz_Init_oder_Fehlerwert" ;
VAL_ 1719 KBI_Aussen_Temp_gef 253 "nicht verbaut" 254 "Init" 255 "Fehler" ;
VAL_ 2463978640 LAD2_IstModus 0 "Standby" 1 "AC_Netzladung" 4 "PreCharge_aktiv" 5 "Fehler" 7 "Init" ;
VAL_ 2463978640 LAD2_Abregelung_Temperatur 0 "inaktiv" 1 "aktiv" ;
VAL_ 2463978640 LAD2_Temperatur 254 "Init" 255 "Fehler" ;
VAL_ 2463978640 LAD2_IstSpannung_HV 1022 "Init" 1023 "Fehler" ;
VAL_ 2463978640 LAD2_Fehlerstatus 0 "Komponente_IO" 2 "Eingeschr_KompFkt_AC_Lad_NIO" 3 "Eingeschr_KompFkt_Interlock" 4 "Eingeschr_KompFkt_KS_aktiv" 6 "Keine_Komponentenfunktion" 7 "Init" ;
VAL_ 2463978640 LAD2_Status_Spgfreiheit 0 "Init" 1 "HV_Komponente_spannungsfrei" 2 "HV_Komp_nicht_spannungsfrei" 3 "Fehler_nicht_spannungsfrei" ;
VAL_ 2463978640 LAD2_Status_Phasenumschaltung1 0 "kein_Fehler" 1 "Fehler" ;
VAL_ 2463978640 LAD2_Status_Phasenumschaltung2 0 "kein_Fehler" 1 "Fehler" ;
VAL_ 2463978640 LAD2_Status_Pfad1 0 "kein_Fehler" 1 "Fehler" ;
VAL_ 2463978640 LAD2_Status_Pfad2 0 "kein_Fehler" 1 "Fehler" ;
VAL_ 2463978640 LAD2_Status_Pfad3 0 "kein_Fehler" 1 "Fehler" ;
VAL_ 2463978644 LAD2_AC_Istspannung_L1 510 "Init" 511 "Fehler" ;
VAL_ 2463978644 LAD2_AC_Istspannung_L2 510 "Init" 511 "Fehler" ;
VAL_ 2463978644 LAD2_AC_Istspannung_L3 510 "Init" 511 "Fehler" ;
VAL_ 2463978644 LAD2_IstStrom_HV_Pfad1 254 "Init" 255 "Fehler" ;
VAL_ 2463978644 LAD2_IstStrom_HV_Pfad2 254 "Init" 255 "Fehler" ;
VAL_ 2463978644 LAD2_IstStrom_HV_Pfad3 254 "Init" 255 "Fehler" ;
VAL_ 2463978645 LAD2_AC_IstStrom_L1 1022 "Init" 1023 "Fehler" ;
VAL_ 2463978645 LAD2_AC_IstStrom_L2 1022 "Init" 1023 "Fehler" ;
VAL_ 2463978645 LAD2_AC_IstStrom_L3 1022 "Init" 1023 "Fehler" ;
VAL_ 2589283493 LAD2_CVN_VLD 0 "ungueltig" 1 "gueltig" ;
VAL_ 2589283493 LAD2_CALID_Index_01 48 "Init" ;
VAL_ 2589283493 LAD2_CALID_Index_05 48 "Init" ;
VAL_ 2589283493 LAD2_CALID_Index_09 48 "Init" ;
VAL_ 2589283493 LAD2_CALID_Index_13 48 "Init" ;
VAL_ 2589283493 LAD2_CALID_Index_02 48 "Init" ;
VAL_ 2589283493 LAD2_CALID_Index_06 48 "Init" ;
VAL_ 2589283493 LAD2_CALID_Index_10 48 "Init" ;
VAL_ 2589283493 LAD2_CALID_Index_14 48 "Init" ;
VAL_ 2589283493 LAD2_CALID_Index_03 48 "Init" ;
VAL_ 2589283493 LAD2_CALID_Index_07 48 "Init" ;
VAL_ 2589283493 LAD2_CALID_Index_11 48 "Init" ;
VAL_ 2589283493 LAD2_CALID_Index_15 48 "Init" ;
VAL_ 2589283493 LAD2_CALID_Index_04 48 "Init" ;
VAL_ 2589283493 LAD2_CALID_Index_08 48 "Init" ;
VAL_ 2589283493 LAD2_CALID_Index_12 48 "Init" ;
VAL_ 2589283493 LAD2_CALID_Index_16 48 "Init" ;
VAL_ 2589283493 LAD2_CVN_Byte_1 0 "Init" ;
VAL_ 2589283493 LAD2_CVN_Byte_2 0 "Init" ;
VAL_ 2589283493 LAD2_CVN_Byte_3 0 "Init" ;
VAL_ 2589283493 LAD2_CVN_Byte_4 0 "Init" ;
VAL_ 2589283392 LAD2_KomponentenFehler_01 0 "TestComplete_PASS" 1 "TestComplete_FAIL" 2 "TestNotComplete_PASS" ;
VAL_ 2589283392 LAD2_KomponentenFehler_02 0 "TestComplete_PASS" 1 "TestComplete_FAIL" 2 "TestNotComplete_PASS" ;
VAL_ 2589283392 LAD2_KomponentenFehler_03 0 "TestComplete_PASS" 1 "TestComplete_FAIL" 2 "TestNotComplete_PASS" ;
VAL_ 2589283392 LAD2_KomponentenFehler_04 0 "TestComplete_PASS" 1 "TestComplete_FAIL" 2 "TestNotComplete_PASS" ;
VAL_ 2589283392 LAD2_KomponentenFehler_05 0 "TestComplete_PASS" 1 "TestComplete_FAIL" 2 "TestNotComplete_PASS" ;
VAL_ 2589283392 LAD2_KomponentenFehler_06 0 "TestComplete_PASS" 1 "TestComplete_FAIL" 2 "TestNotComplete_PASS" ;
VAL_ 2589283392 LAD2_KomponentenFehler_07 0 "TestComplete_PASS" 1 "TestComplete_FAIL" 2 "TestNotComplete_PASS" ;
VAL_ 2589283392 LAD2_KomponentenFehler_08 0 "TestComplete_PASS" 1 "TestComplete_FAIL" 2 "TestNotComplete_PASS" ;
VAL_ 2589283392 LAD2_KomponentenFehler_09 0 "TestComplete_PASS" 1 "TestComplete_FAIL" 2 "TestNotComplete_PASS" ;
VAL_ 2589283392 LAD2_KomponentenFehler_10 0 "TestComplete_PASS" 1 "TestComplete_FAIL" 2 "TestNotComplete_PASS" ;
VAL_ 2589283392 LAD2_KomponentenFehler_11 0 "TestComplete_PASS" 1 "TestComplete_FAIL" 2 "TestNotComplete_PASS" ;
VAL_ 2589283392 LAD2_KomponentenFehler_12 0 "TestComplete_PASS" 1 "TestComplete_FAIL" 2 "TestNotComplete_PASS" ;
VAL_ 2589283392 LAD2_KomponentenFehler_13 0 "TestComplete_PASS" 1 "TestComplete_FAIL" 2 "TestNotComplete_PASS" ;
VAL_ 2589283392 LAD2_KomponentenFehler_14 0 "TestComplete_PASS" 1 "TestComplete_FAIL" 2 "TestNotComplete_PASS" ;
VAL_ 2589283392 LAD2_KomponentenFehler_15 0 "TestComplete_PASS" 1 "TestComplete_FAIL" 2 "TestNotComplete_PASS" ;
VAL_ 2589283392 LAD2_KomponentenFehler_16 0 "TestComplete_PASS" 1 "TestComplete_FAIL" 2 "TestNotComplete_PASS" ;
VAL_ 2589283392 LAD2_KomponentenFehler_17 0 "TestComplete_PASS" 1 "TestComplete_FAIL" 2 "TestNotComplete_PASS" ;
VAL_ 2589283392 LAD2_KomponentenFehler_18 0 "TestComplete_PASS" 1 "TestComplete_FAIL" 2 "TestNotComplete_PASS" ;
VAL_ 2589283392 LAD2_KomponentenFehler_19 0 "TestComplete_PASS" 1 "TestComplete_FAIL" 2 "TestNotComplete_PASS" ;
VAL_ 2589283392 LAD2_KomponentenFehler_20 0 "TestComplete_PASS" 1 "TestComplete_FAIL" 2 "TestNotComplete_PASS" ;
VAL_ 2589283688 LAD2_Version 0 "VR_Release" 1 "HVLM_BTV_Release" 2 "BSSW_BTV_Release" 3 "Reserve" ;
VAL_ 2589283688 LAD2_Version_Index_01 31 "Init" ;
VAL_ 2589283688 LAD2_Version_Index_02 31 "Init" ;
VAL_ 2589283688 LAD2_Version_Index_03 31 "Init" ;
VAL_ 2589283688 LAD2_Version_Index_04 31 "Init" ;
VAL_ 1380 LAD_IstModus 0 "Standby" 1 "AC_Netzladung" 3 "DC_Netzladung" 4 "PreCharge_aktiv" 5 "Fehler" 7 "Init" ;
VAL_ 1380 LAD_AC_Istspannung 510 "Init" 511 "Fehler" ;
VAL_ 1380 LAD_IstSpannung_HV 1022 "Init" 1023 "Fehler" ;
VAL_ 1380 LAD_IstStrom_HV 1022 "Init" 1023 "Fehler" ;
VAL_ 1380 LAD_Status_Spgfreiheit 0 "Init" 1 "HV_Komponente_spannungsfrei" 2 "HV_Komp_nicht_spannungsfrei" 3 "Fehler_nicht_spannungsfrei" ;
VAL_ 1380 LAD_Temperatur 254 "Init" 255 "Fehler" ;
VAL_ 1380 LAD_Verlustleistung 254 "Init" 255 "Fehler" ;
VAL_ 1662 LAD_Abregelung_Temperatur 0 "keine_Begrenzung" 1 "Abregelung_Temp" ;
VAL_ 1662 LAD_Abregelung_IU_Ein_Aus 0 "keine_Abregelung" 1 "Abregelung_UI" ;
VAL_ 1662 LAD_Abregelung_BuchseTemp 0 "keine_Abregelung" 1 "Abregelung_Buchsentemp" ;
VAL_ 1662 LAD_MaxLadLeistung_HV 510 "Init" 511 "Fehler" ;
VAL_ 1662 LAD_PRX_Stromlimit 0 "13_Ampere" 1 "20_Ampere" 2 "32_Ampere" 3 "63_Ampere" 6 "Init" 7 "Fehler" ;
VAL_ 1662 LAD_CP_Erkennung 0 "CP_nicht_erkannt" 1 "CP_erkannt" ;
VAL_ 1662 LAD_Stecker_Verriegelt 0 "nicht_verriegelt" 1 "verriegelt" ;
VAL_ 1662 LAD_Kuehlbedarf 0 "kein_Kuehlbedarf" 1 "geringer_Kuehlbedarf" 2 "mittlerer_Kuehlbedarf" 3 "hoher_Kuehlbedarf" ;
VAL_ 1662 LAD_MaxLadLeistung_HV_Offset 0 "LAD_MaxLadLeistung_HV +0W" 1 "LAD_MaxLadLeistung_HV +25W" 2 "LAD_MaxLadLeistung_HV +50W" 3 "LAD_MaxLadLeistung_HV +75W" ;
VAL_ 1662 LAD_Warnzustand 0 "keine_Warnung" 1 "Warnung_aktiv" ;
VAL_ 1662 LAD_Fehlerzustand 0 "kein_Fehler_aktiv" 1 "Fehler_aktiv_Laden_beendet" ;
VAL_ 2463978642 LAD_SollStrom_HV_Pfad1 254 "Init" 255 "Fehler" ;
VAL_ 2463978642 LAD_SollStrom_HV_Pfad2 254 "Init" 255 "Fehler" ;
VAL_ 2463978642 LAD_SollStrom_HV_Pfad3 254 "Init" 255 "Fehler" ;
VAL_ 2463978643 LAD_AC_MaxStrom_L1 1022 "Init" 1023 "Fehler" ;
VAL_ 2463978643 LAD_AC_MaxStrom_L2 1022 "Init" 1023 "Fehler" ;
VAL_ 2463978643 LAD_AC_MaxStrom_L3 1022 "Init" 1023 "Fehler" ;
VAL_ 2463978643 LAD_Freigabe_LAD2 0 "keine_Freigabe" 1 "Freigabe" ;
VAL_ 2463978643 LAD_Max_LadeSpannung_LAD2 1022 "Init" 1023 "Fehler" ;
VAL_ 2589283663 LAD_PlanAntw_Verlustleistung 4094 "Init" 4095 "Fehler" ;
VAL_ 2589283663 LAD_PlanAntw_Zaehler 14 "Init" 15 "Fehler" ;
VAL_ 2589283415 LAD_CVN_VLD 0 "ungueltig" 1 "gueltig" ;
VAL_ 2589283415 LAD_CALID_Index_01 48 "Init" ;
VAL_ 2589283415 LAD_CALID_Index_05 48 "Init" ;
VAL_ 2589283415 LAD_CALID_Index_09 48 "Init" ;
VAL_ 2589283415 LAD_CALID_Index_13 48 "Init" ;
VAL_ 2589283415 LAD_CALID_Index_02 48 "Init" ;
VAL_ 2589283415 LAD_CALID_Index_06 48 "Init" ;
VAL_ 2589283415 LAD_CALID_Index_10 48 "Init" ;
VAL_ 2589283415 LAD_CALID_Index_14 48 "Init" ;
VAL_ 2589283415 LAD_CALID_Index_03 48 "Init" ;
VAL_ 2589283415 LAD_CALID_Index_07 48 "Init" ;
VAL_ 2589283415 LAD_CALID_Index_11 48 "Init" ;
VAL_ 2589283415 LAD_CALID_Index_15 48 "Init" ;
VAL_ 2589283415 LAD_CALID_Index_04 48 "Init" ;
VAL_ 2589283415 LAD_CALID_Index_08 48 "Init" ;
VAL_ 2589283415 LAD_CALID_Index_12 48 "Init" ;
VAL_ 2589283415 LAD_CALID_Index_16 48 "Init" ;
VAL_ 2589283415 LAD_CVN_Byte_1 0 "Init" ;
VAL_ 2589283415 LAD_CVN_Byte_2 0 "Init" ;
VAL_ 2589283415 LAD_CVN_Byte_3 0 "Init" ;
VAL_ 2589283415 LAD_CVN_Byte_4 0 "Init" ;
VAL_ 2589283472 LAD_KomponentenFehler_01 0 "TestComplete_PASS" 1 "TestComplete_FAIL" 2 "TestNotComplete_PASS" ;
VAL_ 2589283472 LAD_KomponentenFehler_02 0 "TestComplete_PASS" 1 "TestComplete_FAIL" 2 "TestNotComplete_PASS" ;
VAL_ 2589283472 LAD_KomponentenFehler_03 0 "TestComplete_PASS" 1 "TestComplete_FAIL" 2 "TestNotComplete_PASS" ;
VAL_ 2589283472 LAD_KomponentenFehler_04 0 "TestComplete_PASS" 1 "TestComplete_FAIL" 2 "TestNotComplete_PASS" ;
VAL_ 2589283472 LAD_KomponentenFehler_05 0 "TestComplete_PASS" 1 "TestComplete_FAIL" 2 "TestNotComplete_PASS" ;
VAL_ 2589283472 LAD_KomponentenFehler_06 0 "TestComplete_PASS" 1 "TestComplete_FAIL" 2 "TestNotComplete_PASS" ;
VAL_ 2589283472 LAD_KomponentenFehler_07 0 "TestComplete_PASS" 1 "TestComplete_FAIL" 2 "TestNotComplete_PASS" ;
VAL_ 2589283472 LAD_KomponentenFehler_08 0 "TestComplete_PASS" 1 "TestComplete_FAIL" 2 "TestNotComplete_PASS" ;
VAL_ 2589283472 LAD_KomponentenFehler_09 0 "TestComplete_PASS" 1 "TestComplete_FAIL" 2 "TestNotComplete_PASS" ;
VAL_ 2589283472 LAD_KomponentenFehler_10 0 "TestComplete_PASS" 1 "TestComplete_FAIL" 2 "TestNotComplete_PASS" ;
VAL_ 2589283472 LAD_KomponentenFehler_11 0 "TestComplete_PASS" 1 "TestComplete_FAIL" 2 "TestNotComplete_PASS" ;
VAL_ 2589283472 LAD_KomponentenFehler_12 0 "TestComplete_PASS" 1 "TestComplete_FAIL" 2 "TestNotComplete_PASS" ;
VAL_ 2589283472 LAD_KomponentenFehler_13 0 "TestComplete_PASS" 1 "TestComplete_FAIL" 2 "TestNotComplete_PASS" ;
VAL_ 2589283472 LAD_KomponentenFehler_14 0 "TestComplete_PASS" 1 "TestComplete_FAIL" 2 "TestNotComplete_PASS" ;
VAL_ 2589283472 LAD_KomponentenFehler_15 0 "TestComplete_PASS" 1 "TestComplete_FAIL" 2 "TestNotComplete_PASS" ;
VAL_ 2589283472 LAD_KomponentenFehler_16 0 "TestComplete_PASS" 1 "TestComplete_FAIL" 2 "TestNotComplete_PASS" ;
VAL_ 2589283472 LAD_KomponentenFehler_17 0 "TestComplete_PASS" 1 "TestComplete_FAIL" 2 "TestNotComplete_PASS" ;
VAL_ 2589283472 LAD_KomponentenFehler_18 0 "TestComplete_PASS" 1 "TestComplete_FAIL" 2 "TestNotComplete_PASS" ;
VAL_ 2589283472 LAD_KomponentenFehler_19 0 "TestComplete_PASS" 1 "TestComplete_FAIL" 2 "TestNotComplete_PASS" ;
VAL_ 2589283472 LAD_KomponentenFehler_20 0 "TestComplete_PASS" 1 "TestComplete_FAIL" 2 "TestNotComplete_PASS" ;
VAL_ 2589283472 LAD_KomponentenFehler_21 0 "TestComplete_PASS" 1 "TestComplete_FAIL" 2 "TestNotComplete_PASS" ;
VAL_ 2589283472 LAD_KomponentenFehler_22 0 "TestComplete_PASS" 1 "TestComplete_FAIL" 2 "TestNotComplete_PASS" ;
VAL_ 2589283472 LAD_KomponentenFehler_23 0 "TestComplete_PASS" 1 "TestComplete_FAIL" 2 "TestNotComplete_PASS" ;
VAL_ 2589283472 LAD_KomponentenFehler_24 0 "TestComplete_PASS" 1 "TestComplete_FAIL" 2 "TestNotComplete_PASS" ;
VAL_ 2589283472 LAD_KomponentenFehler_25 0 "TestComplete_PASS" 1 "TestComplete_FAIL" 2 "TestNotComplete_PASS" ;
VAL_ 2589283472 LAD_KomponentenFehler_26 0 "TestComplete_PASS" 1 "TestComplete_FAIL" 2 "TestNotComplete_PASS" ;
VAL_ 2589283472 LAD_KomponentenFehler_27 0 "TestComplete_PASS" 1 "TestComplete_FAIL" 2 "TestNotComplete_PASS" ;
VAL_ 2589283472 LAD_KomponentenFehler_28 0 "TestComplete_PASS" 1 "TestComplete_FAIL" 2 "TestNotComplete_PASS" ;
VAL_ 2589283472 LAD_KomponentenFehler_29 0 "TestComplete_PASS" 1 "TestComplete_FAIL" 2 "TestNotComplete_PASS" ;
VAL_ 2589283472 LAD_KomponentenFehler_30 0 "TestComplete_PASS" 1 "TestComplete_FAIL" 2 "TestNotComplete_PASS" ;
VAL_ 2589283472 LAD_KomponentenFehler_31 0 "TestComplete_PASS" 1 "TestComplete_FAIL" 2 "TestNotComplete_PASS" ;
VAL_ 2589283472 LAD_KomponentenFehler_32 0 "TestComplete_PASS" 1 "TestComplete_FAIL" 2 "TestNotComplete_PASS" ;
